VERSION "canboat-NMEA2000-curated"

NS_ :

BS_:

BU_: Vector__XXX
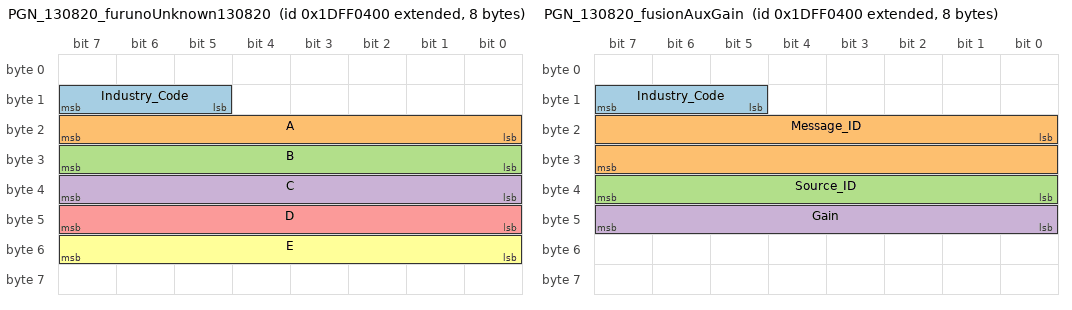
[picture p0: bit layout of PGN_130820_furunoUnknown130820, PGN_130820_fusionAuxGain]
BO_ 2650735616 PGN_130820_furunoUnknown130820: 8 Vector__XXX
 SG_ Industry_Code : 13|3@1+ (1.0,0) [0|7] "" Vector__XXX
 SG_ A : 16|8@1+ (1.0,0) [0|255] "" Vector__XXX
 SG_ B : 24|8@1+ (1.0,0) [0|255] "" Vector__XXX
 SG_ C : 32|8@1+ (1.0,0) [0|255] "" Vector__XXX
 SG_ D : 40|8@1+ (1.0,0) [0|255] "" Vector__XXX
 SG_ E : 48|8@1+ (1.0,0) [0|255] "" Vector__XXX

BO_ 2650735616 PGN_130820_fusionAlbumName: 10 Vector__XXX
 SG_ Industry_Code : 13|3@1+ (1.0,0) [0|7] "" Vector__XXX
 SG_ Message_ID : 16|16@1+ (1.0,0) [0|65535] "" Vector__XXX
 SG_ Source_ID : 32|8@1+ (1.0,0) [0|255] "" Vector__XXX
 SG_ Index : 40|32@1+ (1.0,0) [0|4294967295] "" Vector__XXX
 SG_ Album : 72|8@1+ (1.0,0) [0|255] "" Vector__XXX

BO_ 2650735616 PGN_130820_fusionArtistName: 10 Vector__XXX
 SG_ Industry_Code : 13|3@1+ (1.0,0) [0|7] "" Vector__XXX
 SG_ Message_ID : 16|16@1+ (1.0,0) [0|65535] "" Vector__XXX
 SG_ Source_ID : 32|8@1+ (1.0,0) [0|255] "" Vector__XXX
 SG_ Index : 40|32@1+ (1.0,0) [0|4294967295] "" Vector__XXX
 SG_ Artist : 72|8@1+ (1.0,0) [0|255] "" Vector__XXX

BO_ 2650735616 PGN_130820_fusionAuxGain: 8 Vector__XXX
 SG_ Industry_Code : 13|3@1+ (1.0,0) [0|7] "" Vector__XXX
 SG_ Message_ID : 16|16@1+ (1.0,0) [0|65535] "" Vector__XXX
 SG_ Source_ID : 32|8@1+ (1.0,0) [0|255] "" Vector__XXX
 SG_ Gain : 40|8@1+ (1.0,0) [0|255] "" Vector__XXX

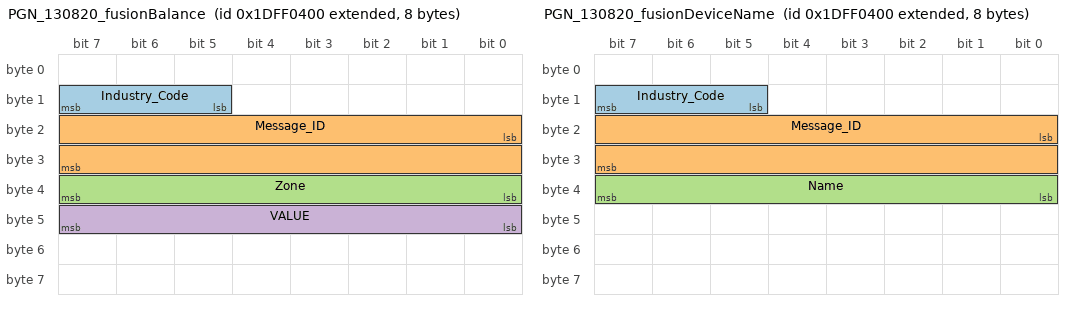
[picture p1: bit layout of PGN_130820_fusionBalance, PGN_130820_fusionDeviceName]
BO_ 2650735616 PGN_130820_fusionBalance: 8 Vector__XXX
 SG_ Industry_Code : 13|3@1+ (1.0,0) [0|7] "" Vector__XXX
 SG_ Message_ID : 16|16@1+ (1.0,0) [0|65535] "" Vector__XXX
 SG_ Zone : 32|8@1+ (1.0,0) [0|255] "" Vector__XXX
 SG_ VALUE : 40|8@1+ (1.0,0) [0|255] "" Vector__XXX

BO_ 2650735616 PGN_130820_fusionCapabilities: 14 Vector__XXX
 SG_ Industry_Code : 13|3@1+ (1.0,0) [0|7] "" Vector__XXX
 SG_ Message_ID : 16|16@1+ (1.0,0) [0|65535] "" Vector__XXX
 SG_ Zone_1 : 32|16@1+ (1.0,0) [0|65535] "" Vector__XXX
 SG_ Zone_2 : 48|16@1+ (1.0,0) [0|65535] "" Vector__XXX
 SG_ Zone_3 : 64|16@1+ (1.0,0) [0|65535] "" Vector__XXX
 SG_ Zone_4 : 80|16@1+ (1.0,0) [0|65535] "" Vector__XXX
 SG_ Global : 96|16@1+ (1.0,0) [0|65535] "" Vector__XXX

BO_ 2650735616 PGN_130820_fusionDeviceName: 8 Vector__XXX
 SG_ Industry_Code : 13|3@1+ (1.0,0) [0|7] "" Vector__XXX
 SG_ Message_ID : 16|16@1+ (1.0,0) [0|65535] "" Vector__XXX
 SG_ Name : 32|8@1+ (1.0,0) [0|255] "" Vector__XXX

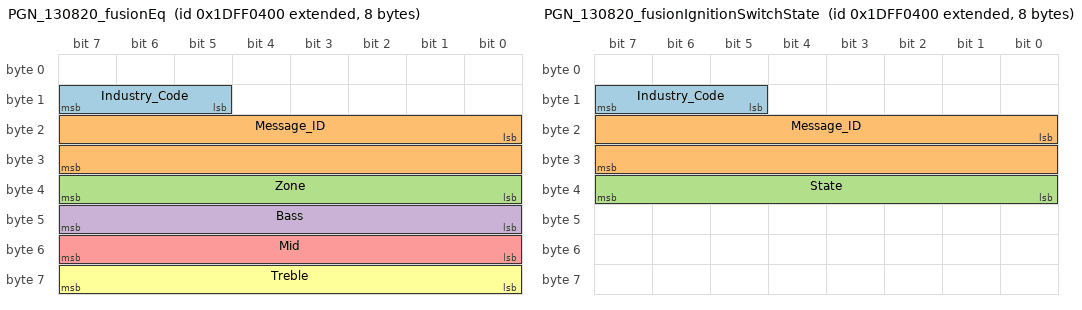
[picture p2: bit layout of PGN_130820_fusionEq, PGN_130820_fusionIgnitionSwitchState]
BO_ 2650735616 PGN_130820_fusionEq: 8 Vector__XXX
 SG_ Industry_Code : 13|3@1+ (1.0,0) [0|7] "" Vector__XXX
 SG_ Message_ID : 16|16@1+ (1.0,0) [0|65535] "" Vector__XXX
 SG_ Zone : 32|8@1+ (1.0,0) [0|255] "" Vector__XXX
 SG_ Bass : 40|8@1- (1.0,0) [-128|127] "" Vector__XXX
 SG_ Mid : 48|8@1- (1.0,0) [-128|127] "" Vector__XXX
 SG_ Treble : 56|8@1- (1.0,0) [-128|127] "" Vector__XXX

BO_ 2650735616 PGN_130820_fusionIgnitionSwitchState: 8 Vector__XXX
 SG_ Industry_Code : 13|3@1+ (1.0,0) [0|7] "" Vector__XXX
 SG_ Message_ID : 16|16@1+ (1.0,0) [0|65535] "" Vector__XXX
 SG_ State : 32|8@1+ (1.0,0) [0|255] "" Vector__XXX

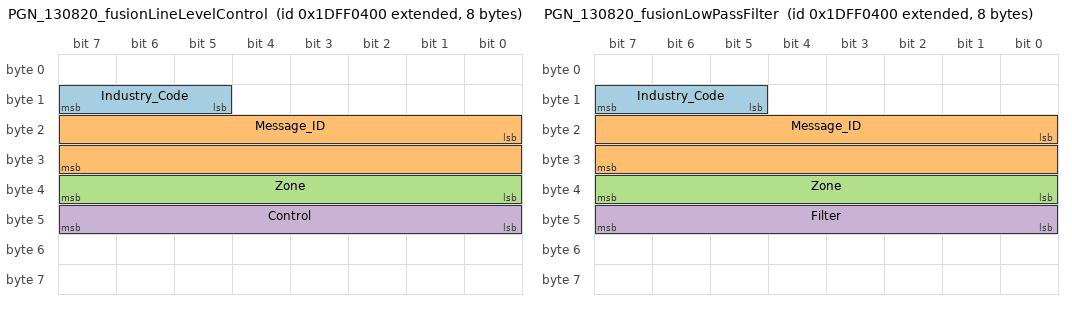
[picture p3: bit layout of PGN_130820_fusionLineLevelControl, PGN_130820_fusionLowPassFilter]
BO_ 2650735616 PGN_130820_fusionLineLevelControl: 8 Vector__XXX
 SG_ Industry_Code : 13|3@1+ (1.0,0) [0|7] "" Vector__XXX
 SG_ Message_ID : 16|16@1+ (1.0,0) [0|65535] "" Vector__XXX
 SG_ Zone : 32|8@1+ (1.0,0) [0|255] "" Vector__XXX
 SG_ Control : 40|8@1+ (1.0,0) [0|255] "" Vector__XXX

BO_ 2650735616 PGN_130820_fusionLowPassFilter: 8 Vector__XXX
 SG_ Industry_Code : 13|3@1+ (1.0,0) [0|7] "" Vector__XXX
 SG_ Message_ID : 16|16@1+ (1.0,0) [0|65535] "" Vector__XXX
 SG_ Zone : 32|8@1+ (1.0,0) [0|255] "" Vector__XXX
 SG_ Filter : 40|8@1+ (1.0,0) [0|255] "" Vector__XXX

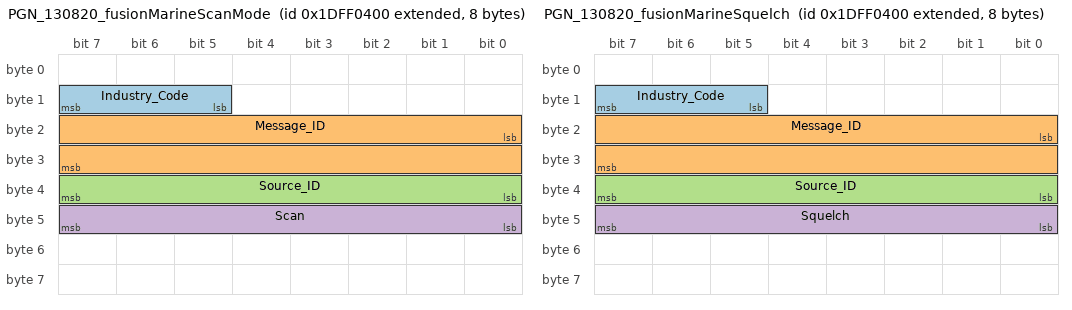
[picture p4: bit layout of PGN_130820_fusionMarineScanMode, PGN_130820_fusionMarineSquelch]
BO_ 2650735616 PGN_130820_fusionMarineScanMode: 8 Vector__XXX
 SG_ Industry_Code : 13|3@1+ (1.0,0) [0|7] "" Vector__XXX
 SG_ Message_ID : 16|16@1+ (1.0,0) [0|65535] "" Vector__XXX
 SG_ Source_ID : 32|8@1+ (1.0,0) [0|255] "" Vector__XXX
 SG_ Scan : 40|8@1+ (1.0,0) [0|255] "" Vector__XXX

BO_ 2650735616 PGN_130820_fusionMarineSquelch: 8 Vector__XXX
 SG_ Industry_Code : 13|3@1+ (1.0,0) [0|7] "" Vector__XXX
 SG_ Message_ID : 16|16@1+ (1.0,0) [0|65535] "" Vector__XXX
 SG_ Source_ID : 32|8@1+ (1.0,0) [0|255] "" Vector__XXX
 SG_ Squelch : 40|8@1+ (1.0,0) [0|255] "" Vector__XXX

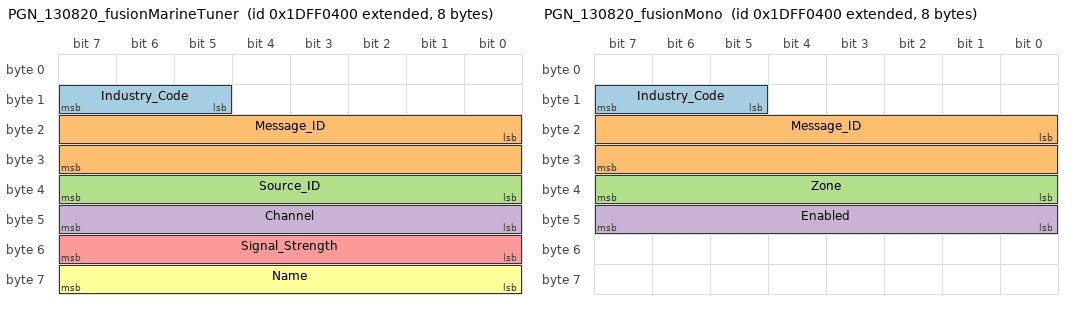
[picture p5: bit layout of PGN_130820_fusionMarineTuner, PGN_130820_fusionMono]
BO_ 2650735616 PGN_130820_fusionMarineTuner: 8 Vector__XXX
 SG_ Industry_Code : 13|3@1+ (1.0,0) [0|7] "" Vector__XXX
 SG_ Message_ID : 16|16@1+ (1.0,0) [0|65535] "" Vector__XXX
 SG_ Source_ID : 32|8@1+ (1.0,0) [0|255] "" Vector__XXX
 SG_ Channel : 40|8@1+ (1.0,0) [0|255] "" Vector__XXX
 SG_ Signal_Strength : 48|8@1+ (1.0,0) [0|255] "" Vector__XXX
 SG_ Name : 56|8@1+ (1.0,0) [0|255] "" Vector__XXX

BO_ 2650735616 PGN_130820_fusionMedia: 23 Vector__XXX
 SG_ Industry_Code : 13|3@1+ (1.0,0) [0|7] "" Vector__XXX
 SG_ Message_ID : 16|16@1+ (1.0,0) [0|65535] "" Vector__XXX
 SG_ Source_ID : 32|8@1+ (1.0,0) [0|255] "" Vector__XXX
 SG_ Flags : 40|16@1+ (1.0,0) [0|65535] "" Vector__XXX
 SG_ Track__ : 56|32@1+ (1.0,0) [0|4294967295] "" Vector__XXX
 SG_ Track_Count : 88|32@1+ (1.0,0) [0|4294967295] "" Vector__XXX
 SG_ Length : 120|32@1+ (0.001,0) [0.0|4294967.295] "" Vector__XXX
 SG_ Position_in_track : 152|32@1+ (0.001,0) [0.0|4294967.295] "" Vector__XXX

BO_ 2650735616 PGN_130820_fusionMenuActionStatus: 11 Vector__XXX
 SG_ Industry_Code : 13|3@1+ (1.0,0) [0|7] "" Vector__XXX
 SG_ Message_ID : 16|16@1+ (1.0,0) [0|65535] "" Vector__XXX
 SG_ Source_ID : 32|8@1+ (1.0,0) [0|255] "" Vector__XXX
 SG_ Item_Index : 40|32@1+ (1.0,0) [0|4294967295] "" Vector__XXX
 SG_ Action : 72|8@1+ (1.0,0) [0|255] "" Vector__XXX
 SG_ Lock_ID : 80|8@1+ (1.0,0) [0|255] "" Vector__XXX

BO_ 2650735616 PGN_130820_fusionMenuCount: 10 Vector__XXX
 SG_ Industry_Code : 13|3@1+ (1.0,0) [0|7] "" Vector__XXX
 SG_ Message_ID : 16|16@1+ (1.0,0) [0|65535] "" Vector__XXX
 SG_ Source_ID : 32|8@1+ (1.0,0) [0|255] "" Vector__XXX
 SG_ Count : 40|32@1+ (1.0,0) [0|4294967295] "" Vector__XXX
 SG_ Lock_ID : 72|8@1+ (1.0,0) [0|255] "" Vector__XXX

BO_ 2650735616 PGN_130820_fusionMenuItem: 12 Vector__XXX
 SG_ Industry_Code : 13|3@1+ (1.0,0) [0|7] "" Vector__XXX
 SG_ Message_ID : 16|16@1+ (1.0,0) [0|65535] "" Vector__XXX
 SG_ Source_ID : 32|8@1+ (1.0,0) [0|255] "" Vector__XXX
 SG_ Item_Index : 40|32@1+ (1.0,0) [0|4294967295] "" Vector__XXX
 SG_ Flags : 72|8@1+ (1.0,0) [0|255] "" Vector__XXX
 SG_ Lock_ID : 80|8@1+ (1.0,0) [0|255] "" Vector__XXX
 SG_ Text : 88|8@1+ (1.0,0) [0|255] "" Vector__XXX

BO_ 2650735616 PGN_130820_fusionMenuLockId: 9 Vector__XXX
 SG_ Industry_Code : 13|3@1+ (1.0,0) [0|7] "" Vector__XXX
 SG_ Message_ID : 16|16@1+ (1.0,0) [0|65535] "" Vector__XXX
 SG_ Lock_Id : 32|32@1+ (1.0,0) [0|4294967295] "" Vector__XXX
 SG_ Flags : 64|8@1+ (1.0,0) [0|255] "" Vector__XXX

BO_ 2650735616 PGN_130820_fusionMono: 8 Vector__XXX
 SG_ Industry_Code : 13|3@1+ (1.0,0) [0|7] "" Vector__XXX
 SG_ Message_ID : 16|16@1+ (1.0,0) [0|65535] "" Vector__XXX
 SG_ Zone : 32|8@1+ (1.0,0) [0|255] "" Vector__XXX
 SG_ Enabled : 40|8@1+ (1.0,0) [0|255] "" Vector__XXX

BO_ 2650735616 PGN_130820_fusionMultiroom: 9 Vector__XXX
 SG_ Industry_Code : 13|3@1+ (1.0,0) [0|7] "" Vector__XXX
 SG_ Message_ID : 16|16@1+ (1.0,0) [0|65535] "" Vector__XXX
 SG_ Enabled : 32|8@1+ (1.0,0) [0|255] "" Vector__XXX
 SG_ IP_Address_1 : 40|8@1+ (1.0,0) [0|255] "" Vector__XXX
 SG_ IP_Address_2 : 48|8@1+ (1.0,0) [0|255] "" Vector__XXX
 SG_ IP_Address_3 : 56|8@1+ (1.0,0) [0|255] "" Vector__XXX
 SG_ IP_Address_4 : 64|8@1+ (1.0,0) [0|255] "" Vector__XXX

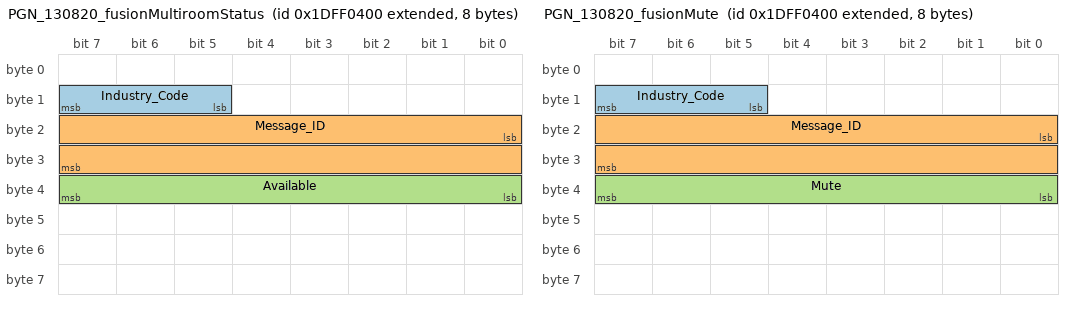
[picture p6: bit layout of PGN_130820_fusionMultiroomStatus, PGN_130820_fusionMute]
BO_ 2650735616 PGN_130820_fusionMultiroomStatus: 8 Vector__XXX
 SG_ Industry_Code : 13|3@1+ (1.0,0) [0|7] "" Vector__XXX
 SG_ Message_ID : 16|16@1+ (1.0,0) [0|65535] "" Vector__XXX
 SG_ Available : 32|8@1+ (1.0,0) [0|255] "" Vector__XXX

BO_ 2650735616 PGN_130820_fusionMute: 8 Vector__XXX
 SG_ Industry_Code : 13|3@1+ (1.0,0) [0|7] "" Vector__XXX
 SG_ Message_ID : 16|16@1+ (1.0,0) [0|65535] "" Vector__XXX
 SG_ Mute : 32|8@1+ (1.0,0) [0|255] "" Vector__XXX

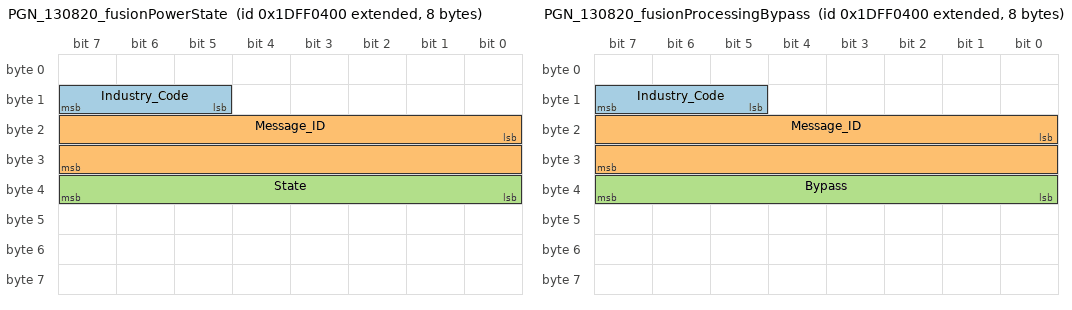
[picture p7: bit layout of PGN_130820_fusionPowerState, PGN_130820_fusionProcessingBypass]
BO_ 2650735616 PGN_130820_fusionPowerState: 8 Vector__XXX
 SG_ Industry_Code : 13|3@1+ (1.0,0) [0|7] "" Vector__XXX
 SG_ Message_ID : 16|16@1+ (1.0,0) [0|65535] "" Vector__XXX
 SG_ State : 32|8@1+ (1.0,0) [0|255] "" Vector__XXX

BO_ 2650735616 PGN_130820_fusionProcessingBypass: 8 Vector__XXX
 SG_ Industry_Code : 13|3@1+ (1.0,0) [0|7] "" Vector__XXX
 SG_ Message_ID : 16|16@1+ (1.0,0) [0|65535] "" Vector__XXX
 SG_ Bypass : 32|8@1+ (1.0,0) [0|255] "" Vector__XXX

BO_ 2650735616 PGN_130820_fusionRdsData: 39 Vector__XXX
 SG_ Industry_Code : 13|3@1+ (1.0,0) [0|7] "" Vector__XXX
 SG_ Message_ID : 16|16@1+ (1.0,0) [0|65535] "" Vector__XXX
 SG_ Source_ID : 32|8@1+ (1.0,0) [0|255] "" Vector__XXX
 SG_ RDS_Type : 40|8@1+ (1.0,0) [0|255] "" Vector__XXX
 SG_ Programme_Type : 48|8@1+ (1.0,0) [0|255] "" Vector__XXX
 SG_ RDS : 56|256@1+ (1.0,0) [0|115792089237316195423570985008687907853269984665640564039457584007913129639935] "" Vector__XXX

BO_ 2650735616 PGN_130820_fusionSetting: 12 Vector__XXX
 SG_ Industry_Code : 13|3@1+ (1.0,0) [0|7] "" Vector__XXX
 SG_ Message_ID : 16|16@1+ (1.0,0) [0|65535] "" Vector__XXX
 SG_ ID : 32|32@1+ (1.0,0) [0|4294967295] "" Vector__XXX
 SG_ Value : 64|32@1+ (1.0,0) [0|4294967295] "" Vector__XXX

BO_ 2650735616 PGN_130820_fusionSettings: 9 Vector__XXX
 SG_ Industry_Code : 13|3@1+ (1.0,0) [0|7] "" Vector__XXX
 SG_ Message_ID : 16|16@1+ (1.0,0) [0|65535] "" Vector__XXX
 SG_ Count : 32|32@1+ (1.0,0) [0|4294967295] "" Vector__XXX
 SG_ field64 : 64|8@1+ (1.0,0) [0|255] "" Vector__XXX

BO_ 2650735616 PGN_130820_fusionSiriusxm: 10 Vector__XXX
 SG_ Industry_Code : 13|3@1+ (1.0,0) [0|7] "" Vector__XXX
 SG_ Message_ID : 16|16@1+ (1.0,0) [0|65535] "" Vector__XXX
 SG_ Source_ID : 32|8@1+ (1.0,0) [0|255] "" Vector__XXX
 SG_ Com_State : 40|8@1+ (1.0,0) [0|255] "" Vector__XXX
 SG_ Alert : 48|8@1+ (1.0,0) [0|255] "" Vector__XXX
 SG_ Advisory_Channel : 56|16@1+ (1.0,0) [0|65535] "" Vector__XXX
 SG_ Tuning_Mode : 72|8@1+ (1.0,0) [0|255] "" Vector__XXX

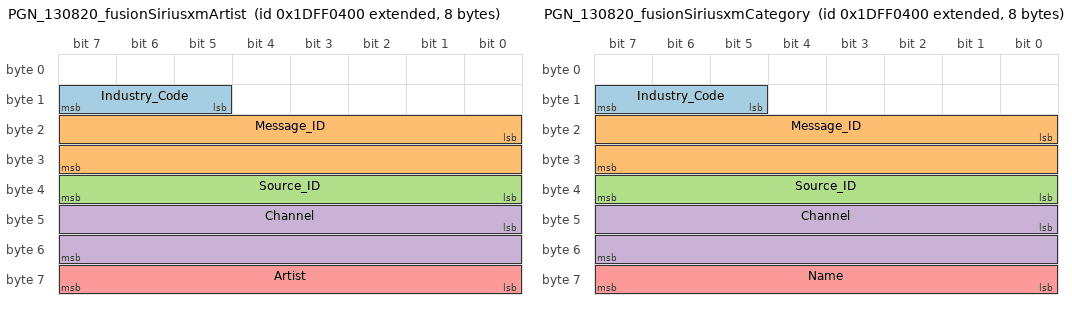
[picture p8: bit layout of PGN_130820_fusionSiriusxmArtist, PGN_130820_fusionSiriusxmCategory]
BO_ 2650735616 PGN_130820_fusionSiriusxmArtist: 8 Vector__XXX
 SG_ Industry_Code : 13|3@1+ (1.0,0) [0|7] "" Vector__XXX
 SG_ Message_ID : 16|16@1+ (1.0,0) [0|65535] "" Vector__XXX
 SG_ Source_ID : 32|8@1+ (1.0,0) [0|255] "" Vector__XXX
 SG_ Channel : 40|16@1+ (1.0,0) [0|65535] "" Vector__XXX
 SG_ Artist : 56|8@1+ (1.0,0) [0|255] "" Vector__XXX

BO_ 2650735616 PGN_130820_fusionSiriusxmCategory: 8 Vector__XXX
 SG_ Industry_Code : 13|3@1+ (1.0,0) [0|7] "" Vector__XXX
 SG_ Message_ID : 16|16@1+ (1.0,0) [0|65535] "" Vector__XXX
 SG_ Source_ID : 32|8@1+ (1.0,0) [0|255] "" Vector__XXX
 SG_ Channel : 40|16@1+ (1.0,0) [0|65535] "" Vector__XXX
 SG_ Name : 56|8@1+ (1.0,0) [0|255] "" Vector__XXX

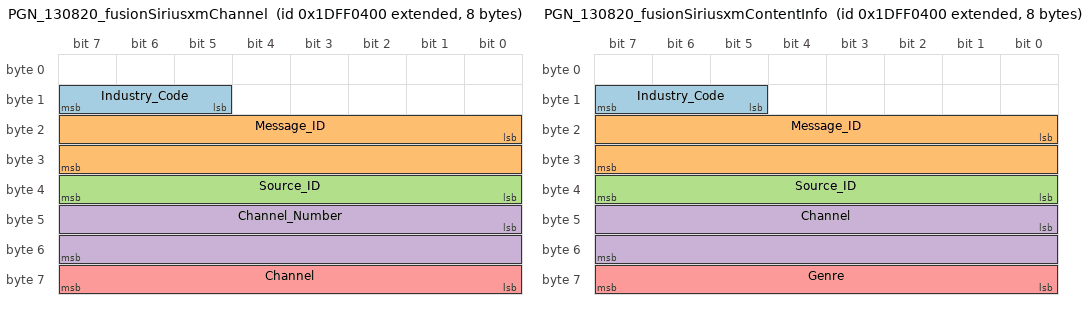
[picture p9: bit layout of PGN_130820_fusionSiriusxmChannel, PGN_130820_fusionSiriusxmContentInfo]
BO_ 2650735616 PGN_130820_fusionSiriusxmChannel: 8 Vector__XXX
 SG_ Industry_Code : 13|3@1+ (1.0,0) [0|7] "" Vector__XXX
 SG_ Message_ID : 16|16@1+ (1.0,0) [0|65535] "" Vector__XXX
 SG_ Source_ID : 32|8@1+ (1.0,0) [0|255] "" Vector__XXX
 SG_ Channel_Number : 40|16@1+ (1.0,0) [0|65535] "" Vector__XXX
 SG_ Channel : 56|8@1+ (1.0,0) [0|255] "" Vector__XXX

BO_ 2650735616 PGN_130820_fusionSiriusxmContentInfo: 8 Vector__XXX
 SG_ Industry_Code : 13|3@1+ (1.0,0) [0|7] "" Vector__XXX
 SG_ Message_ID : 16|16@1+ (1.0,0) [0|65535] "" Vector__XXX
 SG_ Source_ID : 32|8@1+ (1.0,0) [0|255] "" Vector__XXX
 SG_ Channel : 40|16@1+ (1.0,0) [0|65535] "" Vector__XXX
 SG_ Genre : 56|8@1+ (1.0,0) [0|255] "" Vector__XXX

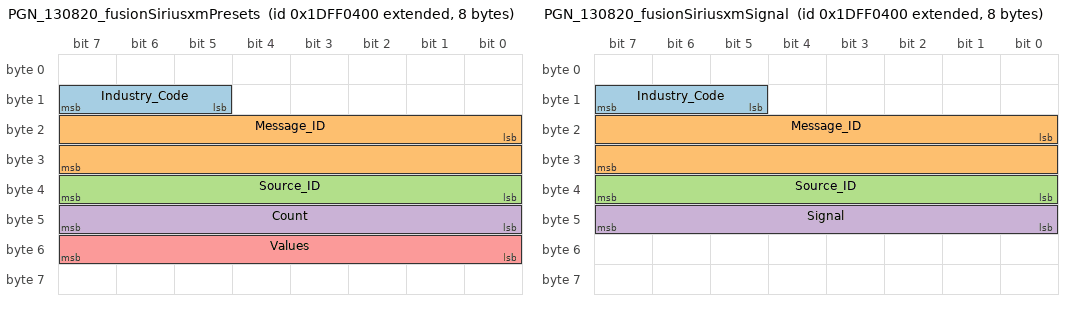
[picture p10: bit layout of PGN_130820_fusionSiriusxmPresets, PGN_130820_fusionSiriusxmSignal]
BO_ 2650735616 PGN_130820_fusionSiriusxmPresets: 8 Vector__XXX
 SG_ Industry_Code : 13|3@1+ (1.0,0) [0|7] "" Vector__XXX
 SG_ Message_ID : 16|16@1+ (1.0,0) [0|65535] "" Vector__XXX
 SG_ Source_ID : 32|8@1+ (1.0,0) [0|255] "" Vector__XXX
 SG_ Count : 40|8@1+ (1.0,0) [0|255] "" Vector__XXX
 SG_ Values : 48|8@1+ (1.0,0) [0|255] "" Vector__XXX

BO_ 2650735616 PGN_130820_fusionSiriusxmSignal: 8 Vector__XXX
 SG_ Industry_Code : 13|3@1+ (1.0,0) [0|7] "" Vector__XXX
 SG_ Message_ID : 16|16@1+ (1.0,0) [0|65535] "" Vector__XXX
 SG_ Source_ID : 32|8@1+ (1.0,0) [0|255] "" Vector__XXX
 SG_ Signal : 40|8@1+ (1.0,0) [0|255] "" Vector__XXX

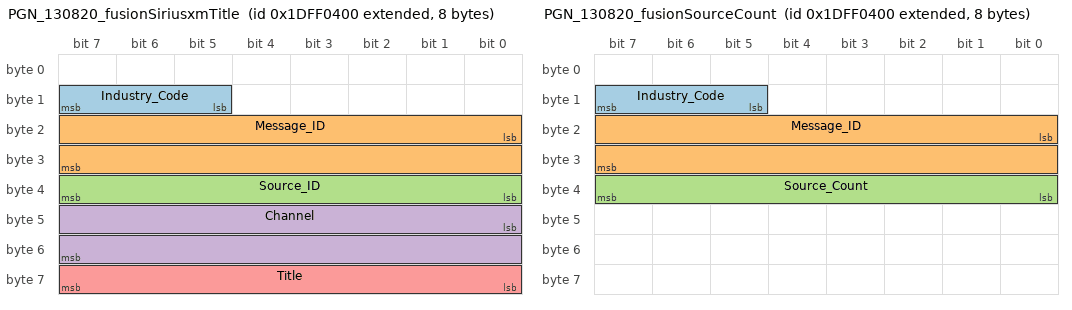
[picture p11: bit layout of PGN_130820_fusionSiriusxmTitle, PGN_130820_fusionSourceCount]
BO_ 2650735616 PGN_130820_fusionSiriusxmTitle: 8 Vector__XXX
 SG_ Industry_Code : 13|3@1+ (1.0,0) [0|7] "" Vector__XXX
 SG_ Message_ID : 16|16@1+ (1.0,0) [0|65535] "" Vector__XXX
 SG_ Source_ID : 32|8@1+ (1.0,0) [0|255] "" Vector__XXX
 SG_ Channel : 40|16@1+ (1.0,0) [0|65535] "" Vector__XXX
 SG_ Title : 56|8@1+ (1.0,0) [0|255] "" Vector__XXX

BO_ 2650735616 PGN_130820_fusionSource: 9 Vector__XXX
 SG_ Industry_Code : 13|3@1+ (1.0,0) [0|7] "" Vector__XXX
 SG_ Message_ID : 16|16@1+ (1.0,0) [0|65535] "" Vector__XXX
 SG_ Source_ID : 32|8@1+ (1.0,0) [0|255] "" Vector__XXX
 SG_ Current_Source_ID : 40|8@1+ (1.0,0) [0|255] "" Vector__XXX
 SG_ Source_Type : 48|8@1+ (1.0,0) [0|255] "" Vector__XXX
 SG_ Flags : 56|8@1+ (1.0,0) [0|255] "" Vector__XXX
 SG_ Source : 64|8@1+ (1.0,0) [0|255] "" Vector__XXX

BO_ 2650735616 PGN_130820_fusionSourceCount: 8 Vector__XXX
 SG_ Industry_Code : 13|3@1+ (1.0,0) [0|7] "" Vector__XXX
 SG_ Message_ID : 16|16@1+ (1.0,0) [0|65535] "" Vector__XXX
 SG_ Source_Count : 32|8@1+ (1.0,0) [0|255] "" Vector__XXX

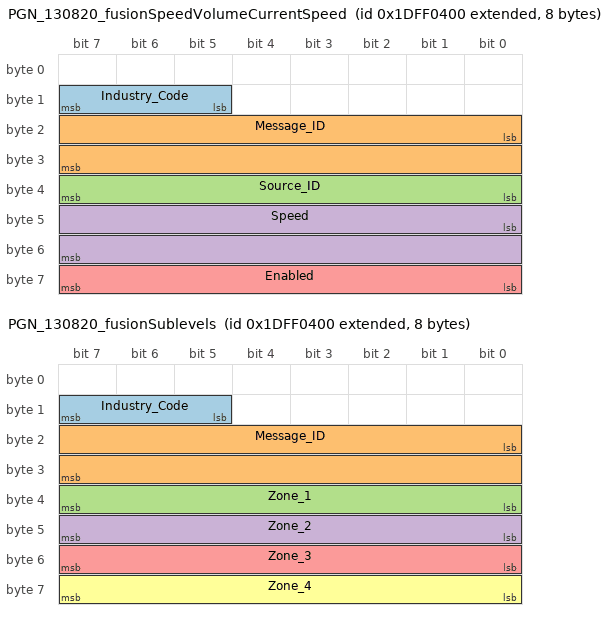
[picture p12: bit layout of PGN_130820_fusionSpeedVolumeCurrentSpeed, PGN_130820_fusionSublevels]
BO_ 2650735616 PGN_130820_fusionSpeedVolumeCurrentSpeed: 8 Vector__XXX
 SG_ Industry_Code : 13|3@1+ (1.0,0) [0|7] "" Vector__XXX
 SG_ Message_ID : 16|16@1+ (1.0,0) [0|65535] "" Vector__XXX
 SG_ Source_ID : 32|8@1+ (1.0,0) [0|255] "" Vector__XXX
 SG_ Speed : 40|16@1+ (1.0,0) [0|65535] "" Vector__XXX
 SG_ Enabled : 56|8@1+ (1.0,0) [0|255] "" Vector__XXX

BO_ 2650735616 PGN_130820_fusionSublevels: 8 Vector__XXX
 SG_ Industry_Code : 13|3@1+ (1.0,0) [0|7] "" Vector__XXX
 SG_ Message_ID : 16|16@1+ (1.0,0) [0|65535] "" Vector__XXX
 SG_ Zone_1 : 32|8@1+ (1.0,0) [0|255] "" Vector__XXX
 SG_ Zone_2 : 40|8@1+ (1.0,0) [0|255] "" Vector__XXX
 SG_ Zone_3 : 48|8@1+ (1.0,0) [0|255] "" Vector__XXX
 SG_ Zone_4 : 56|8@1+ (1.0,0) [0|255] "" Vector__XXX

BO_ 2650735616 PGN_130820_fusionTrackName: 10 Vector__XXX
 SG_ Industry_Code : 13|3@1+ (1.0,0) [0|7] "" Vector__XXX
 SG_ Message_ID : 16|16@1+ (1.0,0) [0|65535] "" Vector__XXX
 SG_ Source_ID : 32|8@1+ (1.0,0) [0|255] "" Vector__XXX
 SG_ Index : 40|32@1+ (1.0,0) [0|4294967295] "" Vector__XXX
 SG_ Track : 72|8@1+ (1.0,0) [0|255] "" Vector__XXX

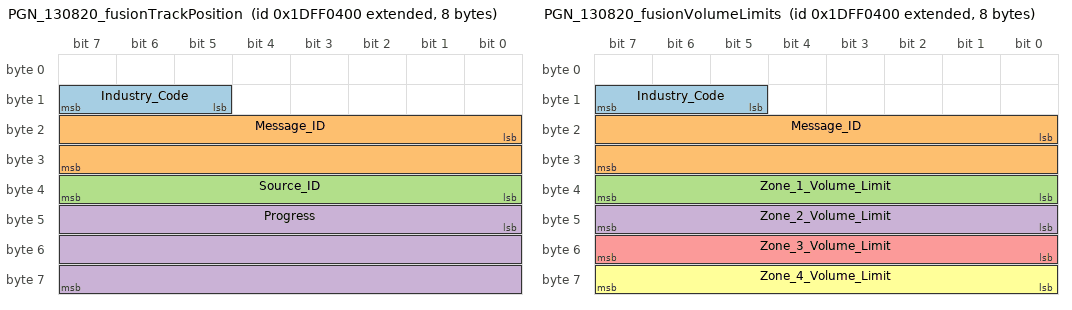
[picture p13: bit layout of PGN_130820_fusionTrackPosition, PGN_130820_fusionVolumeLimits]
BO_ 2650735616 PGN_130820_fusionTrackPosition: 8 Vector__XXX
 SG_ Industry_Code : 13|3@1+ (1.0,0) [0|7] "" Vector__XXX
 SG_ Message_ID : 16|16@1+ (1.0,0) [0|65535] "" Vector__XXX
 SG_ Source_ID : 32|8@1+ (1.0,0) [0|255] "" Vector__XXX
 SG_ Progress : 40|24@1+ (0.001,0) [0.0|16777.215] "" Vector__XXX

BO_ 2650735616 PGN_130820_fusionTuner: 12 Vector__XXX
 SG_ Industry_Code : 13|3@1+ (1.0,0) [0|7] "" Vector__XXX
 SG_ Message_ID : 16|16@1+ (1.0,0) [0|65535] "" Vector__XXX
 SG_ Source_ID : 32|8@1+ (1.0,0) [0|255] "" Vector__XXX
 SG_ Scanning : 40|8@1+ (1.0,0) [0|255] "" Vector__XXX
 SG_ Frequency : 48|32@1+ (1.0,0) [0|4294967295] "" Vector__XXX
 SG_ Signal_Strength : 80|8@1+ (1.0,0) [0|255] "" Vector__XXX
 SG_ Track : 88|8@1+ (1.0,0) [0|255] "" Vector__XXX

BO_ 2650735616 PGN_130820_fusionUsbRepeatStatus: 12 Vector__XXX
 SG_ Industry_Code : 13|3@1+ (1.0,0) [0|7] "" Vector__XXX
 SG_ Message_ID : 16|16@1+ (1.0,0) [0|65535] "" Vector__XXX
 SG_ ID : 32|32@1+ (1.0,0) [0|4294967295] "" Vector__XXX
 SG_ Status : 64|32@1+ (1.0,0) [0|4294967295] "" Vector__XXX

BO_ 2650735616 PGN_130820_fusionVersions: 11 Vector__XXX
 SG_ Industry_Code : 13|3@1+ (1.0,0) [0|7] "" Vector__XXX
 SG_ Message_ID : 16|16@1+ (1.0,0) [0|65535] "" Vector__XXX
 SG_ HW_Version_Major : 32|16@1+ (1.0,0) [0|65535] "" Vector__XXX
 SG_ HW_Version_Minor : 48|16@1+ (1.0,0) [0|65535] "" Vector__XXX
 SG_ SW_Version_Major : 64|8@1+ (1.0,0) [0|255] "" Vector__XXX
 SG_ SW_Version_Minor : 72|8@1+ (1.0,0) [0|255] "" Vector__XXX
 SG_ Build_Number : 80|8@1+ (1.0,0) [0|255] "" Vector__XXX

BO_ 2650735616 PGN_130820_fusionVolumeLimits: 8 Vector__XXX
 SG_ Industry_Code : 13|3@1+ (1.0,0) [0|7] "" Vector__XXX
 SG_ Message_ID : 16|16@1+ (1.0,0) [0|65535] "" Vector__XXX
 SG_ Zone_1_Volume_Limit : 32|8@1+ (1.0,0) [0|255] "" Vector__XXX
 SG_ Zone_2_Volume_Limit : 40|8@1+ (1.0,0) [0|255] "" Vector__XXX
 SG_ Zone_3_Volume_Limit : 48|8@1+ (1.0,0) [0|255] "" Vector__XXX
 SG_ Zone_4_Volume_Limit : 56|8@1+ (1.0,0) [0|255] "" Vector__XXX

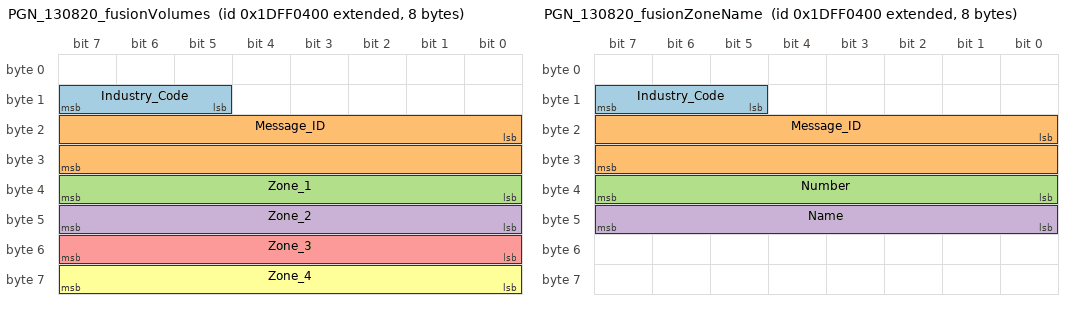
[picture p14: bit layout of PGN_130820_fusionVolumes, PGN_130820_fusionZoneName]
BO_ 2650735616 PGN_130820_fusionVolumes: 8 Vector__XXX
 SG_ Industry_Code : 13|3@1+ (1.0,0) [0|7] "" Vector__XXX
 SG_ Message_ID : 16|16@1+ (1.0,0) [0|65535] "" Vector__XXX
 SG_ Zone_1 : 32|8@1+ (1.0,0) [0|255] "" Vector__XXX
 SG_ Zone_2 : 40|8@1+ (1.0,0) [0|255] "" Vector__XXX
 SG_ Zone_3 : 48|8@1+ (1.0,0) [0|255] "" Vector__XXX
 SG_ Zone_4 : 56|8@1+ (1.0,0) [0|255] "" Vector__XXX

BO_ 2650735616 PGN_130820_fusionZoneName: 8 Vector__XXX
 SG_ Industry_Code : 13|3@1+ (1.0,0) [0|7] "" Vector__XXX
 SG_ Message_ID : 16|16@1+ (1.0,0) [0|65535] "" Vector__XXX
 SG_ Number : 32|8@1+ (1.0,0) [0|255] "" Vector__XXX
 SG_ Name : 40|8@1+ (1.0,0) [0|255] "" Vector__XXX

BO_ 2650735616 PGN_130820_maretronAlertResponse: 27 Vector__XXX
 SG_ Industry_Code : 13|3@1+ (1.0,0) [0|7] "" Vector__XXX
 SG_ Alert_Type : 16|4@1+ (1.0,0) [0|15] "" Vector__XXX
 SG_ Alert_Category : 20|4@1+ (1.0,0) [0|15] "" Vector__XXX
 SG_ Alert_System : 24|8@1+ (1.0,0) [0|255] "" Vector__XXX
 SG_ Alert_Sub_System : 32|8@1+ (1.0,0) [0|255] "" Vector__XXX
 SG_ Alert_ID : 40|16@1+ (1.0,0) [0|65535] "" Vector__XXX
 SG_ Data_Source_Network_ID_NAME : 56|64@1+ (1.0,0) [0|18446744073709551615] "" Vector__XXX
 SG_ Data_Source_Instance : 120|8@1+ (1.0,0) [0|255] "" Vector__XXX
 SG_ Data_Source_Index_Source : 128|8@1+ (1.0,0) [0|255] "" Vector__XXX
 SG_ Alert_Occurrence_Number : 136|8@1+ (1.0,0) [0|255] "" Vector__XXX
 SG_ Acknowledge_Source_Network_ID_NAME : 144|64@1+ (1.0,0) [0|18446744073709551615] "" Vector__XXX
 SG_ Response_Command : 208|2@1+ (1.0,0) [0|3] "" Vector__XXX

BO_ 2650735616 PGN_130820_simnetReprogramStatus: 8 Vector__XXX
 SG_ Industry_Code : 13|3@1+ (1.0,0) [0|7] "" Vector__XXX
 SG_ Status : 24|8@1+ (1.0,0) [0|255] "" Vector__XXX

BO_ 2583627008 PGN_130821_bepMarineProprietaryPgn130821: 223 Vector__XXX
 SG_ Manufacturer_Code : 0|11@1+ (1.0,0) [0|2047] "" Vector__XXX
 SG_ Industry_Code : 13|3@1+ (1.0,0) [0|7] "" Vector__XXX
 SG_ Data : 16|1768@1+ (1.0,0) [0|16635364987126134419907490844611231857889171561340108669757218330385068731224834608417815051548234195819468783937845710359164977421616154908223175941492902641772198991471137845920843845811776377869137773379678289214194183661112800944378464511794046030758602257005203964634516091405743061582849883160885255175229773660916874237270946647032424101972117051870087763059119895517977437771543686400460392041962138103436564399831189767740372774280024852942859855049773927338342604171805121253257539126169331943684033945189625789470637817855] "" Vector__XXX

BO_ 2650735872 PGN_130821_furunoUnknown130821: 12 Vector__XXX
 SG_ Manufacturer_Code : 0|11@1+ (1.0,0) [0|2047] "" Vector__XXX
 SG_ Industry_Code : 13|3@1+ (1.0,0) [0|7] "" Vector__XXX
 SG_ SID : 16|8@1+ (1.0,0) [0|255] "" Vector__XXX
 SG_ A : 24|8@1+ (1.0,0) [0|255] "" Vector__XXX
 SG_ B : 32|8@1+ (1.0,0) [0|255] "" Vector__XXX
 SG_ C : 40|8@1+ (1.0,0) [0|255] "" Vector__XXX
 SG_ D : 48|8@1+ (1.0,0) [0|255] "" Vector__XXX
 SG_ E : 56|8@1+ (1.0,0) [0|255] "" Vector__XXX
 SG_ F : 64|8@1+ (1.0,0) [0|255] "" Vector__XXX
 SG_ G : 72|8@1+ (1.0,0) [0|255] "" Vector__XXX
 SG_ H : 80|8@1+ (1.0,0) [0|255] "" Vector__XXX
 SG_ I : 88|8@1+ (1.0,0) [0|255] "" Vector__XXX

BO_ 2650735872 PGN_130821_maretronAlertText: 21 Vector__XXX
 SG_ Manufacturer_Code : 0|11@1+ (1.0,0) [0|2047] "" Vector__XXX
 SG_ Industry_Code : 13|3@1+ (1.0,0) [0|7] "" Vector__XXX
 SG_ Alert_Type : 16|4@1+ (1.0,0) [0|15] "" Vector__XXX
 SG_ Alert_Category : 20|4@1+ (1.0,0) [0|15] "" Vector__XXX
 SG_ Alert_System : 24|8@1+ (1.0,0) [0|255] "" Vector__XXX
 SG_ Alert_Sub_System : 32|8@1+ (1.0,0) [0|255] "" Vector__XXX
 SG_ Alert_ID : 40|16@1+ (1.0,0) [0|65535] "" Vector__XXX
 SG_ Data_Source_Network_ID_NAME : 56|64@1+ (1.0,0) [0|18446744073709551615] "" Vector__XXX
 SG_ Data_Source_Instance : 120|8@1+ (1.0,0) [0|255] "" Vector__XXX
 SG_ Data_Source_Index_Source : 128|8@1+ (1.0,0) [0|255] "" Vector__XXX
 SG_ Alert_Occurrence_Number : 136|8@1+ (1.0,0) [0|255] "" Vector__XXX
 SG_ Language_ID : 144|8@1+ (1.0,0) [0|255] "" Vector__XXX
 SG_ Alert_Text_Description : 152|8@1+ (1.0,0) [0|255] "" Vector__XXX
 SG_ Alert_Location_Text_Description : 160|8@1+ (1.0,0) [0|255] "" Vector__XXX

BO_ 2650735872 PGN_130821_navicoAsciiData: 233 Vector__XXX
 SG_ Manufacturer_Code : 0|11@1+ (1.0,0) [0|2047] "" Vector__XXX
 SG_ Industry_Code : 13|3@1+ (1.0,0) [0|7] "" Vector__XXX
 SG_ A : 16|8@1+ (1.0,0) [0|255] "" Vector__XXX
 SG_ Message : 24|1840@1+ (1.0,0) [0|78558290045507684229937911761820822518539509311115967890245119697213329156968677187519553731966250623581153291188259194332429956051299859910253308366542459585693686907928812162068026756049614215920211545973675776982248677528000730767279520555557817043079049804410450150947110685152779469171010248108467517137658809470158466727547400937720053751072802806732400499275833568149261616783995359536794035935069525162839982125101412216829762279337846135999793026492115169262232819130168004541779841853581966176686003285360374700086678625131261034418800244555775] "" Vector__XXX

BO_ 2583627264 PGN_130822_bepMarineProprietaryPgn130822: 223 Vector__XXX
 SG_ Manufacturer_Code : 0|11@1+ (1.0,0) [0|2047] "" Vector__XXX
 SG_ Industry_Code : 13|3@1+ (1.0,0) [0|7] "" Vector__XXX
 SG_ Data : 16|1768@1+ (1.0,0) [0|16635364987126134419907490844611231857889171561340108669757218330385068731224834608417815051548234195819468783937845710359164977421616154908223175941492902641772198991471137845920843845811776377869137773379678289214194183661112800944378464511794046030758602257005203964634516091405743061582849883160885255175229773660916874237270946647032424101972117051870087763059119895517977437771543686400460392041962138103436564399831189767740372774280024852942859855049773927338342604171805121253257539126169331943684033945189625789470637817855] "" Vector__XXX

BO_ 2650736128 PGN_130822_maretronAlertControl: 34 Vector__XXX
 SG_ Manufacturer_Code : 0|11@1+ (1.0,0) [0|2047] "" Vector__XXX
 SG_ Industry_Code : 13|3@1+ (1.0,0) [0|7] "" Vector__XXX
 SG_ Alert_Type : 16|4@1+ (1.0,0) [0|15] "" Vector__XXX
 SG_ Alert_Category : 20|4@1+ (1.0,0) [0|15] "" Vector__XXX
 SG_ Alert_System : 24|8@1+ (1.0,0) [0|255] "" Vector__XXX
 SG_ Alert_Sub_System : 32|8@1+ (1.0,0) [0|255] "" Vector__XXX
 SG_ Alert_ID : 40|16@1+ (1.0,0) [0|65535] "" Vector__XXX
 SG_ Data_Source_Network_ID_NAME : 56|64@1+ (1.0,0) [0|18446744073709551615] "" Vector__XXX
 SG_ Data_Source_Instance : 120|8@1+ (1.0,0) [0|255] "" Vector__XXX
 SG_ Data_Source_Index_Source : 128|8@1+ (1.0,0) [0|255] "" Vector__XXX
 SG_ Alert_Occurrence_Number : 136|8@1+ (1.0,0) [0|255] "" Vector__XXX
 SG_ Maretron_Extension : 144|128@1+ (1.0,0) [0|340282366920938463463374607431768211455] "" Vector__XXX

BO_ 2583627264 PGN_130822_mercuryEngineTelemetryLowSpeed: 9 Vector__XXX
 SG_ Manufacturer_Code : 0|11@1+ (1.0,0) [0|2047] "" Vector__XXX
 SG_ Industry_Code : 13|3@1+ (1.0,0) [0|7] "" Vector__XXX
 SG_ Engine_Instance : 16|8@1+ (1.0,0) [0|255] "" Vector__XXX
 SG_ Malfunction_Indicator : 24|8@1+ (1.0,0) [0|255] "" Vector__XXX
 SG_ Intake_Air_Temperature : 32|8@1+ (1.0,0) [0|255] "" Vector__XXX
 SG_ Exhaust_Gas_Temperature : 40|16@1+ (1.0,0) [0|65535] "" Vector__XXX
 SG_ GPL : 56|8@1+ (1.0,0) [0|255] "" Vector__XXX
 SG_ Engine_State : 64|8@1+ (1.0,0) [0|255] "" Vector__XXX

CM_ BO_ 2583627008 "NMEA2000: PGN 130821 - BEP Marine: Proprietary PGN 130821 (type: Fast)";
CM_ BO_ 2650735872 "NMEA2000: PGN 130821 - Furuno: Unknown 130821 (type: Fast)";
CM_ BO_ 2650735872 "NMEA2000: PGN 130821 - Maretron: Alert Text (type: Fast)";
CM_ BO_ 2650735872 "NMEA2000: PGN 130821 - Navico: ASCII Data (type: Fast)";
CM_ BO_ 2583627264 "NMEA2000: PGN 130822 - BEP Marine: Proprietary PGN 130822 (type: Fast)";
CM_ BO_ 2650736128 "NMEA2000: PGN 130822 - Maretron: Alert Control (type: Fast)";
CM_ BO_ 2583627264 "NMEA2000: PGN 130822 - Mercury: Engine Telemetry, Low Speed (type: Fast)";
CM_ SG_ 2650735616 Industry_Code "Marine Industry; canboat type: LOOKUP";
CM_ SG_ 2650735616 A "canboat type: UINT8";
CM_ SG_ 2650735616 B "canboat type: UINT8";
CM_ SG_ 2650735616 C "canboat type: UINT8";
CM_ SG_ 2650735616 D "canboat type: UINT8";
CM_ SG_ 2650735616 E "canboat type: UINT8";
CM_ SG_ 2650735616 Industry_Code "Marine Industry; canboat type: LOOKUP";
CM_ SG_ 2650735616 Message_ID "Track Album; canboat type: LOOKUP";
CM_ SG_ 2650735616 Source_ID "canboat type: UINT8";
CM_ SG_ 2650735616 Index "canboat type: UINT32";
CM_ SG_ 2650735616 Album "canboat type: STRING_LZ";
CM_ SG_ 2650735616 Industry_Code "Marine Industry; canboat type: LOOKUP";
CM_ SG_ 2650735616 Message_ID "Track Artist; canboat type: LOOKUP";
CM_ SG_ 2650735616 Source_ID "canboat type: UINT8";
CM_ SG_ 2650735616 Index "canboat type: UINT32";
CM_ SG_ 2650735616 Artist "canboat type: STRING_LZ";
CM_ SG_ 2650735616 Industry_Code "Marine Industry; canboat type: LOOKUP";
CM_ SG_ 2650735616 Message_ID "Aux Gain; canboat type: LOOKUP";
CM_ SG_ 2650735616 Source_ID "canboat type: UINT8";
CM_ SG_ 2650735616 Gain "canboat type: UINT8";
CM_ SG_ 2650735616 Industry_Code "Marine Industry; canboat type: LOOKUP";
CM_ SG_ 2650735616 Message_ID "Balance; canboat type: LOOKUP";
CM_ SG_ 2650735616 Zone "canboat type: UINT8";
CM_ SG_ 2650735616 VALUE "canboat type: UINT8";
CM_ SG_ 2650735616 Industry_Code "Marine Industry; canboat type: LOOKUP";
CM_ SG_ 2650735616 Message_ID "Capabilities; canboat type: LOOKUP";
CM_ SG_ 2650735616 Zone_1 "canboat type: UINT16";
CM_ SG_ 2650735616 Zone_2 "canboat type: UINT16";
CM_ SG_ 2650735616 Zone_3 "canboat type: UINT16";
CM_ SG_ 2650735616 Zone_4 "canboat type: UINT16";
CM_ SG_ 2650735616 Global "canboat type: UINT16";
CM_ SG_ 2650735616 Industry_Code "Marine Industry; canboat type: LOOKUP";
CM_ SG_ 2650735616 Message_ID "Unit Name; canboat type: LOOKUP";
CM_ SG_ 2650735616 Name "canboat type: STRING_LZ";
CM_ SG_ 2650735616 Industry_Code "Marine Industry; canboat type: LOOKUP";
CM_ SG_ 2650735616 Message_ID "Tone; canboat type: LOOKUP";
CM_ SG_ 2650735616 Zone "canboat type: UINT8";
CM_ SG_ 2650735616 Bass "canboat type: INT8";
CM_ SG_ 2650735616 Mid "canboat type: INT8";
CM_ SG_ 2650735616 Treble "canboat type: INT8";
CM_ SG_ 2650735616 Industry_Code "Marine Industry; canboat type: LOOKUP";
CM_ SG_ 2650735616 Message_ID "Ignition Switch State; canboat type: LOOKUP";
CM_ SG_ 2650735616 State "canboat type: UINT8";
CM_ SG_ 2650735616 Industry_Code "Marine Industry; canboat type: LOOKUP";
CM_ SG_ 2650735616 Message_ID "Line Level Control; canboat type: LOOKUP";
CM_ SG_ 2650735616 Zone "canboat type: UINT8";
CM_ SG_ 2650735616 Control "canboat type: UINT8";
CM_ SG_ 2650735616 Industry_Code "Marine Industry; canboat type: LOOKUP";
CM_ SG_ 2650735616 Message_ID "Low Pass Filter; canboat type: LOOKUP";
CM_ SG_ 2650735616 Zone "canboat type: UINT8";
CM_ SG_ 2650735616 Filter "canboat type: UINT8";
CM_ SG_ 2650735616 Industry_Code "Marine Industry; canboat type: LOOKUP";
CM_ SG_ 2650735616 Message_ID "Marine Scan Mode; canboat type: LOOKUP";
CM_ SG_ 2650735616 Source_ID "canboat type: UINT8";
CM_ SG_ 2650735616 Scan "canboat type: LOOKUP";
CM_ SG_ 2650735616 Industry_Code "Marine Industry; canboat type: LOOKUP";
CM_ SG_ 2650735616 Message_ID "Marine Squelch; canboat type: LOOKUP";
CM_ SG_ 2650735616 Source_ID "canboat type: UINT8";
CM_ SG_ 2650735616 Squelch "canboat type: UINT8";
CM_ SG_ 2650735616 Industry_Code "Marine Industry; canboat type: LOOKUP";
CM_ SG_ 2650735616 Message_ID "Marine Tuner; canboat type: LOOKUP";
CM_ SG_ 2650735616 Source_ID "canboat type: UINT8";
CM_ SG_ 2650735616 Channel "canboat type: UINT8";
CM_ SG_ 2650735616 Signal_Strength "canboat type: UINT8";
CM_ SG_ 2650735616 Name "canboat type: STRING_LZ";
CM_ SG_ 2650735616 Industry_Code "Marine Industry; canboat type: LOOKUP";
CM_ SG_ 2650735616 Message_ID "Track Info; canboat type: LOOKUP";
CM_ SG_ 2650735616 Source_ID "canboat type: UINT8";
CM_ SG_ 2650735616 Flags "canboat type: LOOKUP";
CM_ SG_ 2650735616 Track__ "canboat type: UINT32";
CM_ SG_ 2650735616 Track_Count "canboat type: UINT32";
CM_ SG_ 2650735616 Length "canboat type: DURATION_UFIX32_MS";
CM_ SG_ 2650735616 Position_in_track "canboat type: DURATION_UFIX32_MS";
CM_ SG_ 2650735616 Industry_Code "Marine Industry; canboat type: LOOKUP";
CM_ SG_ 2650735616 Message_ID "Menu Action; canboat type: LOOKUP";
CM_ SG_ 2650735616 Source_ID "Runtime source identifier announced by Fusion Source status messages; not a stable source-type enumeration.; canboat type: UINT8";
CM_ SG_ 2650735616 Item_Index "canboat type: UINT32";
CM_ SG_ 2650735616 Action "canboat type: LOOKUP";
CM_ SG_ 2650735616 Lock_ID "canboat type: UINT8";
CM_ SG_ 2650735616 Industry_Code "Marine Industry; canboat type: LOOKUP";
CM_ SG_ 2650735616 Message_ID "Menu Count; canboat type: LOOKUP";
CM_ SG_ 2650735616 Source_ID "Runtime source identifier announced by Fusion Source status messages; not a stable source-type enumeration.; canboat type: UINT8";
CM_ SG_ 2650735616 Count "canboat type: UINT32";
CM_ SG_ 2650735616 Lock_ID "canboat type: UINT8";
CM_ SG_ 2650735616 Industry_Code "Marine Industry; canboat type: LOOKUP";
CM_ SG_ 2650735616 Message_ID "Menu Item; canboat type: LOOKUP";
CM_ SG_ 2650735616 Source_ID "canboat type: UINT8";
CM_ SG_ 2650735616 Item_Index "canboat type: UINT32";
CM_ SG_ 2650735616 Flags "canboat type: UINT8";
CM_ SG_ 2650735616 Lock_ID "canboat type: UINT8";
CM_ SG_ 2650735616 Text "canboat type: STRING_LZ";
CM_ SG_ 2650735616 Industry_Code "Marine Industry; canboat type: LOOKUP";
CM_ SG_ 2650735616 Message_ID "Menu Lock ID; canboat type: LOOKUP";
CM_ SG_ 2650735616 Lock_Id "canboat type: UINT32";
CM_ SG_ 2650735616 Flags "canboat type: UINT8";
CM_ SG_ 2650735616 Industry_Code "Marine Industry; canboat type: LOOKUP";
CM_ SG_ 2650735616 Message_ID "Mono; canboat type: LOOKUP";
CM_ SG_ 2650735616 Zone "canboat type: UINT8";
CM_ SG_ 2650735616 Enabled "canboat type: LOOKUP";
CM_ SG_ 2650735616 Industry_Code "Marine Industry; canboat type: LOOKUP";
CM_ SG_ 2650735616 Message_ID "Multiroom; canboat type: LOOKUP";
CM_ SG_ 2650735616 Enabled "canboat type: LOOKUP";
CM_ SG_ 2650735616 IP_Address_1 "canboat type: UINT8";
CM_ SG_ 2650735616 IP_Address_2 "canboat type: UINT8";
CM_ SG_ 2650735616 IP_Address_3 "canboat type: UINT8";
CM_ SG_ 2650735616 IP_Address_4 "canboat type: UINT8";
CM_ SG_ 2650735616 Industry_Code "Marine Industry; canboat type: LOOKUP";
CM_ SG_ 2650735616 Message_ID "Multiroom Status; canboat type: LOOKUP";
CM_ SG_ 2650735616 Available "canboat type: LOOKUP";
CM_ SG_ 2650735616 Industry_Code "Marine Industry; canboat type: LOOKUP";
CM_ SG_ 2650735616 Message_ID "Mute; canboat type: LOOKUP";
CM_ SG_ 2650735616 Mute "canboat type: LOOKUP";
CM_ SG_ 2650735616 Industry_Code "Marine Industry; canboat type: LOOKUP";
CM_ SG_ 2650735616 Message_ID "Power; canboat type: LOOKUP";
CM_ SG_ 2650735616 State "canboat type: LOOKUP";
CM_ SG_ 2650735616 Industry_Code "Marine Industry; canboat type: LOOKUP";
CM_ SG_ 2650735616 Message_ID "Processing Bypass; canboat type: LOOKUP";
CM_ SG_ 2650735616 Bypass "canboat type: LOOKUP";
CM_ SG_ 2650735616 Industry_Code "Marine Industry; canboat type: LOOKUP";
CM_ SG_ 2650735616 Message_ID "RDS Data; canboat type: LOOKUP";
CM_ SG_ 2650735616 Source_ID "canboat type: UINT8";
CM_ SG_ 2650735616 RDS_Type "canboat type: UINT8";
CM_ SG_ 2650735616 Programme_Type "canboat type: UINT8";
CM_ SG_ 2650735616 RDS "canboat type: STRING_LZ";
CM_ SG_ 2650735616 Industry_Code "Marine Industry; canboat type: LOOKUP";
CM_ SG_ 2650735616 Message_ID "Setting; canboat type: LOOKUP";
CM_ SG_ 2650735616 ID "canboat type: LOOKUP";
CM_ SG_ 2650735616 Value "canboat type: UINT32";
CM_ SG_ 2650735616 Industry_Code "Marine Industry; canboat type: LOOKUP";
CM_ SG_ 2650735616 Message_ID "Settings; canboat type: LOOKUP";
CM_ SG_ 2650735616 Count "canboat type: UINT32";
CM_ SG_ 2650735616 field64 "canboat type: NUMBER";
CM_ SG_ 2650735616 Industry_Code "Marine Industry; canboat type: LOOKUP";
CM_ SG_ 2650735616 Message_ID "Sirius; canboat type: LOOKUP";
CM_ SG_ 2650735616 Source_ID "canboat type: UINT8";
CM_ SG_ 2650735616 Com_State "canboat type: LOOKUP";
CM_ SG_ 2650735616 Alert "canboat type: LOOKUP";
CM_ SG_ 2650735616 Advisory_Channel "canboat type: UINT16";
CM_ SG_ 2650735616 Tuning_Mode "canboat type: LOOKUP";
CM_ SG_ 2650735616 Industry_Code "Marine Industry; canboat type: LOOKUP";
CM_ SG_ 2650735616 Message_ID "SiriusXM Artist; canboat type: LOOKUP";
CM_ SG_ 2650735616 Source_ID "canboat type: UINT8";
CM_ SG_ 2650735616 Channel "canboat type: UINT16";
CM_ SG_ 2650735616 Artist "canboat type: STRING_LZ";
CM_ SG_ 2650735616 Industry_Code "Marine Industry; canboat type: LOOKUP";
CM_ SG_ 2650735616 Message_ID "SiriusXM Category; canboat type: LOOKUP";
CM_ SG_ 2650735616 Source_ID "canboat type: UINT8";
CM_ SG_ 2650735616 Channel "canboat type: UINT16";
CM_ SG_ 2650735616 Name "canboat type: STRING_LZ";
CM_ SG_ 2650735616 Industry_Code "Marine Industry; canboat type: LOOKUP";
CM_ SG_ 2650735616 Message_ID "SiriusXM Channel; canboat type: LOOKUP";
CM_ SG_ 2650735616 Source_ID "canboat type: UINT8";
CM_ SG_ 2650735616 Channel_Number "canboat type: UINT16";
CM_ SG_ 2650735616 Channel "canboat type: STRING_LZ";
CM_ SG_ 2650735616 Industry_Code "Marine Industry; canboat type: LOOKUP";
CM_ SG_ 2650735616 Message_ID "SiriusXM Genre; canboat type: LOOKUP";
CM_ SG_ 2650735616 Source_ID "canboat type: UINT8";
CM_ SG_ 2650735616 Channel "canboat type: UINT16";
CM_ SG_ 2650735616 Genre "canboat type: STRING_LZ";
CM_ SG_ 2650735616 Industry_Code "Marine Industry; canboat type: LOOKUP";
CM_ SG_ 2650735616 Message_ID "SiriusXM Presets; canboat type: LOOKUP";
CM_ SG_ 2650735616 Source_ID "canboat type: UINT8";
CM_ SG_ 2650735616 Count "canboat type: UINT8";
CM_ SG_ 2650735616 Values "Preset Values. There will be Count / 4 presets stored; canboat type: BINARY";
CM_ SG_ 2650735616 Industry_Code "Marine Industry; canboat type: LOOKUP";
CM_ SG_ 2650735616 Message_ID "SiriusXm Signal; canboat type: LOOKUP";
CM_ SG_ 2650735616 Source_ID "canboat type: UINT8";
CM_ SG_ 2650735616 Signal "canboat type: UINT8";
CM_ SG_ 2650735616 Industry_Code "Marine Industry; canboat type: LOOKUP";
CM_ SG_ 2650735616 Message_ID "SiriusXM Title; canboat type: LOOKUP";
CM_ SG_ 2650735616 Source_ID "canboat type: UINT8";
CM_ SG_ 2650735616 Channel "canboat type: UINT16";
CM_ SG_ 2650735616 Title "canboat type: STRING_LZ";
CM_ SG_ 2650735616 Industry_Code "Marine Industry; canboat type: LOOKUP";
CM_ SG_ 2650735616 Message_ID "Source; canboat type: LOOKUP";
CM_ SG_ 2650735616 Source_ID "canboat type: UINT8";
CM_ SG_ 2650735616 Current_Source_ID "canboat type: UINT8";
CM_ SG_ 2650735616 Source_Type "canboat type: LOOKUP";
CM_ SG_ 2650735616 Flags "canboat type: UINT8";
CM_ SG_ 2650735616 Source "canboat type: STRING_LZ";
CM_ SG_ 2650735616 Industry_Code "Marine Industry; canboat type: LOOKUP";
CM_ SG_ 2650735616 Message_ID "Source Count; canboat type: LOOKUP";
CM_ SG_ 2650735616 Source_Count "canboat type: UINT8";
CM_ SG_ 2650735616 Industry_Code "Marine Industry; canboat type: LOOKUP";
CM_ SG_ 2650735616 Message_ID "Speed Volume Current Speed; canboat type: LOOKUP";
CM_ SG_ 2650735616 Source_ID "canboat type: UINT8";
CM_ SG_ 2650735616 Speed "canboat type: UINT16";
CM_ SG_ 2650735616 Enabled "canboat type: UINT8";
CM_ SG_ 2650735616 Industry_Code "Marine Industry; canboat type: LOOKUP";
CM_ SG_ 2650735616 Message_ID "Sublevels; canboat type: LOOKUP";
CM_ SG_ 2650735616 Zone_1 "canboat type: UINT8";
CM_ SG_ 2650735616 Zone_2 "canboat type: UINT8";
CM_ SG_ 2650735616 Zone_3 "canboat type: UINT8";
CM_ SG_ 2650735616 Zone_4 "canboat type: UINT8";
CM_ SG_ 2650735616 Industry_Code "Marine Industry; canboat type: LOOKUP";
CM_ SG_ 2650735616 Message_ID "Track Title; canboat type: LOOKUP";
CM_ SG_ 2650735616 Source_ID "canboat type: UINT8";
CM_ SG_ 2650735616 Index "canboat type: UINT32";
CM_ SG_ 2650735616 Track "canboat type: STRING_LZ";
CM_ SG_ 2650735616 Industry_Code "Marine Industry; canboat type: LOOKUP";
CM_ SG_ 2650735616 Message_ID "Track Progress; canboat type: LOOKUP";
CM_ SG_ 2650735616 Source_ID "canboat type: UINT8";
CM_ SG_ 2650735616 Progress "canboat type: DURATION_UFIX24_MS";
CM_ SG_ 2650735616 Industry_Code "Marine Industry; canboat type: LOOKUP";
CM_ SG_ 2650735616 Message_ID "Tuner; canboat type: LOOKUP";
CM_ SG_ 2650735616 Source_ID "canboat type: LOOKUP";
CM_ SG_ 2650735616 Scanning "canboat type: UINT8";
CM_ SG_ 2650735616 Frequency "canboat type: RADIO_FREQUENCY_UFIX32";
CM_ SG_ 2650735616 Signal_Strength "canboat type: UINT8";
CM_ SG_ 2650735616 Track "canboat type: STRING_LZ";
CM_ SG_ 2650735616 Industry_Code "Marine Industry; canboat type: LOOKUP";
CM_ SG_ 2650735616 Message_ID "Setting; canboat type: LOOKUP";
CM_ SG_ 2650735616 ID "USB repeat; canboat type: LOOKUP";
CM_ SG_ 2650735616 Status "canboat type: LOOKUP";
CM_ SG_ 2650735616 Industry_Code "Marine Industry; canboat type: LOOKUP";
CM_ SG_ 2650735616 Message_ID "API Version; canboat type: LOOKUP";
CM_ SG_ 2650735616 HW_Version_Major "canboat type: UINT16";
CM_ SG_ 2650735616 HW_Version_Minor "canboat type: UINT16";
CM_ SG_ 2650735616 SW_Version_Major "canboat type: UINT8";
CM_ SG_ 2650735616 SW_Version_Minor "canboat type: UINT8";
CM_ SG_ 2650735616 Build_Number "canboat type: UINT8";
CM_ SG_ 2650735616 Industry_Code "Marine Industry; canboat type: LOOKUP";
CM_ SG_ 2650735616 Message_ID "Volume Limits; canboat type: LOOKUP";
CM_ SG_ 2650735616 Zone_1_Volume_Limit "canboat type: UINT8";
CM_ SG_ 2650735616 Zone_2_Volume_Limit "canboat type: UINT8";
CM_ SG_ 2650735616 Zone_3_Volume_Limit "canboat type: UINT8";
CM_ SG_ 2650735616 Zone_4_Volume_Limit "canboat type: UINT8";
CM_ SG_ 2650735616 Industry_Code "Marine Industry; canboat type: LOOKUP";
CM_ SG_ 2650735616 Message_ID "Volume; canboat type: LOOKUP";
CM_ SG_ 2650735616 Zone_1 "canboat type: UINT8";
CM_ SG_ 2650735616 Zone_2 "canboat type: UINT8";
CM_ SG_ 2650735616 Zone_3 "canboat type: UINT8";
CM_ SG_ 2650735616 Zone_4 "canboat type: UINT8";
CM_ SG_ 2650735616 Industry_Code "Marine Industry; canboat type: LOOKUP";
CM_ SG_ 2650735616 Message_ID "Zone Name; canboat type: LOOKUP";
CM_ SG_ 2650735616 Number "canboat type: UINT8";
CM_ SG_ 2650735616 Name "canboat type: STRING_LZ";
CM_ SG_ 2650735616 Industry_Code "Marine Industry; canboat type: LOOKUP";
CM_ SG_ 2650735616 Alert_Type "canboat type: LOOKUP";
CM_ SG_ 2650735616 Alert_Category "canboat type: LOOKUP";
CM_ SG_ 2650735616 Alert_System "canboat type: UINT8";
CM_ SG_ 2650735616 Alert_Sub_System "canboat type: UINT8";
CM_ SG_ 2650735616 Alert_ID "canboat type: UINT16";
CM_ SG_ 2650735616 Data_Source_Network_ID_NAME "canboat type: ISO_NAME";
CM_ SG_ 2650735616 Data_Source_Instance "canboat type: UINT8";
CM_ SG_ 2650735616 Data_Source_Index_Source "canboat type: UINT8";
CM_ SG_ 2650735616 Alert_Occurrence_Number "canboat type: UINT8";
CM_ SG_ 2650735616 Acknowledge_Source_Network_ID_NAME "canboat type: ISO_NAME";
CM_ SG_ 2650735616 Response_Command "canboat type: LOOKUP";
CM_ SG_ 2650735616 Industry_Code "Marine Industry; canboat type: LOOKUP";
CM_ SG_ 2650735616 Status "canboat type: UINT8";
CM_ SG_ 2583627008 Manufacturer_Code "BEP Marine; canboat type: LOOKUP";
CM_ SG_ 2583627008 Industry_Code "Marine Industry; canboat type: LOOKUP";
CM_ SG_ 2583627008 Data "canboat type: BINARY";
CM_ SG_ 2650735872 Manufacturer_Code "Furuno; canboat type: LOOKUP";
CM_ SG_ 2650735872 Industry_Code "Marine Industry; canboat type: LOOKUP";
CM_ SG_ 2650735872 SID "canboat type: UINT8";
CM_ SG_ 2650735872 A "canboat type: UINT8";
CM_ SG_ 2650735872 B "canboat type: UINT8";
CM_ SG_ 2650735872 C "canboat type: UINT8";
CM_ SG_ 2650735872 D "canboat type: UINT8";
CM_ SG_ 2650735872 E "canboat type: UINT8";
CM_ SG_ 2650735872 F "canboat type: UINT8";
CM_ SG_ 2650735872 G "canboat type: UINT8";
CM_ SG_ 2650735872 H "canboat type: UINT8";
CM_ SG_ 2650735872 I "canboat type: UINT8";
CM_ SG_ 2650735872 Manufacturer_Code "Maretron; canboat type: LOOKUP";
CM_ SG_ 2650735872 Industry_Code "Marine Industry; canboat type: LOOKUP";
CM_ SG_ 2650735872 Alert_Type "canboat type: LOOKUP";
CM_ SG_ 2650735872 Alert_Category "canboat type: LOOKUP";
CM_ SG_ 2650735872 Alert_System "canboat type: UINT8";
CM_ SG_ 2650735872 Alert_Sub_System "canboat type: UINT8";
CM_ SG_ 2650735872 Alert_ID "canboat type: UINT16";
CM_ SG_ 2650735872 Data_Source_Network_ID_NAME "canboat type: ISO_NAME";
CM_ SG_ 2650735872 Data_Source_Instance "canboat type: UINT8";
CM_ SG_ 2650735872 Data_Source_Index_Source "canboat type: UINT8";
CM_ SG_ 2650735872 Alert_Occurrence_Number "canboat type: UINT8";
CM_ SG_ 2650735872 Language_ID "canboat type: LOOKUP";
CM_ SG_ 2650735872 Alert_Text_Description "canboat type: STRING_LAU";
CM_ SG_ 2650735872 Alert_Location_Text_Description "canboat type: STRING_LAU";
CM_ SG_ 2650735872 Manufacturer_Code "Navico; canboat type: LOOKUP";
CM_ SG_ 2650735872 Industry_Code "Marine Industry; canboat type: LOOKUP";
CM_ SG_ 2650735872 A "canboat type: UINT8";
CM_ SG_ 2650735872 Message "canboat type: STRING_FIX";
CM_ SG_ 2583627264 Manufacturer_Code "BEP Marine; canboat type: LOOKUP";
CM_ SG_ 2583627264 Industry_Code "Marine Industry; canboat type: LOOKUP";
CM_ SG_ 2583627264 Data "canboat type: BINARY";
CM_ SG_ 2650736128 Manufacturer_Code "Maretron; canboat type: LOOKUP";
CM_ SG_ 2650736128 Industry_Code "Marine Industry; canboat type: LOOKUP";
CM_ SG_ 2650736128 Alert_Type "canboat type: LOOKUP";
CM_ SG_ 2650736128 Alert_Category "canboat type: LOOKUP";
CM_ SG_ 2650736128 Alert_System "canboat type: UINT8";
CM_ SG_ 2650736128 Alert_Sub_System "canboat type: UINT8";
CM_ SG_ 2650736128 Alert_ID "canboat type: UINT16";
CM_ SG_ 2650736128 Data_Source_Network_ID_NAME "canboat type: ISO_NAME";
CM_ SG_ 2650736128 Data_Source_Instance "canboat type: UINT8";
CM_ SG_ 2650736128 Data_Source_Index_Source "canboat type: UINT8";
CM_ SG_ 2650736128 Alert_Occurrence_Number "canboat type: UINT8";
CM_ SG_ 2650736128 Maretron_Extension "Maretron-specific payload following the standard Alert identity header.; canboat type: BINARY";
CM_ SG_ 2583627264 Manufacturer_Code "Mercury Marine; canboat type: LOOKUP";
CM_ SG_ 2583627264 Industry_Code "Marine Industry; canboat type: LOOKUP";
CM_ SG_ 2583627264 Engine_Instance "canboat type: UINT8";
CM_ SG_ 2583627264 Malfunction_Indicator "Check-engine indicator lamp (0 = off, 1 = on); canboat type: UINT8";
CM_ SG_ 2583627264 Intake_Air_Temperature "Raw value, Mercury-specific scaling; canboat type: UINT8";
CM_ SG_ 2583627264 Exhaust_Gas_Temperature "Raw value, Mercury-specific scaling; canboat type: UINT16";
CM_ SG_ 2583627264 GPL "Raw value; fraction = value / 128; canboat type: UINT8";
CM_ SG_ 2583627264 Engine_State "Raw engine run-state code; canboat type: UINT8";
VAL_ 2650735616 Industry_Code 0 "Global" 1 "Highway" 2 "Agriculture" 3 "Construction" 4 "Marine Industry" 5 "Industrial" ;
VAL_ 2650735616 Industry_Code 0 "Global" 1 "Highway" 2 "Agriculture" 3 "Construction" 4 "Marine Industry" 5 "Industrial" ;
VAL_ 2650735616 Message_ID 0 "Unknown" 32769 "API Version" 32770 "Source" 32771 "Source Count" 32772 "Track Info" 32773 "Track Title" 32774 "Track Artist" 32775 "Track Album" 32776 "Cover Art" 32777 "Track Progress" 32778 "Tuner Align" 32779 "Tuner" 32780 "Marine Tuner" 32781 "Marine Squelch" 32782 "Marine Scan Mode" 32783 "Menu Action" 32784 "Menu Count" 32785 "Menu Item" 32786 "Menu Lock ID" 32787 "Aux Gain" 32788 "Setting" 32789 "Settings" 32790 "Update Firmware Result" 32791 "Mute" 32792 "Balance" 32793 "Low Pass Filter" 32794 "Sublevels" 32795 "Tone" 32796 "Volume Limits" 32797 "Volume" 32798 "Capabilities" 32799 "Line Level Control" 32800 "Power" 32801 "Unit Name" 32802 "Sirius" 32803 "SiriusXM Preset Event" 32804 "SiriusXM Channel" 32805 "SiriusXM Title" 32806 "SiriusXM Artist" 32807 "SiriusXM Genre" 32808 "SiriusXM Category" 32809 "SiriusXm Signal" 32810 "SiriusXM Parental Request" 32811 "SiriusXM Diagnostics" 32812 "SiriusXM Presets" 32813 "Zone Name" 32819 "IP Setting" 32824 "Multiroom" 32825 "Multiroom Status" 32829 "System Capabilities" 32830 "Part Number" 32832 "Processing Bypass" 32846 "Server Info" 32850 "RDS Data" 32859 "Ignition Switch State" 32862 "Mono" 32863 "Speed Volume Current Speed" 32865 "Zone Capabilities Extended" ;
VAL_ 2650735616 Industry_Code 0 "Global" 1 "Highway" 2 "Agriculture" 3 "Construction" 4 "Marine Industry" 5 "Industrial" ;
VAL_ 2650735616 Message_ID 0 "Unknown" 32769 "API Version" 32770 "Source" 32771 "Source Count" 32772 "Track Info" 32773 "Track Title" 32774 "Track Artist" 32775 "Track Album" 32776 "Cover Art" 32777 "Track Progress" 32778 "Tuner Align" 32779 "Tuner" 32780 "Marine Tuner" 32781 "Marine Squelch" 32782 "Marine Scan Mode" 32783 "Menu Action" 32784 "Menu Count" 32785 "Menu Item" 32786 "Menu Lock ID" 32787 "Aux Gain" 32788 "Setting" 32789 "Settings" 32790 "Update Firmware Result" 32791 "Mute" 32792 "Balance" 32793 "Low Pass Filter" 32794 "Sublevels" 32795 "Tone" 32796 "Volume Limits" 32797 "Volume" 32798 "Capabilities" 32799 "Line Level Control" 32800 "Power" 32801 "Unit Name" 32802 "Sirius" 32803 "SiriusXM Preset Event" 32804 "SiriusXM Channel" 32805 "SiriusXM Title" 32806 "SiriusXM Artist" 32807 "SiriusXM Genre" 32808 "SiriusXM Category" 32809 "SiriusXm Signal" 32810 "SiriusXM Parental Request" 32811 "SiriusXM Diagnostics" 32812 "SiriusXM Presets" 32813 "Zone Name" 32819 "IP Setting" 32824 "Multiroom" 32825 "Multiroom Status" 32829 "System Capabilities" 32830 "Part Number" 32832 "Processing Bypass" 32846 "Server Info" 32850 "RDS Data" 32859 "Ignition Switch State" 32862 "Mono" 32863 "Speed Volume Current Speed" 32865 "Zone Capabilities Extended" ;
VAL_ 2650735616 Industry_Code 0 "Global" 1 "Highway" 2 "Agriculture" 3 "Construction" 4 "Marine Industry" 5 "Industrial" ;
VAL_ 2650735616 Message_ID 0 "Unknown" 32769 "API Version" 32770 "Source" 32771 "Source Count" 32772 "Track Info" 32773 "Track Title" 32774 "Track Artist" 32775 "Track Album" 32776 "Cover Art" 32777 "Track Progress" 32778 "Tuner Align" 32779 "Tuner" 32780 "Marine Tuner" 32781 "Marine Squelch" 32782 "Marine Scan Mode" 32783 "Menu Action" 32784 "Menu Count" 32785 "Menu Item" 32786 "Menu Lock ID" 32787 "Aux Gain" 32788 "Setting" 32789 "Settings" 32790 "Update Firmware Result" 32791 "Mute" 32792 "Balance" 32793 "Low Pass Filter" 32794 "Sublevels" 32795 "Tone" 32796 "Volume Limits" 32797 "Volume" 32798 "Capabilities" 32799 "Line Level Control" 32800 "Power" 32801 "Unit Name" 32802 "Sirius" 32803 "SiriusXM Preset Event" 32804 "SiriusXM Channel" 32805 "SiriusXM Title" 32806 "SiriusXM Artist" 32807 "SiriusXM Genre" 32808 "SiriusXM Category" 32809 "SiriusXm Signal" 32810 "SiriusXM Parental Request" 32811 "SiriusXM Diagnostics" 32812 "SiriusXM Presets" 32813 "Zone Name" 32819 "IP Setting" 32824 "Multiroom" 32825 "Multiroom Status" 32829 "System Capabilities" 32830 "Part Number" 32832 "Processing Bypass" 32846 "Server Info" 32850 "RDS Data" 32859 "Ignition Switch State" 32862 "Mono" 32863 "Speed Volume Current Speed" 32865 "Zone Capabilities Extended" ;
VAL_ 2650735616 Industry_Code 0 "Global" 1 "Highway" 2 "Agriculture" 3 "Construction" 4 "Marine Industry" 5 "Industrial" ;
VAL_ 2650735616 Message_ID 0 "Unknown" 32769 "API Version" 32770 "Source" 32771 "Source Count" 32772 "Track Info" 32773 "Track Title" 32774 "Track Artist" 32775 "Track Album" 32776 "Cover Art" 32777 "Track Progress" 32778 "Tuner Align" 32779 "Tuner" 32780 "Marine Tuner" 32781 "Marine Squelch" 32782 "Marine Scan Mode" 32783 "Menu Action" 32784 "Menu Count" 32785 "Menu Item" 32786 "Menu Lock ID" 32787 "Aux Gain" 32788 "Setting" 32789 "Settings" 32790 "Update Firmware Result" 32791 "Mute" 32792 "Balance" 32793 "Low Pass Filter" 32794 "Sublevels" 32795 "Tone" 32796 "Volume Limits" 32797 "Volume" 32798 "Capabilities" 32799 "Line Level Control" 32800 "Power" 32801 "Unit Name" 32802 "Sirius" 32803 "SiriusXM Preset Event" 32804 "SiriusXM Channel" 32805 "SiriusXM Title" 32806 "SiriusXM Artist" 32807 "SiriusXM Genre" 32808 "SiriusXM Category" 32809 "SiriusXm Signal" 32810 "SiriusXM Parental Request" 32811 "SiriusXM Diagnostics" 32812 "SiriusXM Presets" 32813 "Zone Name" 32819 "IP Setting" 32824 "Multiroom" 32825 "Multiroom Status" 32829 "System Capabilities" 32830 "Part Number" 32832 "Processing Bypass" 32846 "Server Info" 32850 "RDS Data" 32859 "Ignition Switch State" 32862 "Mono" 32863 "Speed Volume Current Speed" 32865 "Zone Capabilities Extended" ;
VAL_ 2650735616 Industry_Code 0 "Global" 1 "Highway" 2 "Agriculture" 3 "Construction" 4 "Marine Industry" 5 "Industrial" ;
VAL_ 2650735616 Message_ID 0 "Unknown" 32769 "API Version" 32770 "Source" 32771 "Source Count" 32772 "Track Info" 32773 "Track Title" 32774 "Track Artist" 32775 "Track Album" 32776 "Cover Art" 32777 "Track Progress" 32778 "Tuner Align" 32779 "Tuner" 32780 "Marine Tuner" 32781 "Marine Squelch" 32782 "Marine Scan Mode" 32783 "Menu Action" 32784 "Menu Count" 32785 "Menu Item" 32786 "Menu Lock ID" 32787 "Aux Gain" 32788 "Setting" 32789 "Settings" 32790 "Update Firmware Result" 32791 "Mute" 32792 "Balance" 32793 "Low Pass Filter" 32794 "Sublevels" 32795 "Tone" 32796 "Volume Limits" 32797 "Volume" 32798 "Capabilities" 32799 "Line Level Control" 32800 "Power" 32801 "Unit Name" 32802 "Sirius" 32803 "SiriusXM Preset Event" 32804 "SiriusXM Channel" 32805 "SiriusXM Title" 32806 "SiriusXM Artist" 32807 "SiriusXM Genre" 32808 "SiriusXM Category" 32809 "SiriusXm Signal" 32810 "SiriusXM Parental Request" 32811 "SiriusXM Diagnostics" 32812 "SiriusXM Presets" 32813 "Zone Name" 32819 "IP Setting" 32824 "Multiroom" 32825 "Multiroom Status" 32829 "System Capabilities" 32830 "Part Number" 32832 "Processing Bypass" 32846 "Server Info" 32850 "RDS Data" 32859 "Ignition Switch State" 32862 "Mono" 32863 "Speed Volume Current Speed" 32865 "Zone Capabilities Extended" ;
VAL_ 2650735616 Industry_Code 0 "Global" 1 "Highway" 2 "Agriculture" 3 "Construction" 4 "Marine Industry" 5 "Industrial" ;
VAL_ 2650735616 Message_ID 0 "Unknown" 32769 "API Version" 32770 "Source" 32771 "Source Count" 32772 "Track Info" 32773 "Track Title" 32774 "Track Artist" 32775 "Track Album" 32776 "Cover Art" 32777 "Track Progress" 32778 "Tuner Align" 32779 "Tuner" 32780 "Marine Tuner" 32781 "Marine Squelch" 32782 "Marine Scan Mode" 32783 "Menu Action" 32784 "Menu Count" 32785 "Menu Item" 32786 "Menu Lock ID" 32787 "Aux Gain" 32788 "Setting" 32789 "Settings" 32790 "Update Firmware Result" 32791 "Mute" 32792 "Balance" 32793 "Low Pass Filter" 32794 "Sublevels" 32795 "Tone" 32796 "Volume Limits" 32797 "Volume" 32798 "Capabilities" 32799 "Line Level Control" 32800 "Power" 32801 "Unit Name" 32802 "Sirius" 32803 "SiriusXM Preset Event" 32804 "SiriusXM Channel" 32805 "SiriusXM Title" 32806 "SiriusXM Artist" 32807 "SiriusXM Genre" 32808 "SiriusXM Category" 32809 "SiriusXm Signal" 32810 "SiriusXM Parental Request" 32811 "SiriusXM Diagnostics" 32812 "SiriusXM Presets" 32813 "Zone Name" 32819 "IP Setting" 32824 "Multiroom" 32825 "Multiroom Status" 32829 "System Capabilities" 32830 "Part Number" 32832 "Processing Bypass" 32846 "Server Info" 32850 "RDS Data" 32859 "Ignition Switch State" 32862 "Mono" 32863 "Speed Volume Current Speed" 32865 "Zone Capabilities Extended" ;
VAL_ 2650735616 Industry_Code 0 "Global" 1 "Highway" 2 "Agriculture" 3 "Construction" 4 "Marine Industry" 5 "Industrial" ;
VAL_ 2650735616 Message_ID 0 "Unknown" 32769 "API Version" 32770 "Source" 32771 "Source Count" 32772 "Track Info" 32773 "Track Title" 32774 "Track Artist" 32775 "Track Album" 32776 "Cover Art" 32777 "Track Progress" 32778 "Tuner Align" 32779 "Tuner" 32780 "Marine Tuner" 32781 "Marine Squelch" 32782 "Marine Scan Mode" 32783 "Menu Action" 32784 "Menu Count" 32785 "Menu Item" 32786 "Menu Lock ID" 32787 "Aux Gain" 32788 "Setting" 32789 "Settings" 32790 "Update Firmware Result" 32791 "Mute" 32792 "Balance" 32793 "Low Pass Filter" 32794 "Sublevels" 32795 "Tone" 32796 "Volume Limits" 32797 "Volume" 32798 "Capabilities" 32799 "Line Level Control" 32800 "Power" 32801 "Unit Name" 32802 "Sirius" 32803 "SiriusXM Preset Event" 32804 "SiriusXM Channel" 32805 "SiriusXM Title" 32806 "SiriusXM Artist" 32807 "SiriusXM Genre" 32808 "SiriusXM Category" 32809 "SiriusXm Signal" 32810 "SiriusXM Parental Request" 32811 "SiriusXM Diagnostics" 32812 "SiriusXM Presets" 32813 "Zone Name" 32819 "IP Setting" 32824 "Multiroom" 32825 "Multiroom Status" 32829 "System Capabilities" 32830 "Part Number" 32832 "Processing Bypass" 32846 "Server Info" 32850 "RDS Data" 32859 "Ignition Switch State" 32862 "Mono" 32863 "Speed Volume Current Speed" 32865 "Zone Capabilities Extended" ;
VAL_ 2650735616 Industry_Code 0 "Global" 1 "Highway" 2 "Agriculture" 3 "Construction" 4 "Marine Industry" 5 "Industrial" ;
VAL_ 2650735616 Message_ID 0 "Unknown" 32769 "API Version" 32770 "Source" 32771 "Source Count" 32772 "Track Info" 32773 "Track Title" 32774 "Track Artist" 32775 "Track Album" 32776 "Cover Art" 32777 "Track Progress" 32778 "Tuner Align" 32779 "Tuner" 32780 "Marine Tuner" 32781 "Marine Squelch" 32782 "Marine Scan Mode" 32783 "Menu Action" 32784 "Menu Count" 32785 "Menu Item" 32786 "Menu Lock ID" 32787 "Aux Gain" 32788 "Setting" 32789 "Settings" 32790 "Update Firmware Result" 32791 "Mute" 32792 "Balance" 32793 "Low Pass Filter" 32794 "Sublevels" 32795 "Tone" 32796 "Volume Limits" 32797 "Volume" 32798 "Capabilities" 32799 "Line Level Control" 32800 "Power" 32801 "Unit Name" 32802 "Sirius" 32803 "SiriusXM Preset Event" 32804 "SiriusXM Channel" 32805 "SiriusXM Title" 32806 "SiriusXM Artist" 32807 "SiriusXM Genre" 32808 "SiriusXM Category" 32809 "SiriusXm Signal" 32810 "SiriusXM Parental Request" 32811 "SiriusXM Diagnostics" 32812 "SiriusXM Presets" 32813 "Zone Name" 32819 "IP Setting" 32824 "Multiroom" 32825 "Multiroom Status" 32829 "System Capabilities" 32830 "Part Number" 32832 "Processing Bypass" 32846 "Server Info" 32850 "RDS Data" 32859 "Ignition Switch State" 32862 "Mono" 32863 "Speed Volume Current Speed" 32865 "Zone Capabilities Extended" ;
VAL_ 2650735616 Industry_Code 0 "Global" 1 "Highway" 2 "Agriculture" 3 "Construction" 4 "Marine Industry" 5 "Industrial" ;
VAL_ 2650735616 Message_ID 0 "Unknown" 32769 "API Version" 32770 "Source" 32771 "Source Count" 32772 "Track Info" 32773 "Track Title" 32774 "Track Artist" 32775 "Track Album" 32776 "Cover Art" 32777 "Track Progress" 32778 "Tuner Align" 32779 "Tuner" 32780 "Marine Tuner" 32781 "Marine Squelch" 32782 "Marine Scan Mode" 32783 "Menu Action" 32784 "Menu Count" 32785 "Menu Item" 32786 "Menu Lock ID" 32787 "Aux Gain" 32788 "Setting" 32789 "Settings" 32790 "Update Firmware Result" 32791 "Mute" 32792 "Balance" 32793 "Low Pass Filter" 32794 "Sublevels" 32795 "Tone" 32796 "Volume Limits" 32797 "Volume" 32798 "Capabilities" 32799 "Line Level Control" 32800 "Power" 32801 "Unit Name" 32802 "Sirius" 32803 "SiriusXM Preset Event" 32804 "SiriusXM Channel" 32805 "SiriusXM Title" 32806 "SiriusXM Artist" 32807 "SiriusXM Genre" 32808 "SiriusXM Category" 32809 "SiriusXm Signal" 32810 "SiriusXM Parental Request" 32811 "SiriusXM Diagnostics" 32812 "SiriusXM Presets" 32813 "Zone Name" 32819 "IP Setting" 32824 "Multiroom" 32825 "Multiroom Status" 32829 "System Capabilities" 32830 "Part Number" 32832 "Processing Bypass" 32846 "Server Info" 32850 "RDS Data" 32859 "Ignition Switch State" 32862 "Mono" 32863 "Speed Volume Current Speed" 32865 "Zone Capabilities Extended" ;
VAL_ 2650735616 Industry_Code 0 "Global" 1 "Highway" 2 "Agriculture" 3 "Construction" 4 "Marine Industry" 5 "Industrial" ;
VAL_ 2650735616 Message_ID 0 "Unknown" 32769 "API Version" 32770 "Source" 32771 "Source Count" 32772 "Track Info" 32773 "Track Title" 32774 "Track Artist" 32775 "Track Album" 32776 "Cover Art" 32777 "Track Progress" 32778 "Tuner Align" 32779 "Tuner" 32780 "Marine Tuner" 32781 "Marine Squelch" 32782 "Marine Scan Mode" 32783 "Menu Action" 32784 "Menu Count" 32785 "Menu Item" 32786 "Menu Lock ID" 32787 "Aux Gain" 32788 "Setting" 32789 "Settings" 32790 "Update Firmware Result" 32791 "Mute" 32792 "Balance" 32793 "Low Pass Filter" 32794 "Sublevels" 32795 "Tone" 32796 "Volume Limits" 32797 "Volume" 32798 "Capabilities" 32799 "Line Level Control" 32800 "Power" 32801 "Unit Name" 32802 "Sirius" 32803 "SiriusXM Preset Event" 32804 "SiriusXM Channel" 32805 "SiriusXM Title" 32806 "SiriusXM Artist" 32807 "SiriusXM Genre" 32808 "SiriusXM Category" 32809 "SiriusXm Signal" 32810 "SiriusXM Parental Request" 32811 "SiriusXM Diagnostics" 32812 "SiriusXM Presets" 32813 "Zone Name" 32819 "IP Setting" 32824 "Multiroom" 32825 "Multiroom Status" 32829 "System Capabilities" 32830 "Part Number" 32832 "Processing Bypass" 32846 "Server Info" 32850 "RDS Data" 32859 "Ignition Switch State" 32862 "Mono" 32863 "Speed Volume Current Speed" 32865 "Zone Capabilities Extended" ;
VAL_ 2650735616 Industry_Code 0 "Global" 1 "Highway" 2 "Agriculture" 3 "Construction" 4 "Marine Industry" 5 "Industrial" ;
VAL_ 2650735616 Message_ID 0 "Unknown" 32769 "API Version" 32770 "Source" 32771 "Source Count" 32772 "Track Info" 32773 "Track Title" 32774 "Track Artist" 32775 "Track Album" 32776 "Cover Art" 32777 "Track Progress" 32778 "Tuner Align" 32779 "Tuner" 32780 "Marine Tuner" 32781 "Marine Squelch" 32782 "Marine Scan Mode" 32783 "Menu Action" 32784 "Menu Count" 32785 "Menu Item" 32786 "Menu Lock ID" 32787 "Aux Gain" 32788 "Setting" 32789 "Settings" 32790 "Update Firmware Result" 32791 "Mute" 32792 "Balance" 32793 "Low Pass Filter" 32794 "Sublevels" 32795 "Tone" 32796 "Volume Limits" 32797 "Volume" 32798 "Capabilities" 32799 "Line Level Control" 32800 "Power" 32801 "Unit Name" 32802 "Sirius" 32803 "SiriusXM Preset Event" 32804 "SiriusXM Channel" 32805 "SiriusXM Title" 32806 "SiriusXM Artist" 32807 "SiriusXM Genre" 32808 "SiriusXM Category" 32809 "SiriusXm Signal" 32810 "SiriusXM Parental Request" 32811 "SiriusXM Diagnostics" 32812 "SiriusXM Presets" 32813 "Zone Name" 32819 "IP Setting" 32824 "Multiroom" 32825 "Multiroom Status" 32829 "System Capabilities" 32830 "Part Number" 32832 "Processing Bypass" 32846 "Server Info" 32850 "RDS Data" 32859 "Ignition Switch State" 32862 "Mono" 32863 "Speed Volume Current Speed" 32865 "Zone Capabilities Extended" ;
VAL_ 2650735616 Scan 0 "No" 1 "Yes" ;
VAL_ 2650735616 Industry_Code 0 "Global" 1 "Highway" 2 "Agriculture" 3 "Construction" 4 "Marine Industry" 5 "Industrial" ;
VAL_ 2650735616 Message_ID 0 "Unknown" 32769 "API Version" 32770 "Source" 32771 "Source Count" 32772 "Track Info" 32773 "Track Title" 32774 "Track Artist" 32775 "Track Album" 32776 "Cover Art" 32777 "Track Progress" 32778 "Tuner Align" 32779 "Tuner" 32780 "Marine Tuner" 32781 "Marine Squelch" 32782 "Marine Scan Mode" 32783 "Menu Action" 32784 "Menu Count" 32785 "Menu Item" 32786 "Menu Lock ID" 32787 "Aux Gain" 32788 "Setting" 32789 "Settings" 32790 "Update Firmware Result" 32791 "Mute" 32792 "Balance" 32793 "Low Pass Filter" 32794 "Sublevels" 32795 "Tone" 32796 "Volume Limits" 32797 "Volume" 32798 "Capabilities" 32799 "Line Level Control" 32800 "Power" 32801 "Unit Name" 32802 "Sirius" 32803 "SiriusXM Preset Event" 32804 "SiriusXM Channel" 32805 "SiriusXM Title" 32806 "SiriusXM Artist" 32807 "SiriusXM Genre" 32808 "SiriusXM Category" 32809 "SiriusXm Signal" 32810 "SiriusXM Parental Request" 32811 "SiriusXM Diagnostics" 32812 "SiriusXM Presets" 32813 "Zone Name" 32819 "IP Setting" 32824 "Multiroom" 32825 "Multiroom Status" 32829 "System Capabilities" 32830 "Part Number" 32832 "Processing Bypass" 32846 "Server Info" 32850 "RDS Data" 32859 "Ignition Switch State" 32862 "Mono" 32863 "Speed Volume Current Speed" 32865 "Zone Capabilities Extended" ;
VAL_ 2650735616 Industry_Code 0 "Global" 1 "Highway" 2 "Agriculture" 3 "Construction" 4 "Marine Industry" 5 "Industrial" ;
VAL_ 2650735616 Message_ID 0 "Unknown" 32769 "API Version" 32770 "Source" 32771 "Source Count" 32772 "Track Info" 32773 "Track Title" 32774 "Track Artist" 32775 "Track Album" 32776 "Cover Art" 32777 "Track Progress" 32778 "Tuner Align" 32779 "Tuner" 32780 "Marine Tuner" 32781 "Marine Squelch" 32782 "Marine Scan Mode" 32783 "Menu Action" 32784 "Menu Count" 32785 "Menu Item" 32786 "Menu Lock ID" 32787 "Aux Gain" 32788 "Setting" 32789 "Settings" 32790 "Update Firmware Result" 32791 "Mute" 32792 "Balance" 32793 "Low Pass Filter" 32794 "Sublevels" 32795 "Tone" 32796 "Volume Limits" 32797 "Volume" 32798 "Capabilities" 32799 "Line Level Control" 32800 "Power" 32801 "Unit Name" 32802 "Sirius" 32803 "SiriusXM Preset Event" 32804 "SiriusXM Channel" 32805 "SiriusXM Title" 32806 "SiriusXM Artist" 32807 "SiriusXM Genre" 32808 "SiriusXM Category" 32809 "SiriusXm Signal" 32810 "SiriusXM Parental Request" 32811 "SiriusXM Diagnostics" 32812 "SiriusXM Presets" 32813 "Zone Name" 32819 "IP Setting" 32824 "Multiroom" 32825 "Multiroom Status" 32829 "System Capabilities" 32830 "Part Number" 32832 "Processing Bypass" 32846 "Server Info" 32850 "RDS Data" 32859 "Ignition Switch State" 32862 "Mono" 32863 "Speed Volume Current Speed" 32865 "Zone Capabilities Extended" ;
VAL_ 2650735616 Industry_Code 0 "Global" 1 "Highway" 2 "Agriculture" 3 "Construction" 4 "Marine Industry" 5 "Industrial" ;
VAL_ 2650735616 Message_ID 0 "Unknown" 32769 "API Version" 32770 "Source" 32771 "Source Count" 32772 "Track Info" 32773 "Track Title" 32774 "Track Artist" 32775 "Track Album" 32776 "Cover Art" 32777 "Track Progress" 32778 "Tuner Align" 32779 "Tuner" 32780 "Marine Tuner" 32781 "Marine Squelch" 32782 "Marine Scan Mode" 32783 "Menu Action" 32784 "Menu Count" 32785 "Menu Item" 32786 "Menu Lock ID" 32787 "Aux Gain" 32788 "Setting" 32789 "Settings" 32790 "Update Firmware Result" 32791 "Mute" 32792 "Balance" 32793 "Low Pass Filter" 32794 "Sublevels" 32795 "Tone" 32796 "Volume Limits" 32797 "Volume" 32798 "Capabilities" 32799 "Line Level Control" 32800 "Power" 32801 "Unit Name" 32802 "Sirius" 32803 "SiriusXM Preset Event" 32804 "SiriusXM Channel" 32805 "SiriusXM Title" 32806 "SiriusXM Artist" 32807 "SiriusXM Genre" 32808 "SiriusXM Category" 32809 "SiriusXm Signal" 32810 "SiriusXM Parental Request" 32811 "SiriusXM Diagnostics" 32812 "SiriusXM Presets" 32813 "Zone Name" 32819 "IP Setting" 32824 "Multiroom" 32825 "Multiroom Status" 32829 "System Capabilities" 32830 "Part Number" 32832 "Processing Bypass" 32846 "Server Info" 32850 "RDS Data" 32859 "Ignition Switch State" 32862 "Mono" 32863 "Speed Volume Current Speed" 32865 "Zone Capabilities Extended" ;
VAL_ 2650735616 Flags 0 "Invalid" 1 "Playing" 2 "Paused" 3 "Stopped" 4 "Skip Forward" 5 "Skip Rewind" ;
VAL_ 2650735616 Industry_Code 0 "Global" 1 "Highway" 2 "Agriculture" 3 "Construction" 4 "Marine Industry" 5 "Industrial" ;
VAL_ 2650735616 Message_ID 0 "Unknown" 32769 "API Version" 32770 "Source" 32771 "Source Count" 32772 "Track Info" 32773 "Track Title" 32774 "Track Artist" 32775 "Track Album" 32776 "Cover Art" 32777 "Track Progress" 32778 "Tuner Align" 32779 "Tuner" 32780 "Marine Tuner" 32781 "Marine Squelch" 32782 "Marine Scan Mode" 32783 "Menu Action" 32784 "Menu Count" 32785 "Menu Item" 32786 "Menu Lock ID" 32787 "Aux Gain" 32788 "Setting" 32789 "Settings" 32790 "Update Firmware Result" 32791 "Mute" 32792 "Balance" 32793 "Low Pass Filter" 32794 "Sublevels" 32795 "Tone" 32796 "Volume Limits" 32797 "Volume" 32798 "Capabilities" 32799 "Line Level Control" 32800 "Power" 32801 "Unit Name" 32802 "Sirius" 32803 "SiriusXM Preset Event" 32804 "SiriusXM Channel" 32805 "SiriusXM Title" 32806 "SiriusXM Artist" 32807 "SiriusXM Genre" 32808 "SiriusXM Category" 32809 "SiriusXm Signal" 32810 "SiriusXM Parental Request" 32811 "SiriusXM Diagnostics" 32812 "SiriusXM Presets" 32813 "Zone Name" 32819 "IP Setting" 32824 "Multiroom" 32825 "Multiroom Status" 32829 "System Capabilities" 32830 "Part Number" 32832 "Processing Bypass" 32846 "Server Info" 32850 "RDS Data" 32859 "Ignition Switch State" 32862 "Mono" 32863 "Speed Volume Current Speed" 32865 "Zone Capabilities Extended" ;
VAL_ 2650735616 Action 1 "Open" 2 "Select" 4 "Close" ;
VAL_ 2650735616 Industry_Code 0 "Global" 1 "Highway" 2 "Agriculture" 3 "Construction" 4 "Marine Industry" 5 "Industrial" ;
VAL_ 2650735616 Message_ID 0 "Unknown" 32769 "API Version" 32770 "Source" 32771 "Source Count" 32772 "Track Info" 32773 "Track Title" 32774 "Track Artist" 32775 "Track Album" 32776 "Cover Art" 32777 "Track Progress" 32778 "Tuner Align" 32779 "Tuner" 32780 "Marine Tuner" 32781 "Marine Squelch" 32782 "Marine Scan Mode" 32783 "Menu Action" 32784 "Menu Count" 32785 "Menu Item" 32786 "Menu Lock ID" 32787 "Aux Gain" 32788 "Setting" 32789 "Settings" 32790 "Update Firmware Result" 32791 "Mute" 32792 "Balance" 32793 "Low Pass Filter" 32794 "Sublevels" 32795 "Tone" 32796 "Volume Limits" 32797 "Volume" 32798 "Capabilities" 32799 "Line Level Control" 32800 "Power" 32801 "Unit Name" 32802 "Sirius" 32803 "SiriusXM Preset Event" 32804 "SiriusXM Channel" 32805 "SiriusXM Title" 32806 "SiriusXM Artist" 32807 "SiriusXM Genre" 32808 "SiriusXM Category" 32809 "SiriusXm Signal" 32810 "SiriusXM Parental Request" 32811 "SiriusXM Diagnostics" 32812 "SiriusXM Presets" 32813 "Zone Name" 32819 "IP Setting" 32824 "Multiroom" 32825 "Multiroom Status" 32829 "System Capabilities" 32830 "Part Number" 32832 "Processing Bypass" 32846 "Server Info" 32850 "RDS Data" 32859 "Ignition Switch State" 32862 "Mono" 32863 "Speed Volume Current Speed" 32865 "Zone Capabilities Extended" ;
VAL_ 2650735616 Industry_Code 0 "Global" 1 "Highway" 2 "Agriculture" 3 "Construction" 4 "Marine Industry" 5 "Industrial" ;
VAL_ 2650735616 Message_ID 0 "Unknown" 32769 "API Version" 32770 "Source" 32771 "Source Count" 32772 "Track Info" 32773 "Track Title" 32774 "Track Artist" 32775 "Track Album" 32776 "Cover Art" 32777 "Track Progress" 32778 "Tuner Align" 32779 "Tuner" 32780 "Marine Tuner" 32781 "Marine Squelch" 32782 "Marine Scan Mode" 32783 "Menu Action" 32784 "Menu Count" 32785 "Menu Item" 32786 "Menu Lock ID" 32787 "Aux Gain" 32788 "Setting" 32789 "Settings" 32790 "Update Firmware Result" 32791 "Mute" 32792 "Balance" 32793 "Low Pass Filter" 32794 "Sublevels" 32795 "Tone" 32796 "Volume Limits" 32797 "Volume" 32798 "Capabilities" 32799 "Line Level Control" 32800 "Power" 32801 "Unit Name" 32802 "Sirius" 32803 "SiriusXM Preset Event" 32804 "SiriusXM Channel" 32805 "SiriusXM Title" 32806 "SiriusXM Artist" 32807 "SiriusXM Genre" 32808 "SiriusXM Category" 32809 "SiriusXm Signal" 32810 "SiriusXM Parental Request" 32811 "SiriusXM Diagnostics" 32812 "SiriusXM Presets" 32813 "Zone Name" 32819 "IP Setting" 32824 "Multiroom" 32825 "Multiroom Status" 32829 "System Capabilities" 32830 "Part Number" 32832 "Processing Bypass" 32846 "Server Info" 32850 "RDS Data" 32859 "Ignition Switch State" 32862 "Mono" 32863 "Speed Volume Current Speed" 32865 "Zone Capabilities Extended" ;
VAL_ 2650735616 Industry_Code 0 "Global" 1 "Highway" 2 "Agriculture" 3 "Construction" 4 "Marine Industry" 5 "Industrial" ;
VAL_ 2650735616 Message_ID 0 "Unknown" 32769 "API Version" 32770 "Source" 32771 "Source Count" 32772 "Track Info" 32773 "Track Title" 32774 "Track Artist" 32775 "Track Album" 32776 "Cover Art" 32777 "Track Progress" 32778 "Tuner Align" 32779 "Tuner" 32780 "Marine Tuner" 32781 "Marine Squelch" 32782 "Marine Scan Mode" 32783 "Menu Action" 32784 "Menu Count" 32785 "Menu Item" 32786 "Menu Lock ID" 32787 "Aux Gain" 32788 "Setting" 32789 "Settings" 32790 "Update Firmware Result" 32791 "Mute" 32792 "Balance" 32793 "Low Pass Filter" 32794 "Sublevels" 32795 "Tone" 32796 "Volume Limits" 32797 "Volume" 32798 "Capabilities" 32799 "Line Level Control" 32800 "Power" 32801 "Unit Name" 32802 "Sirius" 32803 "SiriusXM Preset Event" 32804 "SiriusXM Channel" 32805 "SiriusXM Title" 32806 "SiriusXM Artist" 32807 "SiriusXM Genre" 32808 "SiriusXM Category" 32809 "SiriusXm Signal" 32810 "SiriusXM Parental Request" 32811 "SiriusXM Diagnostics" 32812 "SiriusXM Presets" 32813 "Zone Name" 32819 "IP Setting" 32824 "Multiroom" 32825 "Multiroom Status" 32829 "System Capabilities" 32830 "Part Number" 32832 "Processing Bypass" 32846 "Server Info" 32850 "RDS Data" 32859 "Ignition Switch State" 32862 "Mono" 32863 "Speed Volume Current Speed" 32865 "Zone Capabilities Extended" ;
VAL_ 2650735616 Industry_Code 0 "Global" 1 "Highway" 2 "Agriculture" 3 "Construction" 4 "Marine Industry" 5 "Industrial" ;
VAL_ 2650735616 Message_ID 0 "Unknown" 32769 "API Version" 32770 "Source" 32771 "Source Count" 32772 "Track Info" 32773 "Track Title" 32774 "Track Artist" 32775 "Track Album" 32776 "Cover Art" 32777 "Track Progress" 32778 "Tuner Align" 32779 "Tuner" 32780 "Marine Tuner" 32781 "Marine Squelch" 32782 "Marine Scan Mode" 32783 "Menu Action" 32784 "Menu Count" 32785 "Menu Item" 32786 "Menu Lock ID" 32787 "Aux Gain" 32788 "Setting" 32789 "Settings" 32790 "Update Firmware Result" 32791 "Mute" 32792 "Balance" 32793 "Low Pass Filter" 32794 "Sublevels" 32795 "Tone" 32796 "Volume Limits" 32797 "Volume" 32798 "Capabilities" 32799 "Line Level Control" 32800 "Power" 32801 "Unit Name" 32802 "Sirius" 32803 "SiriusXM Preset Event" 32804 "SiriusXM Channel" 32805 "SiriusXM Title" 32806 "SiriusXM Artist" 32807 "SiriusXM Genre" 32808 "SiriusXM Category" 32809 "SiriusXm Signal" 32810 "SiriusXM Parental Request" 32811 "SiriusXM Diagnostics" 32812 "SiriusXM Presets" 32813 "Zone Name" 32819 "IP Setting" 32824 "Multiroom" 32825 "Multiroom Status" 32829 "System Capabilities" 32830 "Part Number" 32832 "Processing Bypass" 32846 "Server Info" 32850 "RDS Data" 32859 "Ignition Switch State" 32862 "Mono" 32863 "Speed Volume Current Speed" 32865 "Zone Capabilities Extended" ;
VAL_ 2650735616 Enabled 0 "No" 1 "Yes" ;
VAL_ 2650735616 Industry_Code 0 "Global" 1 "Highway" 2 "Agriculture" 3 "Construction" 4 "Marine Industry" 5 "Industrial" ;
VAL_ 2650735616 Message_ID 0 "Unknown" 32769 "API Version" 32770 "Source" 32771 "Source Count" 32772 "Track Info" 32773 "Track Title" 32774 "Track Artist" 32775 "Track Album" 32776 "Cover Art" 32777 "Track Progress" 32778 "Tuner Align" 32779 "Tuner" 32780 "Marine Tuner" 32781 "Marine Squelch" 32782 "Marine Scan Mode" 32783 "Menu Action" 32784 "Menu Count" 32785 "Menu Item" 32786 "Menu Lock ID" 32787 "Aux Gain" 32788 "Setting" 32789 "Settings" 32790 "Update Firmware Result" 32791 "Mute" 32792 "Balance" 32793 "Low Pass Filter" 32794 "Sublevels" 32795 "Tone" 32796 "Volume Limits" 32797 "Volume" 32798 "Capabilities" 32799 "Line Level Control" 32800 "Power" 32801 "Unit Name" 32802 "Sirius" 32803 "SiriusXM Preset Event" 32804 "SiriusXM Channel" 32805 "SiriusXM Title" 32806 "SiriusXM Artist" 32807 "SiriusXM Genre" 32808 "SiriusXM Category" 32809 "SiriusXm Signal" 32810 "SiriusXM Parental Request" 32811 "SiriusXM Diagnostics" 32812 "SiriusXM Presets" 32813 "Zone Name" 32819 "IP Setting" 32824 "Multiroom" 32825 "Multiroom Status" 32829 "System Capabilities" 32830 "Part Number" 32832 "Processing Bypass" 32846 "Server Info" 32850 "RDS Data" 32859 "Ignition Switch State" 32862 "Mono" 32863 "Speed Volume Current Speed" 32865 "Zone Capabilities Extended" ;
VAL_ 2650735616 Enabled 0 "No" 1 "Yes" ;
VAL_ 2650735616 Industry_Code 0 "Global" 1 "Highway" 2 "Agriculture" 3 "Construction" 4 "Marine Industry" 5 "Industrial" ;
VAL_ 2650735616 Message_ID 0 "Unknown" 32769 "API Version" 32770 "Source" 32771 "Source Count" 32772 "Track Info" 32773 "Track Title" 32774 "Track Artist" 32775 "Track Album" 32776 "Cover Art" 32777 "Track Progress" 32778 "Tuner Align" 32779 "Tuner" 32780 "Marine Tuner" 32781 "Marine Squelch" 32782 "Marine Scan Mode" 32783 "Menu Action" 32784 "Menu Count" 32785 "Menu Item" 32786 "Menu Lock ID" 32787 "Aux Gain" 32788 "Setting" 32789 "Settings" 32790 "Update Firmware Result" 32791 "Mute" 32792 "Balance" 32793 "Low Pass Filter" 32794 "Sublevels" 32795 "Tone" 32796 "Volume Limits" 32797 "Volume" 32798 "Capabilities" 32799 "Line Level Control" 32800 "Power" 32801 "Unit Name" 32802 "Sirius" 32803 "SiriusXM Preset Event" 32804 "SiriusXM Channel" 32805 "SiriusXM Title" 32806 "SiriusXM Artist" 32807 "SiriusXM Genre" 32808 "SiriusXM Category" 32809 "SiriusXm Signal" 32810 "SiriusXM Parental Request" 32811 "SiriusXM Diagnostics" 32812 "SiriusXM Presets" 32813 "Zone Name" 32819 "IP Setting" 32824 "Multiroom" 32825 "Multiroom Status" 32829 "System Capabilities" 32830 "Part Number" 32832 "Processing Bypass" 32846 "Server Info" 32850 "RDS Data" 32859 "Ignition Switch State" 32862 "Mono" 32863 "Speed Volume Current Speed" 32865 "Zone Capabilities Extended" ;
VAL_ 2650735616 Available 0 "No" 1 "Yes" ;
VAL_ 2650735616 Industry_Code 0 "Global" 1 "Highway" 2 "Agriculture" 3 "Construction" 4 "Marine Industry" 5 "Industrial" ;
VAL_ 2650735616 Message_ID 0 "Unknown" 32769 "API Version" 32770 "Source" 32771 "Source Count" 32772 "Track Info" 32773 "Track Title" 32774 "Track Artist" 32775 "Track Album" 32776 "Cover Art" 32777 "Track Progress" 32778 "Tuner Align" 32779 "Tuner" 32780 "Marine Tuner" 32781 "Marine Squelch" 32782 "Marine Scan Mode" 32783 "Menu Action" 32784 "Menu Count" 32785 "Menu Item" 32786 "Menu Lock ID" 32787 "Aux Gain" 32788 "Setting" 32789 "Settings" 32790 "Update Firmware Result" 32791 "Mute" 32792 "Balance" 32793 "Low Pass Filter" 32794 "Sublevels" 32795 "Tone" 32796 "Volume Limits" 32797 "Volume" 32798 "Capabilities" 32799 "Line Level Control" 32800 "Power" 32801 "Unit Name" 32802 "Sirius" 32803 "SiriusXM Preset Event" 32804 "SiriusXM Channel" 32805 "SiriusXM Title" 32806 "SiriusXM Artist" 32807 "SiriusXM Genre" 32808 "SiriusXM Category" 32809 "SiriusXm Signal" 32810 "SiriusXM Parental Request" 32811 "SiriusXM Diagnostics" 32812 "SiriusXM Presets" 32813 "Zone Name" 32819 "IP Setting" 32824 "Multiroom" 32825 "Multiroom Status" 32829 "System Capabilities" 32830 "Part Number" 32832 "Processing Bypass" 32846 "Server Info" 32850 "RDS Data" 32859 "Ignition Switch State" 32862 "Mono" 32863 "Speed Volume Current Speed" 32865 "Zone Capabilities Extended" ;
VAL_ 2650735616 Mute 1 "Mute On" 2 "Mute Off" ;
VAL_ 2650735616 Industry_Code 0 "Global" 1 "Highway" 2 "Agriculture" 3 "Construction" 4 "Marine Industry" 5 "Industrial" ;
VAL_ 2650735616 Message_ID 0 "Unknown" 32769 "API Version" 32770 "Source" 32771 "Source Count" 32772 "Track Info" 32773 "Track Title" 32774 "Track Artist" 32775 "Track Album" 32776 "Cover Art" 32777 "Track Progress" 32778 "Tuner Align" 32779 "Tuner" 32780 "Marine Tuner" 32781 "Marine Squelch" 32782 "Marine Scan Mode" 32783 "Menu Action" 32784 "Menu Count" 32785 "Menu Item" 32786 "Menu Lock ID" 32787 "Aux Gain" 32788 "Setting" 32789 "Settings" 32790 "Update Firmware Result" 32791 "Mute" 32792 "Balance" 32793 "Low Pass Filter" 32794 "Sublevels" 32795 "Tone" 32796 "Volume Limits" 32797 "Volume" 32798 "Capabilities" 32799 "Line Level Control" 32800 "Power" 32801 "Unit Name" 32802 "Sirius" 32803 "SiriusXM Preset Event" 32804 "SiriusXM Channel" 32805 "SiriusXM Title" 32806 "SiriusXM Artist" 32807 "SiriusXM Genre" 32808 "SiriusXM Category" 32809 "SiriusXm Signal" 32810 "SiriusXM Parental Request" 32811 "SiriusXM Diagnostics" 32812 "SiriusXM Presets" 32813 "Zone Name" 32819 "IP Setting" 32824 "Multiroom" 32825 "Multiroom Status" 32829 "System Capabilities" 32830 "Part Number" 32832 "Processing Bypass" 32846 "Server Info" 32850 "RDS Data" 32859 "Ignition Switch State" 32862 "Mono" 32863 "Speed Volume Current Speed" 32865 "Zone Capabilities Extended" ;
VAL_ 2650735616 State 1 "On" 2 "Off" ;
VAL_ 2650735616 Industry_Code 0 "Global" 1 "Highway" 2 "Agriculture" 3 "Construction" 4 "Marine Industry" 5 "Industrial" ;
VAL_ 2650735616 Message_ID 0 "Unknown" 32769 "API Version" 32770 "Source" 32771 "Source Count" 32772 "Track Info" 32773 "Track Title" 32774 "Track Artist" 32775 "Track Album" 32776 "Cover Art" 32777 "Track Progress" 32778 "Tuner Align" 32779 "Tuner" 32780 "Marine Tuner" 32781 "Marine Squelch" 32782 "Marine Scan Mode" 32783 "Menu Action" 32784 "Menu Count" 32785 "Menu Item" 32786 "Menu Lock ID" 32787 "Aux Gain" 32788 "Setting" 32789 "Settings" 32790 "Update Firmware Result" 32791 "Mute" 32792 "Balance" 32793 "Low Pass Filter" 32794 "Sublevels" 32795 "Tone" 32796 "Volume Limits" 32797 "Volume" 32798 "Capabilities" 32799 "Line Level Control" 32800 "Power" 32801 "Unit Name" 32802 "Sirius" 32803 "SiriusXM Preset Event" 32804 "SiriusXM Channel" 32805 "SiriusXM Title" 32806 "SiriusXM Artist" 32807 "SiriusXM Genre" 32808 "SiriusXM Category" 32809 "SiriusXm Signal" 32810 "SiriusXM Parental Request" 32811 "SiriusXM Diagnostics" 32812 "SiriusXM Presets" 32813 "Zone Name" 32819 "IP Setting" 32824 "Multiroom" 32825 "Multiroom Status" 32829 "System Capabilities" 32830 "Part Number" 32832 "Processing Bypass" 32846 "Server Info" 32850 "RDS Data" 32859 "Ignition Switch State" 32862 "Mono" 32863 "Speed Volume Current Speed" 32865 "Zone Capabilities Extended" ;
VAL_ 2650735616 Bypass 0 "No" 1 "Yes" ;
VAL_ 2650735616 Industry_Code 0 "Global" 1 "Highway" 2 "Agriculture" 3 "Construction" 4 "Marine Industry" 5 "Industrial" ;
VAL_ 2650735616 Message_ID 0 "Unknown" 32769 "API Version" 32770 "Source" 32771 "Source Count" 32772 "Track Info" 32773 "Track Title" 32774 "Track Artist" 32775 "Track Album" 32776 "Cover Art" 32777 "Track Progress" 32778 "Tuner Align" 32779 "Tuner" 32780 "Marine Tuner" 32781 "Marine Squelch" 32782 "Marine Scan Mode" 32783 "Menu Action" 32784 "Menu Count" 32785 "Menu Item" 32786 "Menu Lock ID" 32787 "Aux Gain" 32788 "Setting" 32789 "Settings" 32790 "Update Firmware Result" 32791 "Mute" 32792 "Balance" 32793 "Low Pass Filter" 32794 "Sublevels" 32795 "Tone" 32796 "Volume Limits" 32797 "Volume" 32798 "Capabilities" 32799 "Line Level Control" 32800 "Power" 32801 "Unit Name" 32802 "Sirius" 32803 "SiriusXM Preset Event" 32804 "SiriusXM Channel" 32805 "SiriusXM Title" 32806 "SiriusXM Artist" 32807 "SiriusXM Genre" 32808 "SiriusXM Category" 32809 "SiriusXm Signal" 32810 "SiriusXM Parental Request" 32811 "SiriusXM Diagnostics" 32812 "SiriusXM Presets" 32813 "Zone Name" 32819 "IP Setting" 32824 "Multiroom" 32825 "Multiroom Status" 32829 "System Capabilities" 32830 "Part Number" 32832 "Processing Bypass" 32846 "Server Info" 32850 "RDS Data" 32859 "Ignition Switch State" 32862 "Mono" 32863 "Speed Volume Current Speed" 32865 "Zone Capabilities Extended" ;
VAL_ 2650735616 Industry_Code 0 "Global" 1 "Highway" 2 "Agriculture" 3 "Construction" 4 "Marine Industry" 5 "Industrial" ;
VAL_ 2650735616 Message_ID 0 "Unknown" 32769 "API Version" 32770 "Source" 32771 "Source Count" 32772 "Track Info" 32773 "Track Title" 32774 "Track Artist" 32775 "Track Album" 32776 "Cover Art" 32777 "Track Progress" 32778 "Tuner Align" 32779 "Tuner" 32780 "Marine Tuner" 32781 "Marine Squelch" 32782 "Marine Scan Mode" 32783 "Menu Action" 32784 "Menu Count" 32785 "Menu Item" 32786 "Menu Lock ID" 32787 "Aux Gain" 32788 "Setting" 32789 "Settings" 32790 "Update Firmware Result" 32791 "Mute" 32792 "Balance" 32793 "Low Pass Filter" 32794 "Sublevels" 32795 "Tone" 32796 "Volume Limits" 32797 "Volume" 32798 "Capabilities" 32799 "Line Level Control" 32800 "Power" 32801 "Unit Name" 32802 "Sirius" 32803 "SiriusXM Preset Event" 32804 "SiriusXM Channel" 32805 "SiriusXM Title" 32806 "SiriusXM Artist" 32807 "SiriusXM Genre" 32808 "SiriusXM Category" 32809 "SiriusXm Signal" 32810 "SiriusXM Parental Request" 32811 "SiriusXM Diagnostics" 32812 "SiriusXM Presets" 32813 "Zone Name" 32819 "IP Setting" 32824 "Multiroom" 32825 "Multiroom Status" 32829 "System Capabilities" 32830 "Part Number" 32832 "Processing Bypass" 32846 "Server Info" 32850 "RDS Data" 32859 "Ignition Switch State" 32862 "Mono" 32863 "Speed Volume Current Speed" 32865 "Zone Capabilities Extended" ;
VAL_ 2650735616 ID 0 "Alpha Search Threshold" 1 "iPod Subtitles" 2 "Zone 2 Linked" 3 "Zone 2 Enabled" 4 "Zone 3 Enabled" 5 "Zone 4 Enabled" 6 "Telemute" 7 "Tuner Region" 8 "Marine Zone" 9 "USB repeat" 10 "USB shuffle" 11 "iPod Album Artwork" 12 "iPod repeat" 13 "iPod shuffle" 14 "AM Preset 0" 15 "AM Preset 1" 16 "AM Preset 2" 17 "AM Preset 3" 18 "AM Preset 4" 19 "AM Preset 5" 20 "AM Preset 6" 21 "AM Preset 7" 22 "AM Preset 8" 23 "AM Preset 9" 24 "AM Preset 10" 25 "AM Preset 11" 26 "AM Preset 12" 27 "AM Preset 13" 28 "AM Preset 14" 29 "FM Preset 0" 30 "FM Preset 1" 31 "FM Preset 2" 32 "FM Preset 3" 33 "FM Preset 4" 34 "FM Preset 5" 35 "FM Preset 6" 36 "FM Preset 7" 37 "FM Preset 8" 38 "FM Preset 9" 39 "FM Preset 10" 40 "FM Preset 11" 41 "FM Preset 12" 42 "FM Preset 13" 43 "FM Preset 14" 44 "VHF Preset 0" 45 "VHF Preset 1" 46 "VHF Preset 2" 47 "VHF Preset 3" 48 "VHF Preset 4" 49 "VHF Preset 5" 50 "VHF Preset 6" 51 "VHF Preset 7" 52 "VHF Preset 8" 53 "VHF Preset 9" 54 "VHF Preset 10" 55 "VHF Preset 11" 56 "VHF Preset 12" 57 "VHF Preset 13" 58 "VHF Preset 14" 59 "Clock Time" 60 "Clock Alarm" 61 "iPod Video Signal" 62 "iPod Monitor Aspect" 63 "Aux Name Index" 64 "AM Enabled" 65 "VHF Enabled" 66 "Language" 67 "Internal Amps On" 68 "MTP Repeat" 69 "MTP Shuffle" 70 "Id Accessory Source" 71 "NMEA Power" 72 "Low Power Mode" 73 "DVD region" 74 "Volume Zone Sync" 75 "Max Volume Start" 76 "BT Auto Connect" 77 "Null Setting" ;
VAL_ 2650735616 Industry_Code 0 "Global" 1 "Highway" 2 "Agriculture" 3 "Construction" 4 "Marine Industry" 5 "Industrial" ;
VAL_ 2650735616 Message_ID 0 "Unknown" 32769 "API Version" 32770 "Source" 32771 "Source Count" 32772 "Track Info" 32773 "Track Title" 32774 "Track Artist" 32775 "Track Album" 32776 "Cover Art" 32777 "Track Progress" 32778 "Tuner Align" 32779 "Tuner" 32780 "Marine Tuner" 32781 "Marine Squelch" 32782 "Marine Scan Mode" 32783 "Menu Action" 32784 "Menu Count" 32785 "Menu Item" 32786 "Menu Lock ID" 32787 "Aux Gain" 32788 "Setting" 32789 "Settings" 32790 "Update Firmware Result" 32791 "Mute" 32792 "Balance" 32793 "Low Pass Filter" 32794 "Sublevels" 32795 "Tone" 32796 "Volume Limits" 32797 "Volume" 32798 "Capabilities" 32799 "Line Level Control" 32800 "Power" 32801 "Unit Name" 32802 "Sirius" 32803 "SiriusXM Preset Event" 32804 "SiriusXM Channel" 32805 "SiriusXM Title" 32806 "SiriusXM Artist" 32807 "SiriusXM Genre" 32808 "SiriusXM Category" 32809 "SiriusXm Signal" 32810 "SiriusXM Parental Request" 32811 "SiriusXM Diagnostics" 32812 "SiriusXM Presets" 32813 "Zone Name" 32819 "IP Setting" 32824 "Multiroom" 32825 "Multiroom Status" 32829 "System Capabilities" 32830 "Part Number" 32832 "Processing Bypass" 32846 "Server Info" 32850 "RDS Data" 32859 "Ignition Switch State" 32862 "Mono" 32863 "Speed Volume Current Speed" 32865 "Zone Capabilities Extended" ;
VAL_ 2650735616 Industry_Code 0 "Global" 1 "Highway" 2 "Agriculture" 3 "Construction" 4 "Marine Industry" 5 "Industrial" ;
VAL_ 2650735616 Message_ID 0 "Unknown" 32769 "API Version" 32770 "Source" 32771 "Source Count" 32772 "Track Info" 32773 "Track Title" 32774 "Track Artist" 32775 "Track Album" 32776 "Cover Art" 32777 "Track Progress" 32778 "Tuner Align" 32779 "Tuner" 32780 "Marine Tuner" 32781 "Marine Squelch" 32782 "Marine Scan Mode" 32783 "Menu Action" 32784 "Menu Count" 32785 "Menu Item" 32786 "Menu Lock ID" 32787 "Aux Gain" 32788 "Setting" 32789 "Settings" 32790 "Update Firmware Result" 32791 "Mute" 32792 "Balance" 32793 "Low Pass Filter" 32794 "Sublevels" 32795 "Tone" 32796 "Volume Limits" 32797 "Volume" 32798 "Capabilities" 32799 "Line Level Control" 32800 "Power" 32801 "Unit Name" 32802 "Sirius" 32803 "SiriusXM Preset Event" 32804 "SiriusXM Channel" 32805 "SiriusXM Title" 32806 "SiriusXM Artist" 32807 "SiriusXM Genre" 32808 "SiriusXM Category" 32809 "SiriusXm Signal" 32810 "SiriusXM Parental Request" 32811 "SiriusXM Diagnostics" 32812 "SiriusXM Presets" 32813 "Zone Name" 32819 "IP Setting" 32824 "Multiroom" 32825 "Multiroom Status" 32829 "System Capabilities" 32830 "Part Number" 32832 "Processing Bypass" 32846 "Server Info" 32850 "RDS Data" 32859 "Ignition Switch State" 32862 "Mono" 32863 "Speed Volume Current Speed" 32865 "Zone Capabilities Extended" ;
VAL_ 2650735616 Com_State 1 "Off" 2 "Initialising" 3 "On" 255 "Unknown" ;
VAL_ 2650735616 Alert 1 "Off" 2 "Initialising" 3 "On" 255 "Unknown" ;
VAL_ 2650735616 Tuning_Mode 1 "Normal" 2 "Category" 3 "Preset" ;
VAL_ 2650735616 Industry_Code 0 "Global" 1 "Highway" 2 "Agriculture" 3 "Construction" 4 "Marine Industry" 5 "Industrial" ;
VAL_ 2650735616 Message_ID 0 "Unknown" 32769 "API Version" 32770 "Source" 32771 "Source Count" 32772 "Track Info" 32773 "Track Title" 32774 "Track Artist" 32775 "Track Album" 32776 "Cover Art" 32777 "Track Progress" 32778 "Tuner Align" 32779 "Tuner" 32780 "Marine Tuner" 32781 "Marine Squelch" 32782 "Marine Scan Mode" 32783 "Menu Action" 32784 "Menu Count" 32785 "Menu Item" 32786 "Menu Lock ID" 32787 "Aux Gain" 32788 "Setting" 32789 "Settings" 32790 "Update Firmware Result" 32791 "Mute" 32792 "Balance" 32793 "Low Pass Filter" 32794 "Sublevels" 32795 "Tone" 32796 "Volume Limits" 32797 "Volume" 32798 "Capabilities" 32799 "Line Level Control" 32800 "Power" 32801 "Unit Name" 32802 "Sirius" 32803 "SiriusXM Preset Event" 32804 "SiriusXM Channel" 32805 "SiriusXM Title" 32806 "SiriusXM Artist" 32807 "SiriusXM Genre" 32808 "SiriusXM Category" 32809 "SiriusXm Signal" 32810 "SiriusXM Parental Request" 32811 "SiriusXM Diagnostics" 32812 "SiriusXM Presets" 32813 "Zone Name" 32819 "IP Setting" 32824 "Multiroom" 32825 "Multiroom Status" 32829 "System Capabilities" 32830 "Part Number" 32832 "Processing Bypass" 32846 "Server Info" 32850 "RDS Data" 32859 "Ignition Switch State" 32862 "Mono" 32863 "Speed Volume Current Speed" 32865 "Zone Capabilities Extended" ;
VAL_ 2650735616 Industry_Code 0 "Global" 1 "Highway" 2 "Agriculture" 3 "Construction" 4 "Marine Industry" 5 "Industrial" ;
VAL_ 2650735616 Message_ID 0 "Unknown" 32769 "API Version" 32770 "Source" 32771 "Source Count" 32772 "Track Info" 32773 "Track Title" 32774 "Track Artist" 32775 "Track Album" 32776 "Cover Art" 32777 "Track Progress" 32778 "Tuner Align" 32779 "Tuner" 32780 "Marine Tuner" 32781 "Marine Squelch" 32782 "Marine Scan Mode" 32783 "Menu Action" 32784 "Menu Count" 32785 "Menu Item" 32786 "Menu Lock ID" 32787 "Aux Gain" 32788 "Setting" 32789 "Settings" 32790 "Update Firmware Result" 32791 "Mute" 32792 "Balance" 32793 "Low Pass Filter" 32794 "Sublevels" 32795 "Tone" 32796 "Volume Limits" 32797 "Volume" 32798 "Capabilities" 32799 "Line Level Control" 32800 "Power" 32801 "Unit Name" 32802 "Sirius" 32803 "SiriusXM Preset Event" 32804 "SiriusXM Channel" 32805 "SiriusXM Title" 32806 "SiriusXM Artist" 32807 "SiriusXM Genre" 32808 "SiriusXM Category" 32809 "SiriusXm Signal" 32810 "SiriusXM Parental Request" 32811 "SiriusXM Diagnostics" 32812 "SiriusXM Presets" 32813 "Zone Name" 32819 "IP Setting" 32824 "Multiroom" 32825 "Multiroom Status" 32829 "System Capabilities" 32830 "Part Number" 32832 "Processing Bypass" 32846 "Server Info" 32850 "RDS Data" 32859 "Ignition Switch State" 32862 "Mono" 32863 "Speed Volume Current Speed" 32865 "Zone Capabilities Extended" ;
VAL_ 2650735616 Industry_Code 0 "Global" 1 "Highway" 2 "Agriculture" 3 "Construction" 4 "Marine Industry" 5 "Industrial" ;
VAL_ 2650735616 Message_ID 0 "Unknown" 32769 "API Version" 32770 "Source" 32771 "Source Count" 32772 "Track Info" 32773 "Track Title" 32774 "Track Artist" 32775 "Track Album" 32776 "Cover Art" 32777 "Track Progress" 32778 "Tuner Align" 32779 "Tuner" 32780 "Marine Tuner" 32781 "Marine Squelch" 32782 "Marine Scan Mode" 32783 "Menu Action" 32784 "Menu Count" 32785 "Menu Item" 32786 "Menu Lock ID" 32787 "Aux Gain" 32788 "Setting" 32789 "Settings" 32790 "Update Firmware Result" 32791 "Mute" 32792 "Balance" 32793 "Low Pass Filter" 32794 "Sublevels" 32795 "Tone" 32796 "Volume Limits" 32797 "Volume" 32798 "Capabilities" 32799 "Line Level Control" 32800 "Power" 32801 "Unit Name" 32802 "Sirius" 32803 "SiriusXM Preset Event" 32804 "SiriusXM Channel" 32805 "SiriusXM Title" 32806 "SiriusXM Artist" 32807 "SiriusXM Genre" 32808 "SiriusXM Category" 32809 "SiriusXm Signal" 32810 "SiriusXM Parental Request" 32811 "SiriusXM Diagnostics" 32812 "SiriusXM Presets" 32813 "Zone Name" 32819 "IP Setting" 32824 "Multiroom" 32825 "Multiroom Status" 32829 "System Capabilities" 32830 "Part Number" 32832 "Processing Bypass" 32846 "Server Info" 32850 "RDS Data" 32859 "Ignition Switch State" 32862 "Mono" 32863 "Speed Volume Current Speed" 32865 "Zone Capabilities Extended" ;
VAL_ 2650735616 Industry_Code 0 "Global" 1 "Highway" 2 "Agriculture" 3 "Construction" 4 "Marine Industry" 5 "Industrial" ;
VAL_ 2650735616 Message_ID 0 "Unknown" 32769 "API Version" 32770 "Source" 32771 "Source Count" 32772 "Track Info" 32773 "Track Title" 32774 "Track Artist" 32775 "Track Album" 32776 "Cover Art" 32777 "Track Progress" 32778 "Tuner Align" 32779 "Tuner" 32780 "Marine Tuner" 32781 "Marine Squelch" 32782 "Marine Scan Mode" 32783 "Menu Action" 32784 "Menu Count" 32785 "Menu Item" 32786 "Menu Lock ID" 32787 "Aux Gain" 32788 "Setting" 32789 "Settings" 32790 "Update Firmware Result" 32791 "Mute" 32792 "Balance" 32793 "Low Pass Filter" 32794 "Sublevels" 32795 "Tone" 32796 "Volume Limits" 32797 "Volume" 32798 "Capabilities" 32799 "Line Level Control" 32800 "Power" 32801 "Unit Name" 32802 "Sirius" 32803 "SiriusXM Preset Event" 32804 "SiriusXM Channel" 32805 "SiriusXM Title" 32806 "SiriusXM Artist" 32807 "SiriusXM Genre" 32808 "SiriusXM Category" 32809 "SiriusXm Signal" 32810 "SiriusXM Parental Request" 32811 "SiriusXM Diagnostics" 32812 "SiriusXM Presets" 32813 "Zone Name" 32819 "IP Setting" 32824 "Multiroom" 32825 "Multiroom Status" 32829 "System Capabilities" 32830 "Part Number" 32832 "Processing Bypass" 32846 "Server Info" 32850 "RDS Data" 32859 "Ignition Switch State" 32862 "Mono" 32863 "Speed Volume Current Speed" 32865 "Zone Capabilities Extended" ;
VAL_ 2650735616 Industry_Code 0 "Global" 1 "Highway" 2 "Agriculture" 3 "Construction" 4 "Marine Industry" 5 "Industrial" ;
VAL_ 2650735616 Message_ID 0 "Unknown" 32769 "API Version" 32770 "Source" 32771 "Source Count" 32772 "Track Info" 32773 "Track Title" 32774 "Track Artist" 32775 "Track Album" 32776 "Cover Art" 32777 "Track Progress" 32778 "Tuner Align" 32779 "Tuner" 32780 "Marine Tuner" 32781 "Marine Squelch" 32782 "Marine Scan Mode" 32783 "Menu Action" 32784 "Menu Count" 32785 "Menu Item" 32786 "Menu Lock ID" 32787 "Aux Gain" 32788 "Setting" 32789 "Settings" 32790 "Update Firmware Result" 32791 "Mute" 32792 "Balance" 32793 "Low Pass Filter" 32794 "Sublevels" 32795 "Tone" 32796 "Volume Limits" 32797 "Volume" 32798 "Capabilities" 32799 "Line Level Control" 32800 "Power" 32801 "Unit Name" 32802 "Sirius" 32803 "SiriusXM Preset Event" 32804 "SiriusXM Channel" 32805 "SiriusXM Title" 32806 "SiriusXM Artist" 32807 "SiriusXM Genre" 32808 "SiriusXM Category" 32809 "SiriusXm Signal" 32810 "SiriusXM Parental Request" 32811 "SiriusXM Diagnostics" 32812 "SiriusXM Presets" 32813 "Zone Name" 32819 "IP Setting" 32824 "Multiroom" 32825 "Multiroom Status" 32829 "System Capabilities" 32830 "Part Number" 32832 "Processing Bypass" 32846 "Server Info" 32850 "RDS Data" 32859 "Ignition Switch State" 32862 "Mono" 32863 "Speed Volume Current Speed" 32865 "Zone Capabilities Extended" ;
VAL_ 2650735616 Industry_Code 0 "Global" 1 "Highway" 2 "Agriculture" 3 "Construction" 4 "Marine Industry" 5 "Industrial" ;
VAL_ 2650735616 Message_ID 0 "Unknown" 32769 "API Version" 32770 "Source" 32771 "Source Count" 32772 "Track Info" 32773 "Track Title" 32774 "Track Artist" 32775 "Track Album" 32776 "Cover Art" 32777 "Track Progress" 32778 "Tuner Align" 32779 "Tuner" 32780 "Marine Tuner" 32781 "Marine Squelch" 32782 "Marine Scan Mode" 32783 "Menu Action" 32784 "Menu Count" 32785 "Menu Item" 32786 "Menu Lock ID" 32787 "Aux Gain" 32788 "Setting" 32789 "Settings" 32790 "Update Firmware Result" 32791 "Mute" 32792 "Balance" 32793 "Low Pass Filter" 32794 "Sublevels" 32795 "Tone" 32796 "Volume Limits" 32797 "Volume" 32798 "Capabilities" 32799 "Line Level Control" 32800 "Power" 32801 "Unit Name" 32802 "Sirius" 32803 "SiriusXM Preset Event" 32804 "SiriusXM Channel" 32805 "SiriusXM Title" 32806 "SiriusXM Artist" 32807 "SiriusXM Genre" 32808 "SiriusXM Category" 32809 "SiriusXm Signal" 32810 "SiriusXM Parental Request" 32811 "SiriusXM Diagnostics" 32812 "SiriusXM Presets" 32813 "Zone Name" 32819 "IP Setting" 32824 "Multiroom" 32825 "Multiroom Status" 32829 "System Capabilities" 32830 "Part Number" 32832 "Processing Bypass" 32846 "Server Info" 32850 "RDS Data" 32859 "Ignition Switch State" 32862 "Mono" 32863 "Speed Volume Current Speed" 32865 "Zone Capabilities Extended" ;
VAL_ 2650735616 Industry_Code 0 "Global" 1 "Highway" 2 "Agriculture" 3 "Construction" 4 "Marine Industry" 5 "Industrial" ;
VAL_ 2650735616 Message_ID 0 "Unknown" 32769 "API Version" 32770 "Source" 32771 "Source Count" 32772 "Track Info" 32773 "Track Title" 32774 "Track Artist" 32775 "Track Album" 32776 "Cover Art" 32777 "Track Progress" 32778 "Tuner Align" 32779 "Tuner" 32780 "Marine Tuner" 32781 "Marine Squelch" 32782 "Marine Scan Mode" 32783 "Menu Action" 32784 "Menu Count" 32785 "Menu Item" 32786 "Menu Lock ID" 32787 "Aux Gain" 32788 "Setting" 32789 "Settings" 32790 "Update Firmware Result" 32791 "Mute" 32792 "Balance" 32793 "Low Pass Filter" 32794 "Sublevels" 32795 "Tone" 32796 "Volume Limits" 32797 "Volume" 32798 "Capabilities" 32799 "Line Level Control" 32800 "Power" 32801 "Unit Name" 32802 "Sirius" 32803 "SiriusXM Preset Event" 32804 "SiriusXM Channel" 32805 "SiriusXM Title" 32806 "SiriusXM Artist" 32807 "SiriusXM Genre" 32808 "SiriusXM Category" 32809 "SiriusXm Signal" 32810 "SiriusXM Parental Request" 32811 "SiriusXM Diagnostics" 32812 "SiriusXM Presets" 32813 "Zone Name" 32819 "IP Setting" 32824 "Multiroom" 32825 "Multiroom Status" 32829 "System Capabilities" 32830 "Part Number" 32832 "Processing Bypass" 32846 "Server Info" 32850 "RDS Data" 32859 "Ignition Switch State" 32862 "Mono" 32863 "Speed Volume Current Speed" 32865 "Zone Capabilities Extended" ;
VAL_ 2650735616 Industry_Code 0 "Global" 1 "Highway" 2 "Agriculture" 3 "Construction" 4 "Marine Industry" 5 "Industrial" ;
VAL_ 2650735616 Message_ID 0 "Unknown" 32769 "API Version" 32770 "Source" 32771 "Source Count" 32772 "Track Info" 32773 "Track Title" 32774 "Track Artist" 32775 "Track Album" 32776 "Cover Art" 32777 "Track Progress" 32778 "Tuner Align" 32779 "Tuner" 32780 "Marine Tuner" 32781 "Marine Squelch" 32782 "Marine Scan Mode" 32783 "Menu Action" 32784 "Menu Count" 32785 "Menu Item" 32786 "Menu Lock ID" 32787 "Aux Gain" 32788 "Setting" 32789 "Settings" 32790 "Update Firmware Result" 32791 "Mute" 32792 "Balance" 32793 "Low Pass Filter" 32794 "Sublevels" 32795 "Tone" 32796 "Volume Limits" 32797 "Volume" 32798 "Capabilities" 32799 "Line Level Control" 32800 "Power" 32801 "Unit Name" 32802 "Sirius" 32803 "SiriusXM Preset Event" 32804 "SiriusXM Channel" 32805 "SiriusXM Title" 32806 "SiriusXM Artist" 32807 "SiriusXM Genre" 32808 "SiriusXM Category" 32809 "SiriusXm Signal" 32810 "SiriusXM Parental Request" 32811 "SiriusXM Diagnostics" 32812 "SiriusXM Presets" 32813 "Zone Name" 32819 "IP Setting" 32824 "Multiroom" 32825 "Multiroom Status" 32829 "System Capabilities" 32830 "Part Number" 32832 "Processing Bypass" 32846 "Server Info" 32850 "RDS Data" 32859 "Ignition Switch State" 32862 "Mono" 32863 "Speed Volume Current Speed" 32865 "Zone Capabilities Extended" ;
VAL_ 2650735616 Source_Type 0 "AM" 1 "FM" 2 "Aux" 3 "Sirius" 4 "Ipod" 5 "USB" 6 "DVD" 7 "VHF" 8 "Invalid" 9 "MTP" 10 "Bluetooth" 11 "ARC" 12 "Android" 13 "Pandora" 14 "DAB" 15 "AirPlay" 16 "UPNP" 17 "Unknown" ;
VAL_ 2650735616 Industry_Code 0 "Global" 1 "Highway" 2 "Agriculture" 3 "Construction" 4 "Marine Industry" 5 "Industrial" ;
VAL_ 2650735616 Message_ID 0 "Unknown" 32769 "API Version" 32770 "Source" 32771 "Source Count" 32772 "Track Info" 32773 "Track Title" 32774 "Track Artist" 32775 "Track Album" 32776 "Cover Art" 32777 "Track Progress" 32778 "Tuner Align" 32779 "Tuner" 32780 "Marine Tuner" 32781 "Marine Squelch" 32782 "Marine Scan Mode" 32783 "Menu Action" 32784 "Menu Count" 32785 "Menu Item" 32786 "Menu Lock ID" 32787 "Aux Gain" 32788 "Setting" 32789 "Settings" 32790 "Update Firmware Result" 32791 "Mute" 32792 "Balance" 32793 "Low Pass Filter" 32794 "Sublevels" 32795 "Tone" 32796 "Volume Limits" 32797 "Volume" 32798 "Capabilities" 32799 "Line Level Control" 32800 "Power" 32801 "Unit Name" 32802 "Sirius" 32803 "SiriusXM Preset Event" 32804 "SiriusXM Channel" 32805 "SiriusXM Title" 32806 "SiriusXM Artist" 32807 "SiriusXM Genre" 32808 "SiriusXM Category" 32809 "SiriusXm Signal" 32810 "SiriusXM Parental Request" 32811 "SiriusXM Diagnostics" 32812 "SiriusXM Presets" 32813 "Zone Name" 32819 "IP Setting" 32824 "Multiroom" 32825 "Multiroom Status" 32829 "System Capabilities" 32830 "Part Number" 32832 "Processing Bypass" 32846 "Server Info" 32850 "RDS Data" 32859 "Ignition Switch State" 32862 "Mono" 32863 "Speed Volume Current Speed" 32865 "Zone Capabilities Extended" ;
VAL_ 2650735616 Industry_Code 0 "Global" 1 "Highway" 2 "Agriculture" 3 "Construction" 4 "Marine Industry" 5 "Industrial" ;
VAL_ 2650735616 Message_ID 0 "Unknown" 32769 "API Version" 32770 "Source" 32771 "Source Count" 32772 "Track Info" 32773 "Track Title" 32774 "Track Artist" 32775 "Track Album" 32776 "Cover Art" 32777 "Track Progress" 32778 "Tuner Align" 32779 "Tuner" 32780 "Marine Tuner" 32781 "Marine Squelch" 32782 "Marine Scan Mode" 32783 "Menu Action" 32784 "Menu Count" 32785 "Menu Item" 32786 "Menu Lock ID" 32787 "Aux Gain" 32788 "Setting" 32789 "Settings" 32790 "Update Firmware Result" 32791 "Mute" 32792 "Balance" 32793 "Low Pass Filter" 32794 "Sublevels" 32795 "Tone" 32796 "Volume Limits" 32797 "Volume" 32798 "Capabilities" 32799 "Line Level Control" 32800 "Power" 32801 "Unit Name" 32802 "Sirius" 32803 "SiriusXM Preset Event" 32804 "SiriusXM Channel" 32805 "SiriusXM Title" 32806 "SiriusXM Artist" 32807 "SiriusXM Genre" 32808 "SiriusXM Category" 32809 "SiriusXm Signal" 32810 "SiriusXM Parental Request" 32811 "SiriusXM Diagnostics" 32812 "SiriusXM Presets" 32813 "Zone Name" 32819 "IP Setting" 32824 "Multiroom" 32825 "Multiroom Status" 32829 "System Capabilities" 32830 "Part Number" 32832 "Processing Bypass" 32846 "Server Info" 32850 "RDS Data" 32859 "Ignition Switch State" 32862 "Mono" 32863 "Speed Volume Current Speed" 32865 "Zone Capabilities Extended" ;
VAL_ 2650735616 Industry_Code 0 "Global" 1 "Highway" 2 "Agriculture" 3 "Construction" 4 "Marine Industry" 5 "Industrial" ;
VAL_ 2650735616 Message_ID 0 "Unknown" 32769 "API Version" 32770 "Source" 32771 "Source Count" 32772 "Track Info" 32773 "Track Title" 32774 "Track Artist" 32775 "Track Album" 32776 "Cover Art" 32777 "Track Progress" 32778 "Tuner Align" 32779 "Tuner" 32780 "Marine Tuner" 32781 "Marine Squelch" 32782 "Marine Scan Mode" 32783 "Menu Action" 32784 "Menu Count" 32785 "Menu Item" 32786 "Menu Lock ID" 32787 "Aux Gain" 32788 "Setting" 32789 "Settings" 32790 "Update Firmware Result" 32791 "Mute" 32792 "Balance" 32793 "Low Pass Filter" 32794 "Sublevels" 32795 "Tone" 32796 "Volume Limits" 32797 "Volume" 32798 "Capabilities" 32799 "Line Level Control" 32800 "Power" 32801 "Unit Name" 32802 "Sirius" 32803 "SiriusXM Preset Event" 32804 "SiriusXM Channel" 32805 "SiriusXM Title" 32806 "SiriusXM Artist" 32807 "SiriusXM Genre" 32808 "SiriusXM Category" 32809 "SiriusXm Signal" 32810 "SiriusXM Parental Request" 32811 "SiriusXM Diagnostics" 32812 "SiriusXM Presets" 32813 "Zone Name" 32819 "IP Setting" 32824 "Multiroom" 32825 "Multiroom Status" 32829 "System Capabilities" 32830 "Part Number" 32832 "Processing Bypass" 32846 "Server Info" 32850 "RDS Data" 32859 "Ignition Switch State" 32862 "Mono" 32863 "Speed Volume Current Speed" 32865 "Zone Capabilities Extended" ;
VAL_ 2650735616 Industry_Code 0 "Global" 1 "Highway" 2 "Agriculture" 3 "Construction" 4 "Marine Industry" 5 "Industrial" ;
VAL_ 2650735616 Message_ID 0 "Unknown" 32769 "API Version" 32770 "Source" 32771 "Source Count" 32772 "Track Info" 32773 "Track Title" 32774 "Track Artist" 32775 "Track Album" 32776 "Cover Art" 32777 "Track Progress" 32778 "Tuner Align" 32779 "Tuner" 32780 "Marine Tuner" 32781 "Marine Squelch" 32782 "Marine Scan Mode" 32783 "Menu Action" 32784 "Menu Count" 32785 "Menu Item" 32786 "Menu Lock ID" 32787 "Aux Gain" 32788 "Setting" 32789 "Settings" 32790 "Update Firmware Result" 32791 "Mute" 32792 "Balance" 32793 "Low Pass Filter" 32794 "Sublevels" 32795 "Tone" 32796 "Volume Limits" 32797 "Volume" 32798 "Capabilities" 32799 "Line Level Control" 32800 "Power" 32801 "Unit Name" 32802 "Sirius" 32803 "SiriusXM Preset Event" 32804 "SiriusXM Channel" 32805 "SiriusXM Title" 32806 "SiriusXM Artist" 32807 "SiriusXM Genre" 32808 "SiriusXM Category" 32809 "SiriusXm Signal" 32810 "SiriusXM Parental Request" 32811 "SiriusXM Diagnostics" 32812 "SiriusXM Presets" 32813 "Zone Name" 32819 "IP Setting" 32824 "Multiroom" 32825 "Multiroom Status" 32829 "System Capabilities" 32830 "Part Number" 32832 "Processing Bypass" 32846 "Server Info" 32850 "RDS Data" 32859 "Ignition Switch State" 32862 "Mono" 32863 "Speed Volume Current Speed" 32865 "Zone Capabilities Extended" ;
VAL_ 2650735616 Industry_Code 0 "Global" 1 "Highway" 2 "Agriculture" 3 "Construction" 4 "Marine Industry" 5 "Industrial" ;
VAL_ 2650735616 Message_ID 0 "Unknown" 32769 "API Version" 32770 "Source" 32771 "Source Count" 32772 "Track Info" 32773 "Track Title" 32774 "Track Artist" 32775 "Track Album" 32776 "Cover Art" 32777 "Track Progress" 32778 "Tuner Align" 32779 "Tuner" 32780 "Marine Tuner" 32781 "Marine Squelch" 32782 "Marine Scan Mode" 32783 "Menu Action" 32784 "Menu Count" 32785 "Menu Item" 32786 "Menu Lock ID" 32787 "Aux Gain" 32788 "Setting" 32789 "Settings" 32790 "Update Firmware Result" 32791 "Mute" 32792 "Balance" 32793 "Low Pass Filter" 32794 "Sublevels" 32795 "Tone" 32796 "Volume Limits" 32797 "Volume" 32798 "Capabilities" 32799 "Line Level Control" 32800 "Power" 32801 "Unit Name" 32802 "Sirius" 32803 "SiriusXM Preset Event" 32804 "SiriusXM Channel" 32805 "SiriusXM Title" 32806 "SiriusXM Artist" 32807 "SiriusXM Genre" 32808 "SiriusXM Category" 32809 "SiriusXm Signal" 32810 "SiriusXM Parental Request" 32811 "SiriusXM Diagnostics" 32812 "SiriusXM Presets" 32813 "Zone Name" 32819 "IP Setting" 32824 "Multiroom" 32825 "Multiroom Status" 32829 "System Capabilities" 32830 "Part Number" 32832 "Processing Bypass" 32846 "Server Info" 32850 "RDS Data" 32859 "Ignition Switch State" 32862 "Mono" 32863 "Speed Volume Current Speed" 32865 "Zone Capabilities Extended" ;
VAL_ 2650735616 Industry_Code 0 "Global" 1 "Highway" 2 "Agriculture" 3 "Construction" 4 "Marine Industry" 5 "Industrial" ;
VAL_ 2650735616 Message_ID 0 "Unknown" 32769 "API Version" 32770 "Source" 32771 "Source Count" 32772 "Track Info" 32773 "Track Title" 32774 "Track Artist" 32775 "Track Album" 32776 "Cover Art" 32777 "Track Progress" 32778 "Tuner Align" 32779 "Tuner" 32780 "Marine Tuner" 32781 "Marine Squelch" 32782 "Marine Scan Mode" 32783 "Menu Action" 32784 "Menu Count" 32785 "Menu Item" 32786 "Menu Lock ID" 32787 "Aux Gain" 32788 "Setting" 32789 "Settings" 32790 "Update Firmware Result" 32791 "Mute" 32792 "Balance" 32793 "Low Pass Filter" 32794 "Sublevels" 32795 "Tone" 32796 "Volume Limits" 32797 "Volume" 32798 "Capabilities" 32799 "Line Level Control" 32800 "Power" 32801 "Unit Name" 32802 "Sirius" 32803 "SiriusXM Preset Event" 32804 "SiriusXM Channel" 32805 "SiriusXM Title" 32806 "SiriusXM Artist" 32807 "SiriusXM Genre" 32808 "SiriusXM Category" 32809 "SiriusXm Signal" 32810 "SiriusXM Parental Request" 32811 "SiriusXM Diagnostics" 32812 "SiriusXM Presets" 32813 "Zone Name" 32819 "IP Setting" 32824 "Multiroom" 32825 "Multiroom Status" 32829 "System Capabilities" 32830 "Part Number" 32832 "Processing Bypass" 32846 "Server Info" 32850 "RDS Data" 32859 "Ignition Switch State" 32862 "Mono" 32863 "Speed Volume Current Speed" 32865 "Zone Capabilities Extended" ;
VAL_ 2650735616 Source_ID 0 "AM" 1 "FM" ;
VAL_ 2650735616 Industry_Code 0 "Global" 1 "Highway" 2 "Agriculture" 3 "Construction" 4 "Marine Industry" 5 "Industrial" ;
VAL_ 2650735616 Message_ID 0 "Unknown" 32769 "API Version" 32770 "Source" 32771 "Source Count" 32772 "Track Info" 32773 "Track Title" 32774 "Track Artist" 32775 "Track Album" 32776 "Cover Art" 32777 "Track Progress" 32778 "Tuner Align" 32779 "Tuner" 32780 "Marine Tuner" 32781 "Marine Squelch" 32782 "Marine Scan Mode" 32783 "Menu Action" 32784 "Menu Count" 32785 "Menu Item" 32786 "Menu Lock ID" 32787 "Aux Gain" 32788 "Setting" 32789 "Settings" 32790 "Update Firmware Result" 32791 "Mute" 32792 "Balance" 32793 "Low Pass Filter" 32794 "Sublevels" 32795 "Tone" 32796 "Volume Limits" 32797 "Volume" 32798 "Capabilities" 32799 "Line Level Control" 32800 "Power" 32801 "Unit Name" 32802 "Sirius" 32803 "SiriusXM Preset Event" 32804 "SiriusXM Channel" 32805 "SiriusXM Title" 32806 "SiriusXM Artist" 32807 "SiriusXM Genre" 32808 "SiriusXM Category" 32809 "SiriusXm Signal" 32810 "SiriusXM Parental Request" 32811 "SiriusXM Diagnostics" 32812 "SiriusXM Presets" 32813 "Zone Name" 32819 "IP Setting" 32824 "Multiroom" 32825 "Multiroom Status" 32829 "System Capabilities" 32830 "Part Number" 32832 "Processing Bypass" 32846 "Server Info" 32850 "RDS Data" 32859 "Ignition Switch State" 32862 "Mono" 32863 "Speed Volume Current Speed" 32865 "Zone Capabilities Extended" ;
VAL_ 2650735616 ID 0 "Alpha Search Threshold" 1 "iPod Subtitles" 2 "Zone 2 Linked" 3 "Zone 2 Enabled" 4 "Zone 3 Enabled" 5 "Zone 4 Enabled" 6 "Telemute" 7 "Tuner Region" 8 "Marine Zone" 9 "USB repeat" 10 "USB shuffle" 11 "iPod Album Artwork" 12 "iPod repeat" 13 "iPod shuffle" 14 "AM Preset 0" 15 "AM Preset 1" 16 "AM Preset 2" 17 "AM Preset 3" 18 "AM Preset 4" 19 "AM Preset 5" 20 "AM Preset 6" 21 "AM Preset 7" 22 "AM Preset 8" 23 "AM Preset 9" 24 "AM Preset 10" 25 "AM Preset 11" 26 "AM Preset 12" 27 "AM Preset 13" 28 "AM Preset 14" 29 "FM Preset 0" 30 "FM Preset 1" 31 "FM Preset 2" 32 "FM Preset 3" 33 "FM Preset 4" 34 "FM Preset 5" 35 "FM Preset 6" 36 "FM Preset 7" 37 "FM Preset 8" 38 "FM Preset 9" 39 "FM Preset 10" 40 "FM Preset 11" 41 "FM Preset 12" 42 "FM Preset 13" 43 "FM Preset 14" 44 "VHF Preset 0" 45 "VHF Preset 1" 46 "VHF Preset 2" 47 "VHF Preset 3" 48 "VHF Preset 4" 49 "VHF Preset 5" 50 "VHF Preset 6" 51 "VHF Preset 7" 52 "VHF Preset 8" 53 "VHF Preset 9" 54 "VHF Preset 10" 55 "VHF Preset 11" 56 "VHF Preset 12" 57 "VHF Preset 13" 58 "VHF Preset 14" 59 "Clock Time" 60 "Clock Alarm" 61 "iPod Video Signal" 62 "iPod Monitor Aspect" 63 "Aux Name Index" 64 "AM Enabled" 65 "VHF Enabled" 66 "Language" 67 "Internal Amps On" 68 "MTP Repeat" 69 "MTP Shuffle" 70 "Id Accessory Source" 71 "NMEA Power" 72 "Low Power Mode" 73 "DVD region" 74 "Volume Zone Sync" 75 "Max Volume Start" 76 "BT Auto Connect" 77 "Null Setting" ;
VAL_ 2650735616 Status 0 "Off" 1 "One/track" 2 "All/album" ;
VAL_ 2650735616 Industry_Code 0 "Global" 1 "Highway" 2 "Agriculture" 3 "Construction" 4 "Marine Industry" 5 "Industrial" ;
VAL_ 2650735616 Message_ID 0 "Unknown" 32769 "API Version" 32770 "Source" 32771 "Source Count" 32772 "Track Info" 32773 "Track Title" 32774 "Track Artist" 32775 "Track Album" 32776 "Cover Art" 32777 "Track Progress" 32778 "Tuner Align" 32779 "Tuner" 32780 "Marine Tuner" 32781 "Marine Squelch" 32782 "Marine Scan Mode" 32783 "Menu Action" 32784 "Menu Count" 32785 "Menu Item" 32786 "Menu Lock ID" 32787 "Aux Gain" 32788 "Setting" 32789 "Settings" 32790 "Update Firmware Result" 32791 "Mute" 32792 "Balance" 32793 "Low Pass Filter" 32794 "Sublevels" 32795 "Tone" 32796 "Volume Limits" 32797 "Volume" 32798 "Capabilities" 32799 "Line Level Control" 32800 "Power" 32801 "Unit Name" 32802 "Sirius" 32803 "SiriusXM Preset Event" 32804 "SiriusXM Channel" 32805 "SiriusXM Title" 32806 "SiriusXM Artist" 32807 "SiriusXM Genre" 32808 "SiriusXM Category" 32809 "SiriusXm Signal" 32810 "SiriusXM Parental Request" 32811 "SiriusXM Diagnostics" 32812 "SiriusXM Presets" 32813 "Zone Name" 32819 "IP Setting" 32824 "Multiroom" 32825 "Multiroom Status" 32829 "System Capabilities" 32830 "Part Number" 32832 "Processing Bypass" 32846 "Server Info" 32850 "RDS Data" 32859 "Ignition Switch State" 32862 "Mono" 32863 "Speed Volume Current Speed" 32865 "Zone Capabilities Extended" ;
VAL_ 2650735616 Industry_Code 0 "Global" 1 "Highway" 2 "Agriculture" 3 "Construction" 4 "Marine Industry" 5 "Industrial" ;
VAL_ 2650735616 Message_ID 0 "Unknown" 32769 "API Version" 32770 "Source" 32771 "Source Count" 32772 "Track Info" 32773 "Track Title" 32774 "Track Artist" 32775 "Track Album" 32776 "Cover Art" 32777 "Track Progress" 32778 "Tuner Align" 32779 "Tuner" 32780 "Marine Tuner" 32781 "Marine Squelch" 32782 "Marine Scan Mode" 32783 "Menu Action" 32784 "Menu Count" 32785 "Menu Item" 32786 "Menu Lock ID" 32787 "Aux Gain" 32788 "Setting" 32789 "Settings" 32790 "Update Firmware Result" 32791 "Mute" 32792 "Balance" 32793 "Low Pass Filter" 32794 "Sublevels" 32795 "Tone" 32796 "Volume Limits" 32797 "Volume" 32798 "Capabilities" 32799 "Line Level Control" 32800 "Power" 32801 "Unit Name" 32802 "Sirius" 32803 "SiriusXM Preset Event" 32804 "SiriusXM Channel" 32805 "SiriusXM Title" 32806 "SiriusXM Artist" 32807 "SiriusXM Genre" 32808 "SiriusXM Category" 32809 "SiriusXm Signal" 32810 "SiriusXM Parental Request" 32811 "SiriusXM Diagnostics" 32812 "SiriusXM Presets" 32813 "Zone Name" 32819 "IP Setting" 32824 "Multiroom" 32825 "Multiroom Status" 32829 "System Capabilities" 32830 "Part Number" 32832 "Processing Bypass" 32846 "Server Info" 32850 "RDS Data" 32859 "Ignition Switch State" 32862 "Mono" 32863 "Speed Volume Current Speed" 32865 "Zone Capabilities Extended" ;
VAL_ 2650735616 Industry_Code 0 "Global" 1 "Highway" 2 "Agriculture" 3 "Construction" 4 "Marine Industry" 5 "Industrial" ;
VAL_ 2650735616 Message_ID 0 "Unknown" 32769 "API Version" 32770 "Source" 32771 "Source Count" 32772 "Track Info" 32773 "Track Title" 32774 "Track Artist" 32775 "Track Album" 32776 "Cover Art" 32777 "Track Progress" 32778 "Tuner Align" 32779 "Tuner" 32780 "Marine Tuner" 32781 "Marine Squelch" 32782 "Marine Scan Mode" 32783 "Menu Action" 32784 "Menu Count" 32785 "Menu Item" 32786 "Menu Lock ID" 32787 "Aux Gain" 32788 "Setting" 32789 "Settings" 32790 "Update Firmware Result" 32791 "Mute" 32792 "Balance" 32793 "Low Pass Filter" 32794 "Sublevels" 32795 "Tone" 32796 "Volume Limits" 32797 "Volume" 32798 "Capabilities" 32799 "Line Level Control" 32800 "Power" 32801 "Unit Name" 32802 "Sirius" 32803 "SiriusXM Preset Event" 32804 "SiriusXM Channel" 32805 "SiriusXM Title" 32806 "SiriusXM Artist" 32807 "SiriusXM Genre" 32808 "SiriusXM Category" 32809 "SiriusXm Signal" 32810 "SiriusXM Parental Request" 32811 "SiriusXM Diagnostics" 32812 "SiriusXM Presets" 32813 "Zone Name" 32819 "IP Setting" 32824 "Multiroom" 32825 "Multiroom Status" 32829 "System Capabilities" 32830 "Part Number" 32832 "Processing Bypass" 32846 "Server Info" 32850 "RDS Data" 32859 "Ignition Switch State" 32862 "Mono" 32863 "Speed Volume Current Speed" 32865 "Zone Capabilities Extended" ;
VAL_ 2650735616 Industry_Code 0 "Global" 1 "Highway" 2 "Agriculture" 3 "Construction" 4 "Marine Industry" 5 "Industrial" ;
VAL_ 2650735616 Message_ID 0 "Unknown" 32769 "API Version" 32770 "Source" 32771 "Source Count" 32772 "Track Info" 32773 "Track Title" 32774 "Track Artist" 32775 "Track Album" 32776 "Cover Art" 32777 "Track Progress" 32778 "Tuner Align" 32779 "Tuner" 32780 "Marine Tuner" 32781 "Marine Squelch" 32782 "Marine Scan Mode" 32783 "Menu Action" 32784 "Menu Count" 32785 "Menu Item" 32786 "Menu Lock ID" 32787 "Aux Gain" 32788 "Setting" 32789 "Settings" 32790 "Update Firmware Result" 32791 "Mute" 32792 "Balance" 32793 "Low Pass Filter" 32794 "Sublevels" 32795 "Tone" 32796 "Volume Limits" 32797 "Volume" 32798 "Capabilities" 32799 "Line Level Control" 32800 "Power" 32801 "Unit Name" 32802 "Sirius" 32803 "SiriusXM Preset Event" 32804 "SiriusXM Channel" 32805 "SiriusXM Title" 32806 "SiriusXM Artist" 32807 "SiriusXM Genre" 32808 "SiriusXM Category" 32809 "SiriusXm Signal" 32810 "SiriusXM Parental Request" 32811 "SiriusXM Diagnostics" 32812 "SiriusXM Presets" 32813 "Zone Name" 32819 "IP Setting" 32824 "Multiroom" 32825 "Multiroom Status" 32829 "System Capabilities" 32830 "Part Number" 32832 "Processing Bypass" 32846 "Server Info" 32850 "RDS Data" 32859 "Ignition Switch State" 32862 "Mono" 32863 "Speed Volume Current Speed" 32865 "Zone Capabilities Extended" ;
VAL_ 2650735616 Industry_Code 0 "Global" 1 "Highway" 2 "Agriculture" 3 "Construction" 4 "Marine Industry" 5 "Industrial" ;
VAL_ 2650735616 Alert_Type 1 "Emergency Alarm" 2 "Alarm" 5 "Warning" 8 "Caution" ;
VAL_ 2650735616 Alert_Category 0 "Navigational" 1 "Technical" ;
VAL_ 2650735616 Response_Command 0 "Acknowledge" 1 "Temporary Silence" 2 "Test Command off" 3 "Test Command on" ;
VAL_ 2650735616 Industry_Code 0 "Global" 1 "Highway" 2 "Agriculture" 3 "Construction" 4 "Marine Industry" 5 "Industrial" ;
VAL_ 2583627008 Manufacturer_Code 69 "ARKS Enterprises" 78 "FW Murphy/Enovation Controls" 80 "Twin Disc" 85 "Kohler Power Systems" 88 "Hemisphere GPS" 135 "Airmar" 137 "Maretron" 140 "Lowrance" 144 "Mercury Marine" 147 "Nautibus Electronic" 148 "Blue Water Data" 154 "Westerbeke" 157 "ISSPRO" 161 "Offshore Systems (UK)" 163 "Evinrude/BRP" 165 "CPAC Systems" 168 "Xantrex Technology" 169 "Marlin Technologies" 172 "Yanmar Marine" 174 "Volvo Penta" 176 "Carling Technologies Inc. (Moritz Aerospace)" 185 "Beede Instruments" 192 "Floscan Instrument" 193 "Nobeltec" 198 "Mystic Valley Communications" 199 "Actia" 201 "Disenos Y Technologia" 211 "Digital Switching Systems" 215 "Xintex/Atena" 224 "EMMI NETWORK" 228 "ZF" 229 "Garmin" 233 "Yacht Monitoring Solutions" 235 "Sailormade Marine Telemetry/Tetra Technology" 243 "Eride" 257 "Honda Motor" 272 "Groco" 273 "Actisense" 274 "Amphenol LTW Technology" 275 "Navico" 283 "Hamilton Jet" 285 "Sea Recovery" 286 "Coelmo SRL Italy" 295 "BEP Marine" 304 "Empir Bus" 305 "NovAtel" 306 "Sleipner Motor" 307 "MBW Technologies" 315 "ICOM" 328 "Qwerty" 329 "Dief" 341 "Boening Automationstechnologie" 345 "Korean Maritime University" 351 "Thrane and Thrane" 355 "Mastervolt" 356 "Fischer Panda Generators" 358 "Victron Energy" 370 "Rolls Royce Marine" 373 "Electronic Design" 374 "Northern Lights" 378 "Glendinning" 381 "B & G" 384 "Rose Point Navigation Systems" 385 "Johnson Outdoors Marine Electronics Inc Geonav" 394 "Capi 2" 396 "Beyond Measure" 400 "Livorsi Marine" 404 "ComNav" 409 "Chetco" 419 "Fusion Electronics" 421 "Standard Horizon" 422 "True Heading" 426 "Egersund Marine Electronics" 427 "em-trak Marine Electronics" 431 "Tohatsu Co, JP" 437 "Digital Yacht" 438 "Comar Systems Limited" 440 "Cummins" 443 "VDO (aka Continental-Corporation)" 451 "Parker Hannifin aka Village Marine Tech" 459 "Alltek Marine Electronics" 460 "SAN GIORGIO S.E.I.N" 466 "Veethree Electronics & Marine" 470 "SI-TEX Marine Electronics" 471 "Sea Cross Marine" 475 "GME aka Standard Communications" 476 "Humminbird Marine Electronics" 478 "Ocean Sat" 481 "Chetco Digital Instruments" 493 "Watcheye" 499 "Lcj Capteurs" 502 "Attwood Marine" 503 "Naviop S.R.L." 504 "Vesper Marine" 510 "Marinesoft" 513 "Simarine" 517 "NoLand Engineering" 518 "Transas USA" 529 "National Instruments Korea" 530 "National Marine Electronics Association" 532 "Onwa Marine" 540 "Webasto" 571 "Marinecraft (South Korea)" 573 "McMurdo Group aka Orolia" 578 "Advansea" 579 "KVH" 580 "San Jose Technology" 583 "Yacht Control" 586 "Suzuki Motor" 591 "US Coast Guard" 595 "Ship Module aka Customware" 600 "Aquatic AV" 605 "Aventics" 606 "Intellian" 612 "SamwonIT" 614 "Arlt Tecnologies" 637 "Bavaria Yachts" 641 "Diverse Yacht Services" 644 "Wema U.S.A dba KUS" 658 "Shenzhen Jiuzhou Himunication" 688 "Rockford" 699 "Harman International" 704 "JL Audio" 708 "Lars Thrane" 715 "Autonnic" 717 "Yacht Devices" 734 "REAP Systems" 735 "AEM Performance Electronics" 739 "LxNav" 741 "Littelfuse, Inc (formerly Carling Technologies)" 743 "DaeMyung" 744 "Woosung" 748 "ISOTTA IFRA srl" 773 "Clarion US" 776 "HMI Systems" 777 "Ocean Signal" 778 "Seakeeper" 781 "Poly Planar" 785 "Fischer Panda DE" 795 "Broyda Industries" 796 "Canadian Automotive" 797 "Tides Marine" 798 "Lumishore" 799 "Still Water Designs and Audio" 802 "BJ Technologies (Beneteau)" 803 "Gill Sensors" 811 "Blue Water Desalination" 815 "FLIR" 824 "Undheim Systems" 826 "Lewmar" 838 "TeamSurv" 844 "Fell Marine" 847 "Oceanvolt" 862 "Prospec" 868 "Data Panel" 890 "L3 Technologies" 894 "Rhodan Marine Systems" 896 "Nexfour Solutions" 905 "ASA Electronics" 909 "Marines Co (South Korea)" 911 "Nautic-on" 917 "Sentinel" 929 "JL Marine Systems" 930 "Ecotronix" 944 "Zontisa Marine" 951 "EXOR International" 962 "Timbolier Industries" 963 "TJC Micro" 968 "Cox Powertrain" 969 "Blue Seas" 981 "Kobelt Manufacturing" 992 "Blue Ocean IOT" 997 "Xenta Systems" 999 "Signal K" 1004 "Ultraflex" 1008 "Lintest SmartBoat" 1011 "Soundmax" 1020 "Team Italia Marine (Onyx Marine Automation s.r.l)" 1021 "Entratech" 1022 "ITC" 1029 "The Marine Guardian" 1047 "Sonic" 1051 "ProNav" 1053 "Vetus Maxwell INC." 1056 "Lithium Pros" 1059 "Boatrax" 1062 "Marol Co ltd" 1065 "CALYPSO Instruments" 1066 "Spot Zero Water" 1069 "Lithionics Battery" 1070 "Quick-teck Electronics" 1075 "Uniden America" 1083 "Nauticoncept" 1084 "Shadow-Caster LED lighting" 1085 "Wet Sounds" 1088 "E-T-A Circuit Breakers" 1092 "Scheiber" 1100 "Smart Yachts International Limited" 1109 "Dockmate" 1114 "Bobs Machine" 1118 "L3Harris ASV" 1119 "Balmar" 1120 "Elettromedia" 1127 "Electromaax" 1140 "Across Oceans Systems" 1145 "Kiwi Yachting" 1150 "BSB Artificial Intelligence" 1151 "Orca Technologies" 1154 "TBS Electronics" 1158 "Technoton Electroics" 1160 "MG Energy Systems" 1169 "Sea Machine Robotics" 1171 "Vista Manufacturing" 1183 "Zipwake" 1186 "Sailmon" 1192 "Airmoniq Pro Kft" 1194 "Sierra Marine" 1200 "Xinuo Information Technology (Xiamen)" 1218 "Septentrio" 1233 "NKE Marine Electronics" 1238 "SuperTrack Aps" 1239 "Honda Electronics" 1245 "Raritan Engineering" 1249 "Integrated Power Solutions AG" 1260 "Interactive Technologies" 1283 "LTG-Tech" 1299 "Energy Solutions (UK)" 1300 "WATT Fuel Cell" 1302 "Pro Mainer" 1305 "Dragonfly Energy" 1306 "Koden Electronics" 1311 "Humphree" 1316 "Hinkley Yachts" 1317 "Global Marine Management GmbH (GMM)" 1320 "Triskel Marine" 1330 "Warwick Control Technologies" 1331 "Dolphin Charger" 1337 "Barnacle Systems" 1348 "Radian IoT" 1353 "Ocean LED Marine" 1359 "BluNav" 1361 "OVA (Nantong Saiyang Electronics Co., Ltd)" 1368 "RAD Propulsion" 1369 "Electric Yacht" 1372 "Elco Motor Yachts" 1384 "Tecnoseal Foundry S.r.l" 1385 "Pro Charging Systems" 1389 "EVEX" 1398 "Gobius Sensor Technology" 1403 "Arco Marine" 1408 "Lenco Marine" 1413 "Naocontrol" 1417 "Revatek" 1438 "Aeolionics" 1439 "PredictWind" 1440 "Egis Mobile Electric" 1445 "Starboard Yacht Group" 1446 "Roswell Marine" 1451 "ePropulsion (Guangdong ePropulsion Technology Ltd.)" 1452 "Micro-Air" 1453 "Vital Battery" 1458 "Ride Controller" 1460 "Tocaro Blue" 1461 "Vanquish Yachts" 1471 "FT Technologies" 1478 "Alps Alpine" 1481 "E-Force Marine" 1482 "CMC Marine" 1483 "Nanjing Sandemarine Information Technology" 1850 "Teleflex Marine (SeaStar Solutions)" 1851 "Raymarine" 1852 "Navionics" 1853 "Japan Radio" 1854 "Northstar Technologies" 1855 "Furuno" 1856 "Trimble" 1857 "Simrad" 1858 "Litton" 1859 "Kvasar" 1860 "MMP" 1861 "Vector Cantech" 1862 "Yamaha Marine" 1863 "Faria Instruments" ;
VAL_ 2583627008 Industry_Code 0 "Global" 1 "Highway" 2 "Agriculture" 3 "Construction" 4 "Marine Industry" 5 "Industrial" ;
VAL_ 2650735872 Manufacturer_Code 69 "ARKS Enterprises" 78 "FW Murphy/Enovation Controls" 80 "Twin Disc" 85 "Kohler Power Systems" 88 "Hemisphere GPS" 135 "Airmar" 137 "Maretron" 140 "Lowrance" 144 "Mercury Marine" 147 "Nautibus Electronic" 148 "Blue Water Data" 154 "Westerbeke" 157 "ISSPRO" 161 "Offshore Systems (UK)" 163 "Evinrude/BRP" 165 "CPAC Systems" 168 "Xantrex Technology" 169 "Marlin Technologies" 172 "Yanmar Marine" 174 "Volvo Penta" 176 "Carling Technologies Inc. (Moritz Aerospace)" 185 "Beede Instruments" 192 "Floscan Instrument" 193 "Nobeltec" 198 "Mystic Valley Communications" 199 "Actia" 201 "Disenos Y Technologia" 211 "Digital Switching Systems" 215 "Xintex/Atena" 224 "EMMI NETWORK" 228 "ZF" 229 "Garmin" 233 "Yacht Monitoring Solutions" 235 "Sailormade Marine Telemetry/Tetra Technology" 243 "Eride" 257 "Honda Motor" 272 "Groco" 273 "Actisense" 274 "Amphenol LTW Technology" 275 "Navico" 283 "Hamilton Jet" 285 "Sea Recovery" 286 "Coelmo SRL Italy" 295 "BEP Marine" 304 "Empir Bus" 305 "NovAtel" 306 "Sleipner Motor" 307 "MBW Technologies" 315 "ICOM" 328 "Qwerty" 329 "Dief" 341 "Boening Automationstechnologie" 345 "Korean Maritime University" 351 "Thrane and Thrane" 355 "Mastervolt" 356 "Fischer Panda Generators" 358 "Victron Energy" 370 "Rolls Royce Marine" 373 "Electronic Design" 374 "Northern Lights" 378 "Glendinning" 381 "B & G" 384 "Rose Point Navigation Systems" 385 "Johnson Outdoors Marine Electronics Inc Geonav" 394 "Capi 2" 396 "Beyond Measure" 400 "Livorsi Marine" 404 "ComNav" 409 "Chetco" 419 "Fusion Electronics" 421 "Standard Horizon" 422 "True Heading" 426 "Egersund Marine Electronics" 427 "em-trak Marine Electronics" 431 "Tohatsu Co, JP" 437 "Digital Yacht" 438 "Comar Systems Limited" 440 "Cummins" 443 "VDO (aka Continental-Corporation)" 451 "Parker Hannifin aka Village Marine Tech" 459 "Alltek Marine Electronics" 460 "SAN GIORGIO S.E.I.N" 466 "Veethree Electronics & Marine" 470 "SI-TEX Marine Electronics" 471 "Sea Cross Marine" 475 "GME aka Standard Communications" 476 "Humminbird Marine Electronics" 478 "Ocean Sat" 481 "Chetco Digital Instruments" 493 "Watcheye" 499 "Lcj Capteurs" 502 "Attwood Marine" 503 "Naviop S.R.L." 504 "Vesper Marine" 510 "Marinesoft" 513 "Simarine" 517 "NoLand Engineering" 518 "Transas USA" 529 "National Instruments Korea" 530 "National Marine Electronics Association" 532 "Onwa Marine" 540 "Webasto" 571 "Marinecraft (South Korea)" 573 "McMurdo Group aka Orolia" 578 "Advansea" 579 "KVH" 580 "San Jose Technology" 583 "Yacht Control" 586 "Suzuki Motor" 591 "US Coast Guard" 595 "Ship Module aka Customware" 600 "Aquatic AV" 605 "Aventics" 606 "Intellian" 612 "SamwonIT" 614 "Arlt Tecnologies" 637 "Bavaria Yachts" 641 "Diverse Yacht Services" 644 "Wema U.S.A dba KUS" 658 "Shenzhen Jiuzhou Himunication" 688 "Rockford" 699 "Harman International" 704 "JL Audio" 708 "Lars Thrane" 715 "Autonnic" 717 "Yacht Devices" 734 "REAP Systems" 735 "AEM Performance Electronics" 739 "LxNav" 741 "Littelfuse, Inc (formerly Carling Technologies)" 743 "DaeMyung" 744 "Woosung" 748 "ISOTTA IFRA srl" 773 "Clarion US" 776 "HMI Systems" 777 "Ocean Signal" 778 "Seakeeper" 781 "Poly Planar" 785 "Fischer Panda DE" 795 "Broyda Industries" 796 "Canadian Automotive" 797 "Tides Marine" 798 "Lumishore" 799 "Still Water Designs and Audio" 802 "BJ Technologies (Beneteau)" 803 "Gill Sensors" 811 "Blue Water Desalination" 815 "FLIR" 824 "Undheim Systems" 826 "Lewmar" 838 "TeamSurv" 844 "Fell Marine" 847 "Oceanvolt" 862 "Prospec" 868 "Data Panel" 890 "L3 Technologies" 894 "Rhodan Marine Systems" 896 "Nexfour Solutions" 905 "ASA Electronics" 909 "Marines Co (South Korea)" 911 "Nautic-on" 917 "Sentinel" 929 "JL Marine Systems" 930 "Ecotronix" 944 "Zontisa Marine" 951 "EXOR International" 962 "Timbolier Industries" 963 "TJC Micro" 968 "Cox Powertrain" 969 "Blue Seas" 981 "Kobelt Manufacturing" 992 "Blue Ocean IOT" 997 "Xenta Systems" 999 "Signal K" 1004 "Ultraflex" 1008 "Lintest SmartBoat" 1011 "Soundmax" 1020 "Team Italia Marine (Onyx Marine Automation s.r.l)" 1021 "Entratech" 1022 "ITC" 1029 "The Marine Guardian" 1047 "Sonic" 1051 "ProNav" 1053 "Vetus Maxwell INC." 1056 "Lithium Pros" 1059 "Boatrax" 1062 "Marol Co ltd" 1065 "CALYPSO Instruments" 1066 "Spot Zero Water" 1069 "Lithionics Battery" 1070 "Quick-teck Electronics" 1075 "Uniden America" 1083 "Nauticoncept" 1084 "Shadow-Caster LED lighting" 1085 "Wet Sounds" 1088 "E-T-A Circuit Breakers" 1092 "Scheiber" 1100 "Smart Yachts International Limited" 1109 "Dockmate" 1114 "Bobs Machine" 1118 "L3Harris ASV" 1119 "Balmar" 1120 "Elettromedia" 1127 "Electromaax" 1140 "Across Oceans Systems" 1145 "Kiwi Yachting" 1150 "BSB Artificial Intelligence" 1151 "Orca Technologies" 1154 "TBS Electronics" 1158 "Technoton Electroics" 1160 "MG Energy Systems" 1169 "Sea Machine Robotics" 1171 "Vista Manufacturing" 1183 "Zipwake" 1186 "Sailmon" 1192 "Airmoniq Pro Kft" 1194 "Sierra Marine" 1200 "Xinuo Information Technology (Xiamen)" 1218 "Septentrio" 1233 "NKE Marine Electronics" 1238 "SuperTrack Aps" 1239 "Honda Electronics" 1245 "Raritan Engineering" 1249 "Integrated Power Solutions AG" 1260 "Interactive Technologies" 1283 "LTG-Tech" 1299 "Energy Solutions (UK)" 1300 "WATT Fuel Cell" 1302 "Pro Mainer" 1305 "Dragonfly Energy" 1306 "Koden Electronics" 1311 "Humphree" 1316 "Hinkley Yachts" 1317 "Global Marine Management GmbH (GMM)" 1320 "Triskel Marine" 1330 "Warwick Control Technologies" 1331 "Dolphin Charger" 1337 "Barnacle Systems" 1348 "Radian IoT" 1353 "Ocean LED Marine" 1359 "BluNav" 1361 "OVA (Nantong Saiyang Electronics Co., Ltd)" 1368 "RAD Propulsion" 1369 "Electric Yacht" 1372 "Elco Motor Yachts" 1384 "Tecnoseal Foundry S.r.l" 1385 "Pro Charging Systems" 1389 "EVEX" 1398 "Gobius Sensor Technology" 1403 "Arco Marine" 1408 "Lenco Marine" 1413 "Naocontrol" 1417 "Revatek" 1438 "Aeolionics" 1439 "PredictWind" 1440 "Egis Mobile Electric" 1445 "Starboard Yacht Group" 1446 "Roswell Marine" 1451 "ePropulsion (Guangdong ePropulsion Technology Ltd.)" 1452 "Micro-Air" 1453 "Vital Battery" 1458 "Ride Controller" 1460 "Tocaro Blue" 1461 "Vanquish Yachts" 1471 "FT Technologies" 1478 "Alps Alpine" 1481 "E-Force Marine" 1482 "CMC Marine" 1483 "Nanjing Sandemarine Information Technology" 1850 "Teleflex Marine (SeaStar Solutions)" 1851 "Raymarine" 1852 "Navionics" 1853 "Japan Radio" 1854 "Northstar Technologies" 1855 "Furuno" 1856 "Trimble" 1857 "Simrad" 1858 "Litton" 1859 "Kvasar" 1860 "MMP" 1861 "Vector Cantech" 1862 "Yamaha Marine" 1863 "Faria Instruments" ;
VAL_ 2650735872 Industry_Code 0 "Global" 1 "Highway" 2 "Agriculture" 3 "Construction" 4 "Marine Industry" 5 "Industrial" ;
VAL_ 2650735872 Manufacturer_Code 69 "ARKS Enterprises" 78 "FW Murphy/Enovation Controls" 80 "Twin Disc" 85 "Kohler Power Systems" 88 "Hemisphere GPS" 135 "Airmar" 137 "Maretron" 140 "Lowrance" 144 "Mercury Marine" 147 "Nautibus Electronic" 148 "Blue Water Data" 154 "Westerbeke" 157 "ISSPRO" 161 "Offshore Systems (UK)" 163 "Evinrude/BRP" 165 "CPAC Systems" 168 "Xantrex Technology" 169 "Marlin Technologies" 172 "Yanmar Marine" 174 "Volvo Penta" 176 "Carling Technologies Inc. (Moritz Aerospace)" 185 "Beede Instruments" 192 "Floscan Instrument" 193 "Nobeltec" 198 "Mystic Valley Communications" 199 "Actia" 201 "Disenos Y Technologia" 211 "Digital Switching Systems" 215 "Xintex/Atena" 224 "EMMI NETWORK" 228 "ZF" 229 "Garmin" 233 "Yacht Monitoring Solutions" 235 "Sailormade Marine Telemetry/Tetra Technology" 243 "Eride" 257 "Honda Motor" 272 "Groco" 273 "Actisense" 274 "Amphenol LTW Technology" 275 "Navico" 283 "Hamilton Jet" 285 "Sea Recovery" 286 "Coelmo SRL Italy" 295 "BEP Marine" 304 "Empir Bus" 305 "NovAtel" 306 "Sleipner Motor" 307 "MBW Technologies" 315 "ICOM" 328 "Qwerty" 329 "Dief" 341 "Boening Automationstechnologie" 345 "Korean Maritime University" 351 "Thrane and Thrane" 355 "Mastervolt" 356 "Fischer Panda Generators" 358 "Victron Energy" 370 "Rolls Royce Marine" 373 "Electronic Design" 374 "Northern Lights" 378 "Glendinning" 381 "B & G" 384 "Rose Point Navigation Systems" 385 "Johnson Outdoors Marine Electronics Inc Geonav" 394 "Capi 2" 396 "Beyond Measure" 400 "Livorsi Marine" 404 "ComNav" 409 "Chetco" 419 "Fusion Electronics" 421 "Standard Horizon" 422 "True Heading" 426 "Egersund Marine Electronics" 427 "em-trak Marine Electronics" 431 "Tohatsu Co, JP" 437 "Digital Yacht" 438 "Comar Systems Limited" 440 "Cummins" 443 "VDO (aka Continental-Corporation)" 451 "Parker Hannifin aka Village Marine Tech" 459 "Alltek Marine Electronics" 460 "SAN GIORGIO S.E.I.N" 466 "Veethree Electronics & Marine" 470 "SI-TEX Marine Electronics" 471 "Sea Cross Marine" 475 "GME aka Standard Communications" 476 "Humminbird Marine Electronics" 478 "Ocean Sat" 481 "Chetco Digital Instruments" 493 "Watcheye" 499 "Lcj Capteurs" 502 "Attwood Marine" 503 "Naviop S.R.L." 504 "Vesper Marine" 510 "Marinesoft" 513 "Simarine" 517 "NoLand Engineering" 518 "Transas USA" 529 "National Instruments Korea" 530 "National Marine Electronics Association" 532 "Onwa Marine" 540 "Webasto" 571 "Marinecraft (South Korea)" 573 "McMurdo Group aka Orolia" 578 "Advansea" 579 "KVH" 580 "San Jose Technology" 583 "Yacht Control" 586 "Suzuki Motor" 591 "US Coast Guard" 595 "Ship Module aka Customware" 600 "Aquatic AV" 605 "Aventics" 606 "Intellian" 612 "SamwonIT" 614 "Arlt Tecnologies" 637 "Bavaria Yachts" 641 "Diverse Yacht Services" 644 "Wema U.S.A dba KUS" 658 "Shenzhen Jiuzhou Himunication" 688 "Rockford" 699 "Harman International" 704 "JL Audio" 708 "Lars Thrane" 715 "Autonnic" 717 "Yacht Devices" 734 "REAP Systems" 735 "AEM Performance Electronics" 739 "LxNav" 741 "Littelfuse, Inc (formerly Carling Technologies)" 743 "DaeMyung" 744 "Woosung" 748 "ISOTTA IFRA srl" 773 "Clarion US" 776 "HMI Systems" 777 "Ocean Signal" 778 "Seakeeper" 781 "Poly Planar" 785 "Fischer Panda DE" 795 "Broyda Industries" 796 "Canadian Automotive" 797 "Tides Marine" 798 "Lumishore" 799 "Still Water Designs and Audio" 802 "BJ Technologies (Beneteau)" 803 "Gill Sensors" 811 "Blue Water Desalination" 815 "FLIR" 824 "Undheim Systems" 826 "Lewmar" 838 "TeamSurv" 844 "Fell Marine" 847 "Oceanvolt" 862 "Prospec" 868 "Data Panel" 890 "L3 Technologies" 894 "Rhodan Marine Systems" 896 "Nexfour Solutions" 905 "ASA Electronics" 909 "Marines Co (South Korea)" 911 "Nautic-on" 917 "Sentinel" 929 "JL Marine Systems" 930 "Ecotronix" 944 "Zontisa Marine" 951 "EXOR International" 962 "Timbolier Industries" 963 "TJC Micro" 968 "Cox Powertrain" 969 "Blue Seas" 981 "Kobelt Manufacturing" 992 "Blue Ocean IOT" 997 "Xenta Systems" 999 "Signal K" 1004 "Ultraflex" 1008 "Lintest SmartBoat" 1011 "Soundmax" 1020 "Team Italia Marine (Onyx Marine Automation s.r.l)" 1021 "Entratech" 1022 "ITC" 1029 "The Marine Guardian" 1047 "Sonic" 1051 "ProNav" 1053 "Vetus Maxwell INC." 1056 "Lithium Pros" 1059 "Boatrax" 1062 "Marol Co ltd" 1065 "CALYPSO Instruments" 1066 "Spot Zero Water" 1069 "Lithionics Battery" 1070 "Quick-teck Electronics" 1075 "Uniden America" 1083 "Nauticoncept" 1084 "Shadow-Caster LED lighting" 1085 "Wet Sounds" 1088 "E-T-A Circuit Breakers" 1092 "Scheiber" 1100 "Smart Yachts International Limited" 1109 "Dockmate" 1114 "Bobs Machine" 1118 "L3Harris ASV" 1119 "Balmar" 1120 "Elettromedia" 1127 "Electromaax" 1140 "Across Oceans Systems" 1145 "Kiwi Yachting" 1150 "BSB Artificial Intelligence" 1151 "Orca Technologies" 1154 "TBS Electronics" 1158 "Technoton Electroics" 1160 "MG Energy Systems" 1169 "Sea Machine Robotics" 1171 "Vista Manufacturing" 1183 "Zipwake" 1186 "Sailmon" 1192 "Airmoniq Pro Kft" 1194 "Sierra Marine" 1200 "Xinuo Information Technology (Xiamen)" 1218 "Septentrio" 1233 "NKE Marine Electronics" 1238 "SuperTrack Aps" 1239 "Honda Electronics" 1245 "Raritan Engineering" 1249 "Integrated Power Solutions AG" 1260 "Interactive Technologies" 1283 "LTG-Tech" 1299 "Energy Solutions (UK)" 1300 "WATT Fuel Cell" 1302 "Pro Mainer" 1305 "Dragonfly Energy" 1306 "Koden Electronics" 1311 "Humphree" 1316 "Hinkley Yachts" 1317 "Global Marine Management GmbH (GMM)" 1320 "Triskel Marine" 1330 "Warwick Control Technologies" 1331 "Dolphin Charger" 1337 "Barnacle Systems" 1348 "Radian IoT" 1353 "Ocean LED Marine" 1359 "BluNav" 1361 "OVA (Nantong Saiyang Electronics Co., Ltd)" 1368 "RAD Propulsion" 1369 "Electric Yacht" 1372 "Elco Motor Yachts" 1384 "Tecnoseal Foundry S.r.l" 1385 "Pro Charging Systems" 1389 "EVEX" 1398 "Gobius Sensor Technology" 1403 "Arco Marine" 1408 "Lenco Marine" 1413 "Naocontrol" 1417 "Revatek" 1438 "Aeolionics" 1439 "PredictWind" 1440 "Egis Mobile Electric" 1445 "Starboard Yacht Group" 1446 "Roswell Marine" 1451 "ePropulsion (Guangdong ePropulsion Technology Ltd.)" 1452 "Micro-Air" 1453 "Vital Battery" 1458 "Ride Controller" 1460 "Tocaro Blue" 1461 "Vanquish Yachts" 1471 "FT Technologies" 1478 "Alps Alpine" 1481 "E-Force Marine" 1482 "CMC Marine" 1483 "Nanjing Sandemarine Information Technology" 1850 "Teleflex Marine (SeaStar Solutions)" 1851 "Raymarine" 1852 "Navionics" 1853 "Japan Radio" 1854 "Northstar Technologies" 1855 "Furuno" 1856 "Trimble" 1857 "Simrad" 1858 "Litton" 1859 "Kvasar" 1860 "MMP" 1861 "Vector Cantech" 1862 "Yamaha Marine" 1863 "Faria Instruments" ;
VAL_ 2650735872 Industry_Code 0 "Global" 1 "Highway" 2 "Agriculture" 3 "Construction" 4 "Marine Industry" 5 "Industrial" ;
VAL_ 2650735872 Alert_Type 1 "Emergency Alarm" 2 "Alarm" 5 "Warning" 8 "Caution" ;
VAL_ 2650735872 Alert_Category 0 "Navigational" 1 "Technical" ;
VAL_ 2650735872 Language_ID 0 "English (US)" 1 "English (UK)" 2 "Arabic" 3 "Chinese (simplified)" 4 "Croatian" 5 "Danish" 6 "Dutch" 7 "Finnish" 8 "French" 9 "German" 10 "Greek" 11 "Italian" 12 "Japanese" 13 "Korean" 14 "Norwegian" 15 "Polish" 16 "Portuguese" 17 "Russian" 18 "Spanish" 19 "Swedish" ;
VAL_ 2650735872 Manufacturer_Code 69 "ARKS Enterprises" 78 "FW Murphy/Enovation Controls" 80 "Twin Disc" 85 "Kohler Power Systems" 88 "Hemisphere GPS" 135 "Airmar" 137 "Maretron" 140 "Lowrance" 144 "Mercury Marine" 147 "Nautibus Electronic" 148 "Blue Water Data" 154 "Westerbeke" 157 "ISSPRO" 161 "Offshore Systems (UK)" 163 "Evinrude/BRP" 165 "CPAC Systems" 168 "Xantrex Technology" 169 "Marlin Technologies" 172 "Yanmar Marine" 174 "Volvo Penta" 176 "Carling Technologies Inc. (Moritz Aerospace)" 185 "Beede Instruments" 192 "Floscan Instrument" 193 "Nobeltec" 198 "Mystic Valley Communications" 199 "Actia" 201 "Disenos Y Technologia" 211 "Digital Switching Systems" 215 "Xintex/Atena" 224 "EMMI NETWORK" 228 "ZF" 229 "Garmin" 233 "Yacht Monitoring Solutions" 235 "Sailormade Marine Telemetry/Tetra Technology" 243 "Eride" 257 "Honda Motor" 272 "Groco" 273 "Actisense" 274 "Amphenol LTW Technology" 275 "Navico" 283 "Hamilton Jet" 285 "Sea Recovery" 286 "Coelmo SRL Italy" 295 "BEP Marine" 304 "Empir Bus" 305 "NovAtel" 306 "Sleipner Motor" 307 "MBW Technologies" 315 "ICOM" 328 "Qwerty" 329 "Dief" 341 "Boening Automationstechnologie" 345 "Korean Maritime University" 351 "Thrane and Thrane" 355 "Mastervolt" 356 "Fischer Panda Generators" 358 "Victron Energy" 370 "Rolls Royce Marine" 373 "Electronic Design" 374 "Northern Lights" 378 "Glendinning" 381 "B & G" 384 "Rose Point Navigation Systems" 385 "Johnson Outdoors Marine Electronics Inc Geonav" 394 "Capi 2" 396 "Beyond Measure" 400 "Livorsi Marine" 404 "ComNav" 409 "Chetco" 419 "Fusion Electronics" 421 "Standard Horizon" 422 "True Heading" 426 "Egersund Marine Electronics" 427 "em-trak Marine Electronics" 431 "Tohatsu Co, JP" 437 "Digital Yacht" 438 "Comar Systems Limited" 440 "Cummins" 443 "VDO (aka Continental-Corporation)" 451 "Parker Hannifin aka Village Marine Tech" 459 "Alltek Marine Electronics" 460 "SAN GIORGIO S.E.I.N" 466 "Veethree Electronics & Marine" 470 "SI-TEX Marine Electronics" 471 "Sea Cross Marine" 475 "GME aka Standard Communications" 476 "Humminbird Marine Electronics" 478 "Ocean Sat" 481 "Chetco Digital Instruments" 493 "Watcheye" 499 "Lcj Capteurs" 502 "Attwood Marine" 503 "Naviop S.R.L." 504 "Vesper Marine" 510 "Marinesoft" 513 "Simarine" 517 "NoLand Engineering" 518 "Transas USA" 529 "National Instruments Korea" 530 "National Marine Electronics Association" 532 "Onwa Marine" 540 "Webasto" 571 "Marinecraft (South Korea)" 573 "McMurdo Group aka Orolia" 578 "Advansea" 579 "KVH" 580 "San Jose Technology" 583 "Yacht Control" 586 "Suzuki Motor" 591 "US Coast Guard" 595 "Ship Module aka Customware" 600 "Aquatic AV" 605 "Aventics" 606 "Intellian" 612 "SamwonIT" 614 "Arlt Tecnologies" 637 "Bavaria Yachts" 641 "Diverse Yacht Services" 644 "Wema U.S.A dba KUS" 658 "Shenzhen Jiuzhou Himunication" 688 "Rockford" 699 "Harman International" 704 "JL Audio" 708 "Lars Thrane" 715 "Autonnic" 717 "Yacht Devices" 734 "REAP Systems" 735 "AEM Performance Electronics" 739 "LxNav" 741 "Littelfuse, Inc (formerly Carling Technologies)" 743 "DaeMyung" 744 "Woosung" 748 "ISOTTA IFRA srl" 773 "Clarion US" 776 "HMI Systems" 777 "Ocean Signal" 778 "Seakeeper" 781 "Poly Planar" 785 "Fischer Panda DE" 795 "Broyda Industries" 796 "Canadian Automotive" 797 "Tides Marine" 798 "Lumishore" 799 "Still Water Designs and Audio" 802 "BJ Technologies (Beneteau)" 803 "Gill Sensors" 811 "Blue Water Desalination" 815 "FLIR" 824 "Undheim Systems" 826 "Lewmar" 838 "TeamSurv" 844 "Fell Marine" 847 "Oceanvolt" 862 "Prospec" 868 "Data Panel" 890 "L3 Technologies" 894 "Rhodan Marine Systems" 896 "Nexfour Solutions" 905 "ASA Electronics" 909 "Marines Co (South Korea)" 911 "Nautic-on" 917 "Sentinel" 929 "JL Marine Systems" 930 "Ecotronix" 944 "Zontisa Marine" 951 "EXOR International" 962 "Timbolier Industries" 963 "TJC Micro" 968 "Cox Powertrain" 969 "Blue Seas" 981 "Kobelt Manufacturing" 992 "Blue Ocean IOT" 997 "Xenta Systems" 999 "Signal K" 1004 "Ultraflex" 1008 "Lintest SmartBoat" 1011 "Soundmax" 1020 "Team Italia Marine (Onyx Marine Automation s.r.l)" 1021 "Entratech" 1022 "ITC" 1029 "The Marine Guardian" 1047 "Sonic" 1051 "ProNav" 1053 "Vetus Maxwell INC." 1056 "Lithium Pros" 1059 "Boatrax" 1062 "Marol Co ltd" 1065 "CALYPSO Instruments" 1066 "Spot Zero Water" 1069 "Lithionics Battery" 1070 "Quick-teck Electronics" 1075 "Uniden America" 1083 "Nauticoncept" 1084 "Shadow-Caster LED lighting" 1085 "Wet Sounds" 1088 "E-T-A Circuit Breakers" 1092 "Scheiber" 1100 "Smart Yachts International Limited" 1109 "Dockmate" 1114 "Bobs Machine" 1118 "L3Harris ASV" 1119 "Balmar" 1120 "Elettromedia" 1127 "Electromaax" 1140 "Across Oceans Systems" 1145 "Kiwi Yachting" 1150 "BSB Artificial Intelligence" 1151 "Orca Technologies" 1154 "TBS Electronics" 1158 "Technoton Electroics" 1160 "MG Energy Systems" 1169 "Sea Machine Robotics" 1171 "Vista Manufacturing" 1183 "Zipwake" 1186 "Sailmon" 1192 "Airmoniq Pro Kft" 1194 "Sierra Marine" 1200 "Xinuo Information Technology (Xiamen)" 1218 "Septentrio" 1233 "NKE Marine Electronics" 1238 "SuperTrack Aps" 1239 "Honda Electronics" 1245 "Raritan Engineering" 1249 "Integrated Power Solutions AG" 1260 "Interactive Technologies" 1283 "LTG-Tech" 1299 "Energy Solutions (UK)" 1300 "WATT Fuel Cell" 1302 "Pro Mainer" 1305 "Dragonfly Energy" 1306 "Koden Electronics" 1311 "Humphree" 1316 "Hinkley Yachts" 1317 "Global Marine Management GmbH (GMM)" 1320 "Triskel Marine" 1330 "Warwick Control Technologies" 1331 "Dolphin Charger" 1337 "Barnacle Systems" 1348 "Radian IoT" 1353 "Ocean LED Marine" 1359 "BluNav" 1361 "OVA (Nantong Saiyang Electronics Co., Ltd)" 1368 "RAD Propulsion" 1369 "Electric Yacht" 1372 "Elco Motor Yachts" 1384 "Tecnoseal Foundry S.r.l" 1385 "Pro Charging Systems" 1389 "EVEX" 1398 "Gobius Sensor Technology" 1403 "Arco Marine" 1408 "Lenco Marine" 1413 "Naocontrol" 1417 "Revatek" 1438 "Aeolionics" 1439 "PredictWind" 1440 "Egis Mobile Electric" 1445 "Starboard Yacht Group" 1446 "Roswell Marine" 1451 "ePropulsion (Guangdong ePropulsion Technology Ltd.)" 1452 "Micro-Air" 1453 "Vital Battery" 1458 "Ride Controller" 1460 "Tocaro Blue" 1461 "Vanquish Yachts" 1471 "FT Technologies" 1478 "Alps Alpine" 1481 "E-Force Marine" 1482 "CMC Marine" 1483 "Nanjing Sandemarine Information Technology" 1850 "Teleflex Marine (SeaStar Solutions)" 1851 "Raymarine" 1852 "Navionics" 1853 "Japan Radio" 1854 "Northstar Technologies" 1855 "Furuno" 1856 "Trimble" 1857 "Simrad" 1858 "Litton" 1859 "Kvasar" 1860 "MMP" 1861 "Vector Cantech" 1862 "Yamaha Marine" 1863 "Faria Instruments" ;
VAL_ 2650735872 Industry_Code 0 "Global" 1 "Highway" 2 "Agriculture" 3 "Construction" 4 "Marine Industry" 5 "Industrial" ;
VAL_ 2583627264 Manufacturer_Code 69 "ARKS Enterprises" 78 "FW Murphy/Enovation Controls" 80 "Twin Disc" 85 "Kohler Power Systems" 88 "Hemisphere GPS" 135 "Airmar" 137 "Maretron" 140 "Lowrance" 144 "Mercury Marine" 147 "Nautibus Electronic" 148 "Blue Water Data" 154 "Westerbeke" 157 "ISSPRO" 161 "Offshore Systems (UK)" 163 "Evinrude/BRP" 165 "CPAC Systems" 168 "Xantrex Technology" 169 "Marlin Technologies" 172 "Yanmar Marine" 174 "Volvo Penta" 176 "Carling Technologies Inc. (Moritz Aerospace)" 185 "Beede Instruments" 192 "Floscan Instrument" 193 "Nobeltec" 198 "Mystic Valley Communications" 199 "Actia" 201 "Disenos Y Technologia" 211 "Digital Switching Systems" 215 "Xintex/Atena" 224 "EMMI NETWORK" 228 "ZF" 229 "Garmin" 233 "Yacht Monitoring Solutions" 235 "Sailormade Marine Telemetry/Tetra Technology" 243 "Eride" 257 "Honda Motor" 272 "Groco" 273 "Actisense" 274 "Amphenol LTW Technology" 275 "Navico" 283 "Hamilton Jet" 285 "Sea Recovery" 286 "Coelmo SRL Italy" 295 "BEP Marine" 304 "Empir Bus" 305 "NovAtel" 306 "Sleipner Motor" 307 "MBW Technologies" 315 "ICOM" 328 "Qwerty" 329 "Dief" 341 "Boening Automationstechnologie" 345 "Korean Maritime University" 351 "Thrane and Thrane" 355 "Mastervolt" 356 "Fischer Panda Generators" 358 "Victron Energy" 370 "Rolls Royce Marine" 373 "Electronic Design" 374 "Northern Lights" 378 "Glendinning" 381 "B & G" 384 "Rose Point Navigation Systems" 385 "Johnson Outdoors Marine Electronics Inc Geonav" 394 "Capi 2" 396 "Beyond Measure" 400 "Livorsi Marine" 404 "ComNav" 409 "Chetco" 419 "Fusion Electronics" 421 "Standard Horizon" 422 "True Heading" 426 "Egersund Marine Electronics" 427 "em-trak Marine Electronics" 431 "Tohatsu Co, JP" 437 "Digital Yacht" 438 "Comar Systems Limited" 440 "Cummins" 443 "VDO (aka Continental-Corporation)" 451 "Parker Hannifin aka Village Marine Tech" 459 "Alltek Marine Electronics" 460 "SAN GIORGIO S.E.I.N" 466 "Veethree Electronics & Marine" 470 "SI-TEX Marine Electronics" 471 "Sea Cross Marine" 475 "GME aka Standard Communications" 476 "Humminbird Marine Electronics" 478 "Ocean Sat" 481 "Chetco Digital Instruments" 493 "Watcheye" 499 "Lcj Capteurs" 502 "Attwood Marine" 503 "Naviop S.R.L." 504 "Vesper Marine" 510 "Marinesoft" 513 "Simarine" 517 "NoLand Engineering" 518 "Transas USA" 529 "National Instruments Korea" 530 "National Marine Electronics Association" 532 "Onwa Marine" 540 "Webasto" 571 "Marinecraft (South Korea)" 573 "McMurdo Group aka Orolia" 578 "Advansea" 579 "KVH" 580 "San Jose Technology" 583 "Yacht Control" 586 "Suzuki Motor" 591 "US Coast Guard" 595 "Ship Module aka Customware" 600 "Aquatic AV" 605 "Aventics" 606 "Intellian" 612 "SamwonIT" 614 "Arlt Tecnologies" 637 "Bavaria Yachts" 641 "Diverse Yacht Services" 644 "Wema U.S.A dba KUS" 658 "Shenzhen Jiuzhou Himunication" 688 "Rockford" 699 "Harman International" 704 "JL Audio" 708 "Lars Thrane" 715 "Autonnic" 717 "Yacht Devices" 734 "REAP Systems" 735 "AEM Performance Electronics" 739 "LxNav" 741 "Littelfuse, Inc (formerly Carling Technologies)" 743 "DaeMyung" 744 "Woosung" 748 "ISOTTA IFRA srl" 773 "Clarion US" 776 "HMI Systems" 777 "Ocean Signal" 778 "Seakeeper" 781 "Poly Planar" 785 "Fischer Panda DE" 795 "Broyda Industries" 796 "Canadian Automotive" 797 "Tides Marine" 798 "Lumishore" 799 "Still Water Designs and Audio" 802 "BJ Technologies (Beneteau)" 803 "Gill Sensors" 811 "Blue Water Desalination" 815 "FLIR" 824 "Undheim Systems" 826 "Lewmar" 838 "TeamSurv" 844 "Fell Marine" 847 "Oceanvolt" 862 "Prospec" 868 "Data Panel" 890 "L3 Technologies" 894 "Rhodan Marine Systems" 896 "Nexfour Solutions" 905 "ASA Electronics" 909 "Marines Co (South Korea)" 911 "Nautic-on" 917 "Sentinel" 929 "JL Marine Systems" 930 "Ecotronix" 944 "Zontisa Marine" 951 "EXOR International" 962 "Timbolier Industries" 963 "TJC Micro" 968 "Cox Powertrain" 969 "Blue Seas" 981 "Kobelt Manufacturing" 992 "Blue Ocean IOT" 997 "Xenta Systems" 999 "Signal K" 1004 "Ultraflex" 1008 "Lintest SmartBoat" 1011 "Soundmax" 1020 "Team Italia Marine (Onyx Marine Automation s.r.l)" 1021 "Entratech" 1022 "ITC" 1029 "The Marine Guardian" 1047 "Sonic" 1051 "ProNav" 1053 "Vetus Maxwell INC." 1056 "Lithium Pros" 1059 "Boatrax" 1062 "Marol Co ltd" 1065 "CALYPSO Instruments" 1066 "Spot Zero Water" 1069 "Lithionics Battery" 1070 "Quick-teck Electronics" 1075 "Uniden America" 1083 "Nauticoncept" 1084 "Shadow-Caster LED lighting" 1085 "Wet Sounds" 1088 "E-T-A Circuit Breakers" 1092 "Scheiber" 1100 "Smart Yachts International Limited" 1109 "Dockmate" 1114 "Bobs Machine" 1118 "L3Harris ASV" 1119 "Balmar" 1120 "Elettromedia" 1127 "Electromaax" 1140 "Across Oceans Systems" 1145 "Kiwi Yachting" 1150 "BSB Artificial Intelligence" 1151 "Orca Technologies" 1154 "TBS Electronics" 1158 "Technoton Electroics" 1160 "MG Energy Systems" 1169 "Sea Machine Robotics" 1171 "Vista Manufacturing" 1183 "Zipwake" 1186 "Sailmon" 1192 "Airmoniq Pro Kft" 1194 "Sierra Marine" 1200 "Xinuo Information Technology (Xiamen)" 1218 "Septentrio" 1233 "NKE Marine Electronics" 1238 "SuperTrack Aps" 1239 "Honda Electronics" 1245 "Raritan Engineering" 1249 "Integrated Power Solutions AG" 1260 "Interactive Technologies" 1283 "LTG-Tech" 1299 "Energy Solutions (UK)" 1300 "WATT Fuel Cell" 1302 "Pro Mainer" 1305 "Dragonfly Energy" 1306 "Koden Electronics" 1311 "Humphree" 1316 "Hinkley Yachts" 1317 "Global Marine Management GmbH (GMM)" 1320 "Triskel Marine" 1330 "Warwick Control Technologies" 1331 "Dolphin Charger" 1337 "Barnacle Systems" 1348 "Radian IoT" 1353 "Ocean LED Marine" 1359 "BluNav" 1361 "OVA (Nantong Saiyang Electronics Co., Ltd)" 1368 "RAD Propulsion" 1369 "Electric Yacht" 1372 "Elco Motor Yachts" 1384 "Tecnoseal Foundry S.r.l" 1385 "Pro Charging Systems" 1389 "EVEX" 1398 "Gobius Sensor Technology" 1403 "Arco Marine" 1408 "Lenco Marine" 1413 "Naocontrol" 1417 "Revatek" 1438 "Aeolionics" 1439 "PredictWind" 1440 "Egis Mobile Electric" 1445 "Starboard Yacht Group" 1446 "Roswell Marine" 1451 "ePropulsion (Guangdong ePropulsion Technology Ltd.)" 1452 "Micro-Air" 1453 "Vital Battery" 1458 "Ride Controller" 1460 "Tocaro Blue" 1461 "Vanquish Yachts" 1471 "FT Technologies" 1478 "Alps Alpine" 1481 "E-Force Marine" 1482 "CMC Marine" 1483 "Nanjing Sandemarine Information Technology" 1850 "Teleflex Marine (SeaStar Solutions)" 1851 "Raymarine" 1852 "Navionics" 1853 "Japan Radio" 1854 "Northstar Technologies" 1855 "Furuno" 1856 "Trimble" 1857 "Simrad" 1858 "Litton" 1859 "Kvasar" 1860 "MMP" 1861 "Vector Cantech" 1862 "Yamaha Marine" 1863 "Faria Instruments" ;
VAL_ 2583627264 Industry_Code 0 "Global" 1 "Highway" 2 "Agriculture" 3 "Construction" 4 "Marine Industry" 5 "Industrial" ;
VAL_ 2650736128 Manufacturer_Code 69 "ARKS Enterprises" 78 "FW Murphy/Enovation Controls" 80 "Twin Disc" 85 "Kohler Power Systems" 88 "Hemisphere GPS" 135 "Airmar" 137 "Maretron" 140 "Lowrance" 144 "Mercury Marine" 147 "Nautibus Electronic" 148 "Blue Water Data" 154 "Westerbeke" 157 "ISSPRO" 161 "Offshore Systems (UK)" 163 "Evinrude/BRP" 165 "CPAC Systems" 168 "Xantrex Technology" 169 "Marlin Technologies" 172 "Yanmar Marine" 174 "Volvo Penta" 176 "Carling Technologies Inc. (Moritz Aerospace)" 185 "Beede Instruments" 192 "Floscan Instrument" 193 "Nobeltec" 198 "Mystic Valley Communications" 199 "Actia" 201 "Disenos Y Technologia" 211 "Digital Switching Systems" 215 "Xintex/Atena" 224 "EMMI NETWORK" 228 "ZF" 229 "Garmin" 233 "Yacht Monitoring Solutions" 235 "Sailormade Marine Telemetry/Tetra Technology" 243 "Eride" 257 "Honda Motor" 272 "Groco" 273 "Actisense" 274 "Amphenol LTW Technology" 275 "Navico" 283 "Hamilton Jet" 285 "Sea Recovery" 286 "Coelmo SRL Italy" 295 "BEP Marine" 304 "Empir Bus" 305 "NovAtel" 306 "Sleipner Motor" 307 "MBW Technologies" 315 "ICOM" 328 "Qwerty" 329 "Dief" 341 "Boening Automationstechnologie" 345 "Korean Maritime University" 351 "Thrane and Thrane" 355 "Mastervolt" 356 "Fischer Panda Generators" 358 "Victron Energy" 370 "Rolls Royce Marine" 373 "Electronic Design" 374 "Northern Lights" 378 "Glendinning" 381 "B & G" 384 "Rose Point Navigation Systems" 385 "Johnson Outdoors Marine Electronics Inc Geonav" 394 "Capi 2" 396 "Beyond Measure" 400 "Livorsi Marine" 404 "ComNav" 409 "Chetco" 419 "Fusion Electronics" 421 "Standard Horizon" 422 "True Heading" 426 "Egersund Marine Electronics" 427 "em-trak Marine Electronics" 431 "Tohatsu Co, JP" 437 "Digital Yacht" 438 "Comar Systems Limited" 440 "Cummins" 443 "VDO (aka Continental-Corporation)" 451 "Parker Hannifin aka Village Marine Tech" 459 "Alltek Marine Electronics" 460 "SAN GIORGIO S.E.I.N" 466 "Veethree Electronics & Marine" 470 "SI-TEX Marine Electronics" 471 "Sea Cross Marine" 475 "GME aka Standard Communications" 476 "Humminbird Marine Electronics" 478 "Ocean Sat" 481 "Chetco Digital Instruments" 493 "Watcheye" 499 "Lcj Capteurs" 502 "Attwood Marine" 503 "Naviop S.R.L." 504 "Vesper Marine" 510 "Marinesoft" 513 "Simarine" 517 "NoLand Engineering" 518 "Transas USA" 529 "National Instruments Korea" 530 "National Marine Electronics Association" 532 "Onwa Marine" 540 "Webasto" 571 "Marinecraft (South Korea)" 573 "McMurdo Group aka Orolia" 578 "Advansea" 579 "KVH" 580 "San Jose Technology" 583 "Yacht Control" 586 "Suzuki Motor" 591 "US Coast Guard" 595 "Ship Module aka Customware" 600 "Aquatic AV" 605 "Aventics" 606 "Intellian" 612 "SamwonIT" 614 "Arlt Tecnologies" 637 "Bavaria Yachts" 641 "Diverse Yacht Services" 644 "Wema U.S.A dba KUS" 658 "Shenzhen Jiuzhou Himunication" 688 "Rockford" 699 "Harman International" 704 "JL Audio" 708 "Lars Thrane" 715 "Autonnic" 717 "Yacht Devices" 734 "REAP Systems" 735 "AEM Performance Electronics" 739 "LxNav" 741 "Littelfuse, Inc (formerly Carling Technologies)" 743 "DaeMyung" 744 "Woosung" 748 "ISOTTA IFRA srl" 773 "Clarion US" 776 "HMI Systems" 777 "Ocean Signal" 778 "Seakeeper" 781 "Poly Planar" 785 "Fischer Panda DE" 795 "Broyda Industries" 796 "Canadian Automotive" 797 "Tides Marine" 798 "Lumishore" 799 "Still Water Designs and Audio" 802 "BJ Technologies (Beneteau)" 803 "Gill Sensors" 811 "Blue Water Desalination" 815 "FLIR" 824 "Undheim Systems" 826 "Lewmar" 838 "TeamSurv" 844 "Fell Marine" 847 "Oceanvolt" 862 "Prospec" 868 "Data Panel" 890 "L3 Technologies" 894 "Rhodan Marine Systems" 896 "Nexfour Solutions" 905 "ASA Electronics" 909 "Marines Co (South Korea)" 911 "Nautic-on" 917 "Sentinel" 929 "JL Marine Systems" 930 "Ecotronix" 944 "Zontisa Marine" 951 "EXOR International" 962 "Timbolier Industries" 963 "TJC Micro" 968 "Cox Powertrain" 969 "Blue Seas" 981 "Kobelt Manufacturing" 992 "Blue Ocean IOT" 997 "Xenta Systems" 999 "Signal K" 1004 "Ultraflex" 1008 "Lintest SmartBoat" 1011 "Soundmax" 1020 "Team Italia Marine (Onyx Marine Automation s.r.l)" 1021 "Entratech" 1022 "ITC" 1029 "The Marine Guardian" 1047 "Sonic" 1051 "ProNav" 1053 "Vetus Maxwell INC." 1056 "Lithium Pros" 1059 "Boatrax" 1062 "Marol Co ltd" 1065 "CALYPSO Instruments" 1066 "Spot Zero Water" 1069 "Lithionics Battery" 1070 "Quick-teck Electronics" 1075 "Uniden America" 1083 "Nauticoncept" 1084 "Shadow-Caster LED lighting" 1085 "Wet Sounds" 1088 "E-T-A Circuit Breakers" 1092 "Scheiber" 1100 "Smart Yachts International Limited" 1109 "Dockmate" 1114 "Bobs Machine" 1118 "L3Harris ASV" 1119 "Balmar" 1120 "Elettromedia" 1127 "Electromaax" 1140 "Across Oceans Systems" 1145 "Kiwi Yachting" 1150 "BSB Artificial Intelligence" 1151 "Orca Technologies" 1154 "TBS Electronics" 1158 "Technoton Electroics" 1160 "MG Energy Systems" 1169 "Sea Machine Robotics" 1171 "Vista Manufacturing" 1183 "Zipwake" 1186 "Sailmon" 1192 "Airmoniq Pro Kft" 1194 "Sierra Marine" 1200 "Xinuo Information Technology (Xiamen)" 1218 "Septentrio" 1233 "NKE Marine Electronics" 1238 "SuperTrack Aps" 1239 "Honda Electronics" 1245 "Raritan Engineering" 1249 "Integrated Power Solutions AG" 1260 "Interactive Technologies" 1283 "LTG-Tech" 1299 "Energy Solutions (UK)" 1300 "WATT Fuel Cell" 1302 "Pro Mainer" 1305 "Dragonfly Energy" 1306 "Koden Electronics" 1311 "Humphree" 1316 "Hinkley Yachts" 1317 "Global Marine Management GmbH (GMM)" 1320 "Triskel Marine" 1330 "Warwick Control Technologies" 1331 "Dolphin Charger" 1337 "Barnacle Systems" 1348 "Radian IoT" 1353 "Ocean LED Marine" 1359 "BluNav" 1361 "OVA (Nantong Saiyang Electronics Co., Ltd)" 1368 "RAD Propulsion" 1369 "Electric Yacht" 1372 "Elco Motor Yachts" 1384 "Tecnoseal Foundry S.r.l" 1385 "Pro Charging Systems" 1389 "EVEX" 1398 "Gobius Sensor Technology" 1403 "Arco Marine" 1408 "Lenco Marine" 1413 "Naocontrol" 1417 "Revatek" 1438 "Aeolionics" 1439 "PredictWind" 1440 "Egis Mobile Electric" 1445 "Starboard Yacht Group" 1446 "Roswell Marine" 1451 "ePropulsion (Guangdong ePropulsion Technology Ltd.)" 1452 "Micro-Air" 1453 "Vital Battery" 1458 "Ride Controller" 1460 "Tocaro Blue" 1461 "Vanquish Yachts" 1471 "FT Technologies" 1478 "Alps Alpine" 1481 "E-Force Marine" 1482 "CMC Marine" 1483 "Nanjing Sandemarine Information Technology" 1850 "Teleflex Marine (SeaStar Solutions)" 1851 "Raymarine" 1852 "Navionics" 1853 "Japan Radio" 1854 "Northstar Technologies" 1855 "Furuno" 1856 "Trimble" 1857 "Simrad" 1858 "Litton" 1859 "Kvasar" 1860 "MMP" 1861 "Vector Cantech" 1862 "Yamaha Marine" 1863 "Faria Instruments" ;
VAL_ 2650736128 Industry_Code 0 "Global" 1 "Highway" 2 "Agriculture" 3 "Construction" 4 "Marine Industry" 5 "Industrial" ;
VAL_ 2650736128 Alert_Type 1 "Emergency Alarm" 2 "Alarm" 5 "Warning" 8 "Caution" ;
VAL_ 2650736128 Alert_Category 0 "Navigational" 1 "Technical" ;
VAL_ 2583627264 Manufacturer_Code 69 "ARKS Enterprises" 78 "FW Murphy/Enovation Controls" 80 "Twin Disc" 85 "Kohler Power Systems" 88 "Hemisphere GPS" 135 "Airmar" 137 "Maretron" 140 "Lowrance" 144 "Mercury Marine" 147 "Nautibus Electronic" 148 "Blue Water Data" 154 "Westerbeke" 157 "ISSPRO" 161 "Offshore Systems (UK)" 163 "Evinrude/BRP" 165 "CPAC Systems" 168 "Xantrex Technology" 169 "Marlin Technologies" 172 "Yanmar Marine" 174 "Volvo Penta" 176 "Carling Technologies Inc. (Moritz Aerospace)" 185 "Beede Instruments" 192 "Floscan Instrument" 193 "Nobeltec" 198 "Mystic Valley Communications" 199 "Actia" 201 "Disenos Y Technologia" 211 "Digital Switching Systems" 215 "Xintex/Atena" 224 "EMMI NETWORK" 228 "ZF" 229 "Garmin" 233 "Yacht Monitoring Solutions" 235 "Sailormade Marine Telemetry/Tetra Technology" 243 "Eride" 257 "Honda Motor" 272 "Groco" 273 "Actisense" 274 "Amphenol LTW Technology" 275 "Navico" 283 "Hamilton Jet" 285 "Sea Recovery" 286 "Coelmo SRL Italy" 295 "BEP Marine" 304 "Empir Bus" 305 "NovAtel" 306 "Sleipner Motor" 307 "MBW Technologies" 315 "ICOM" 328 "Qwerty" 329 "Dief" 341 "Boening Automationstechnologie" 345 "Korean Maritime University" 351 "Thrane and Thrane" 355 "Mastervolt" 356 "Fischer Panda Generators" 358 "Victron Energy" 370 "Rolls Royce Marine" 373 "Electronic Design" 374 "Northern Lights" 378 "Glendinning" 381 "B & G" 384 "Rose Point Navigation Systems" 385 "Johnson Outdoors Marine Electronics Inc Geonav" 394 "Capi 2" 396 "Beyond Measure" 400 "Livorsi Marine" 404 "ComNav" 409 "Chetco" 419 "Fusion Electronics" 421 "Standard Horizon" 422 "True Heading" 426 "Egersund Marine Electronics" 427 "em-trak Marine Electronics" 431 "Tohatsu Co, JP" 437 "Digital Yacht" 438 "Comar Systems Limited" 440 "Cummins" 443 "VDO (aka Continental-Corporation)" 451 "Parker Hannifin aka Village Marine Tech" 459 "Alltek Marine Electronics" 460 "SAN GIORGIO S.E.I.N" 466 "Veethree Electronics & Marine" 470 "SI-TEX Marine Electronics" 471 "Sea Cross Marine" 475 "GME aka Standard Communications" 476 "Humminbird Marine Electronics" 478 "Ocean Sat" 481 "Chetco Digital Instruments" 493 "Watcheye" 499 "Lcj Capteurs" 502 "Attwood Marine" 503 "Naviop S.R.L." 504 "Vesper Marine" 510 "Marinesoft" 513 "Simarine" 517 "NoLand Engineering" 518 "Transas USA" 529 "National Instruments Korea" 530 "National Marine Electronics Association" 532 "Onwa Marine" 540 "Webasto" 571 "Marinecraft (South Korea)" 573 "McMurdo Group aka Orolia" 578 "Advansea" 579 "KVH" 580 "San Jose Technology" 583 "Yacht Control" 586 "Suzuki Motor" 591 "US Coast Guard" 595 "Ship Module aka Customware" 600 "Aquatic AV" 605 "Aventics" 606 "Intellian" 612 "SamwonIT" 614 "Arlt Tecnologies" 637 "Bavaria Yachts" 641 "Diverse Yacht Services" 644 "Wema U.S.A dba KUS" 658 "Shenzhen Jiuzhou Himunication" 688 "Rockford" 699 "Harman International" 704 "JL Audio" 708 "Lars Thrane" 715 "Autonnic" 717 "Yacht Devices" 734 "REAP Systems" 735 "AEM Performance Electronics" 739 "LxNav" 741 "Littelfuse, Inc (formerly Carling Technologies)" 743 "DaeMyung" 744 "Woosung" 748 "ISOTTA IFRA srl" 773 "Clarion US" 776 "HMI Systems" 777 "Ocean Signal" 778 "Seakeeper" 781 "Poly Planar" 785 "Fischer Panda DE" 795 "Broyda Industries" 796 "Canadian Automotive" 797 "Tides Marine" 798 "Lumishore" 799 "Still Water Designs and Audio" 802 "BJ Technologies (Beneteau)" 803 "Gill Sensors" 811 "Blue Water Desalination" 815 "FLIR" 824 "Undheim Systems" 826 "Lewmar" 838 "TeamSurv" 844 "Fell Marine" 847 "Oceanvolt" 862 "Prospec" 868 "Data Panel" 890 "L3 Technologies" 894 "Rhodan Marine Systems" 896 "Nexfour Solutions" 905 "ASA Electronics" 909 "Marines Co (South Korea)" 911 "Nautic-on" 917 "Sentinel" 929 "JL Marine Systems" 930 "Ecotronix" 944 "Zontisa Marine" 951 "EXOR International" 962 "Timbolier Industries" 963 "TJC Micro" 968 "Cox Powertrain" 969 "Blue Seas" 981 "Kobelt Manufacturing" 992 "Blue Ocean IOT" 997 "Xenta Systems" 999 "Signal K" 1004 "Ultraflex" 1008 "Lintest SmartBoat" 1011 "Soundmax" 1020 "Team Italia Marine (Onyx Marine Automation s.r.l)" 1021 "Entratech" 1022 "ITC" 1029 "The Marine Guardian" 1047 "Sonic" 1051 "ProNav" 1053 "Vetus Maxwell INC." 1056 "Lithium Pros" 1059 "Boatrax" 1062 "Marol Co ltd" 1065 "CALYPSO Instruments" 1066 "Spot Zero Water" 1069 "Lithionics Battery" 1070 "Quick-teck Electronics" 1075 "Uniden America" 1083 "Nauticoncept" 1084 "Shadow-Caster LED lighting" 1085 "Wet Sounds" 1088 "E-T-A Circuit Breakers" 1092 "Scheiber" 1100 "Smart Yachts International Limited" 1109 "Dockmate" 1114 "Bobs Machine" 1118 "L3Harris ASV" 1119 "Balmar" 1120 "Elettromedia" 1127 "Electromaax" 1140 "Across Oceans Systems" 1145 "Kiwi Yachting" 1150 "BSB Artificial Intelligence" 1151 "Orca Technologies" 1154 "TBS Electronics" 1158 "Technoton Electroics" 1160 "MG Energy Systems" 1169 "Sea Machine Robotics" 1171 "Vista Manufacturing" 1183 "Zipwake" 1186 "Sailmon" 1192 "Airmoniq Pro Kft" 1194 "Sierra Marine" 1200 "Xinuo Information Technology (Xiamen)" 1218 "Septentrio" 1233 "NKE Marine Electronics" 1238 "SuperTrack Aps" 1239 "Honda Electronics" 1245 "Raritan Engineering" 1249 "Integrated Power Solutions AG" 1260 "Interactive Technologies" 1283 "LTG-Tech" 1299 "Energy Solutions (UK)" 1300 "WATT Fuel Cell" 1302 "Pro Mainer" 1305 "Dragonfly Energy" 1306 "Koden Electronics" 1311 "Humphree" 1316 "Hinkley Yachts" 1317 "Global Marine Management GmbH (GMM)" 1320 "Triskel Marine" 1330 "Warwick Control Technologies" 1331 "Dolphin Charger" 1337 "Barnacle Systems" 1348 "Radian IoT" 1353 "Ocean LED Marine" 1359 "BluNav" 1361 "OVA (Nantong Saiyang Electronics Co., Ltd)" 1368 "RAD Propulsion" 1369 "Electric Yacht" 1372 "Elco Motor Yachts" 1384 "Tecnoseal Foundry S.r.l" 1385 "Pro Charging Systems" 1389 "EVEX" 1398 "Gobius Sensor Technology" 1403 "Arco Marine" 1408 "Lenco Marine" 1413 "Naocontrol" 1417 "Revatek" 1438 "Aeolionics" 1439 "PredictWind" 1440 "Egis Mobile Electric" 1445 "Starboard Yacht Group" 1446 "Roswell Marine" 1451 "ePropulsion (Guangdong ePropulsion Technology Ltd.)" 1452 "Micro-Air" 1453 "Vital Battery" 1458 "Ride Controller" 1460 "Tocaro Blue" 1461 "Vanquish Yachts" 1471 "FT Technologies" 1478 "Alps Alpine" 1481 "E-Force Marine" 1482 "CMC Marine" 1483 "Nanjing Sandemarine Information Technology" 1850 "Teleflex Marine (SeaStar Solutions)" 1851 "Raymarine" 1852 "Navionics" 1853 "Japan Radio" 1854 "Northstar Technologies" 1855 "Furuno" 1856 "Trimble" 1857 "Simrad" 1858 "Litton" 1859 "Kvasar" 1860 "MMP" 1861 "Vector Cantech" 1862 "Yamaha Marine" 1863 "Faria Instruments" ;
VAL_ 2583627264 Industry_Code 0 "Global" 1 "Highway" 2 "Agriculture" 3 "Construction" 4 "Marine Industry" 5 "Industrial" ;
CM_ SG_ 2650735872 Alert_Text_Description "STRING field: decode bytes as ASCII (0x00/@/0xFF = terminator); canboat type: STRING_LAU";
CM_ SG_ 2650735872 Alert_Location_Text_Description "STRING field: decode bytes as ASCII (0x00/@/0xFF = terminator); canboat type: STRING_LAU";
CM_ SG_ 2650735872 Message "STRING field: decode bytes as ASCII (0x00/@/0xFF = terminator); canboat type: STRING_FIX";

BA_DEF_ BO_ "GenMsgCycleTime" INT 0 60000;
BA_DEF_ BO_ "ProtocolType" STRING;

BA_DEF_ BO_ "J1939PGN" INT 0 262143;
BA_ "J1939PGN" BO_ 2583627008 130821;
BA_ "J1939PGN" BO_ 2650735872 130821;
BA_ "J1939PGN" BO_ 2650735872 130821;
BA_ "J1939PGN" BO_ 2650735872 130821;
BA_ "J1939PGN" BO_ 2583627264 130822;
BA_ "J1939PGN" BO_ 2650736128 130822;
BA_ "J1939PGN" BO_ 2583627264 130822;
